VERSION ""

NS_ :

BS_:

BU_: VCM SCIM IC CCM

BO_ 689 VCM_13P_C05: 8 VCM
 SG_ ParkHeaterTimerReleased_stat : 54|2@1+ (1,0) [0|0] ""  CCM
 SG_ Trail2TPMLostCom : 2|2@1+ (1,0) [0|0] ""  IC
 SG_ BrakeInterlockStatus_ISig_5 : 42|2@1+ (1,0) [0|0] ""  IC
 SG_ AutoWheelBrakesDownshiftSugges_I : 36|2@1+ (1,0) [0|0] ""  IC
 SG_ RearAxle2DiffLock_stat_ISig_5 : 34|2@1+ (1,0) [0|0] ""  IC
 SG_ CentralRearDiffLock_stat_ISig_5 : 16|2@1+ (1,0) [0|0] ""  IC
 SG_ TransmissionBrakeMode_ISig_5 : 56|2@1+ (1,0) [0|0] ""  IC
 SG_ PS_HeadLightAdjustment : 14|2@1+ (1,0) [0|0] ""  IC
 SG_ ReducedLoadMode_stat_ISig_5 : 62|2@1+ (1,0) [0|0] ""  IC,CCM
 SG_ FrontWheelDifflockRequest_ISig_5 : 6|2@1+ (1,0) [0|0] ""  IC
 SG_ ABSEBSAmberWarningSignal_ISig_5 : 44|2@1+ (1,0) [0|0] ""  IC
 SG_ DifferentialLockStateFrAxle1_ISi : 32|2@1+ (1,0) [0|0] ""  IC
 SG_ Trail1TPMLostCom : 12|2@1+ (1,0) [0|0] ""  IC
 SG_ TrailerInflationPossible_stat_IS : 50|2@1+ (1,0) [0|0] ""  IC
 SG_ DrivelineRetarderStat_ISig_5 : 24|2@1+ (1,0) [0|0] ""  IC
 SG_ PS_FogLightRear : 4|2@1+ (1,0) [0|0] ""  IC
 SG_ PS_MainBeam : 22|2@1+ (1,0) [0|0] ""  IC
 SG_ DeCompActive_ISig_5 : 26|2@1+ (1,0) [0|0] ""  IC
 SG_ ECSManStandbyStatus_ISig_5 : 30|2@1+ (1,0) [0|0] ""  IC
 SG_ AutoPBRelease_stat_ISig_5 : 46|2@1+ (1,0) [0|0] ""  IC
 SG_ Trail4TPMLostCom : 28|2@1+ (1,0) [0|0] ""  IC
 SG_ EBSRedWarningSignal_ISig_5 : 40|2@1+ (1,0) [0|0] ""  IC
 SG_ DifferentialLockStateCentral_ISi : 52|2@1+ (1,0) [0|0] ""  IC
 SG_ RearAxle3DiffLock_stat_ISig_5 : 20|2@1+ (1,0) [0|0] ""  IC
 SG_ AntiLockBrakingActive_ISig_5 : 10|2@1+ (1,0) [0|0] ""  IC
 SG_ RearAxle1DiffLock_stat_ISig_5 : 0|2@1+ (1,0) [0|0] ""  IC
 SG_ Trail5TPMLostCom : 48|2@1+ (1,0) [0|0] ""  IC
 SG_ PS_PositionLight : 58|2@1+ (1,0) [0|0] ""  IC
 SG_ BatteryCapacity_Ack_ISig_5 : 8|2@1+ (1,0) [0|0] ""  IC
 SG_ Trail3TPMLostCom : 60|2@1+ (1,0) [0|0] ""  IC
 SG_ ParkBrakeWorkshopMode_ISig_5 : 18|2@1+ (1,0) [0|0] ""  IC
 SG_ LowTempClutchInfo_ISig_5 : 38|2@1+ (1,0) [0|0] ""  IC

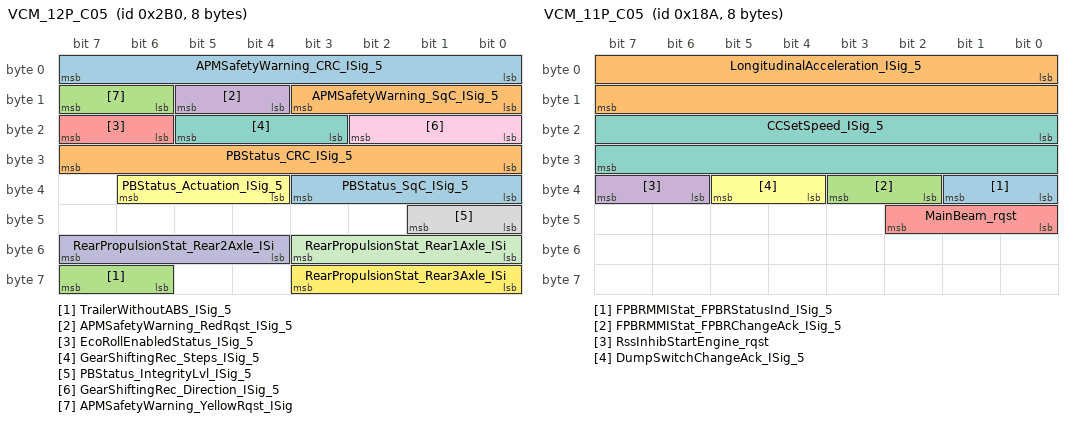
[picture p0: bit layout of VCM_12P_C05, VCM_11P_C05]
BO_ 688 VCM_12P_C05: 8 VCM
 SG_ APMSafetyWarning_CRC_ISig_5 : 0|8@1+ (1,0) [0|255] ""  IC
 SG_ PBStatus_CRC_ISig_5 : 24|8@1+ (1,0) [0|255] ""  IC
 SG_ TrailerWithoutABS_ISig_5 : 62|2@1+ (1,0) [0|0] ""  IC
 SG_ APMSafetyWarning_RedRqst_ISig_5 : 12|2@1+ (1,0) [0|0] ""  IC
 SG_ EcoRollEnabledStatus_ISig_5 : 22|2@1+ (1,0) [0|0] ""  IC
 SG_ PBStatus_Actuation_ISig_5 : 36|3@1+ (1,0) [0|0] ""  IC
 SG_ GearShiftingRec_Steps_ISig_5 : 19|3@1+ (1,0) [0|0] ""  IC
 SG_ PBStatus_IntegrityLvl_ISig_5 : 40|2@1+ (1,0) [0|0] ""  IC
 SG_ GearShiftingRec_Direction_ISig_5 : 16|3@1+ (1,0) [0|0] ""  IC
 SG_ RearPropulsionStat_Rear2Axle_ISi : 52|4@1+ (1,0) [0|0] ""  IC
 SG_ RearPropulsionStat_Rear1Axle_ISi : 48|4@1+ (1,0) [0|0] ""  IC
 SG_ RearPropulsionStat_Rear3Axle_ISi : 56|4@1+ (1,0) [0|0] ""  IC
 SG_ PBStatus_SqC_ISig_5 : 32|4@1+ (1,0) [0|14] "NotApplicable"  IC
 SG_ APMSafetyWarning_SqC_ISig_5 : 8|4@1+ (1,0) [0|14] "NotApplicable"  IC
 SG_ APMSafetyWarning_YellowRqst_ISig : 14|2@1+ (1,0) [0|0] ""  IC

BO_ 394 VCM_11P_C05: 8 VCM
 SG_ FPBRMMIStat_FPBRStatusInd_ISig_5 : 32|2@1+ (1,0) [0|0] ""  SCIM
 SG_ LongitudinalAcceleration_ISig_5 : 0|16@1+ (0.00048828125,-15.687) [-15.687|16.31251171875] "m_per_s_squared"  IC
 SG_ FPBRMMIStat_FPBRChangeAck_ISig_5 : 34|2@1+ (1,0) [0|0] ""  SCIM
 SG_ RssInhibStartEngine_rqst : 38|2@1+ (1,0) [0|0] ""  IC
 SG_ MainBeam_rqst : 40|3@1+ (1,0) [0|0] ""  IC
 SG_ DumpSwitchChangeAck_ISig_5 : 36|2@1+ (1,0) [0|0] ""  SCIM
 SG_ CCSetSpeed_ISig_5 : 16|16@1+ (0.00390625,0) [0|255.99609375] "Km_per_h"  IC

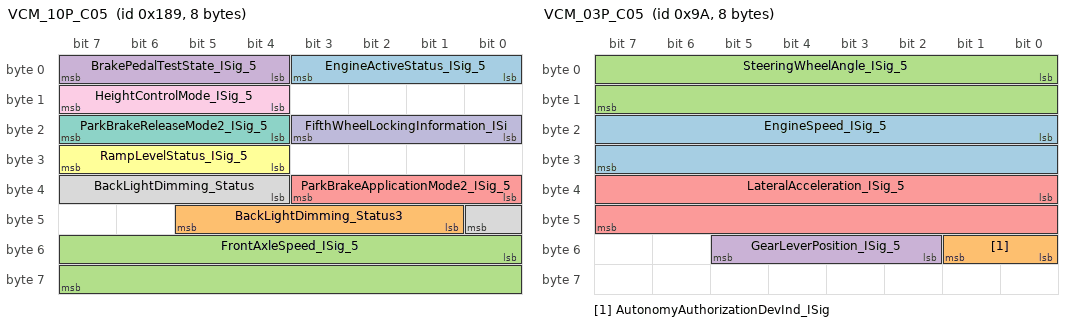
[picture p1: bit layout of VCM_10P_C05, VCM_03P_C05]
BO_ 393 VCM_10P_C05: 8 VCM
 SG_ EngineActiveStatus_ISig_5 : 0|4@1+ (1,0) [0|0] ""  IC
 SG_ BackLightDimming_Status3 : 41|5@1+ (1,0) [0|0] ""  IC
 SG_ FrontAxleSpeed_ISig_5 : 48|16@1+ (0.00390625,0) [0|255.99609375] "Km_per_h"  IC
 SG_ BrakePedalTestState_ISig_5 : 4|4@1+ (1,0) [0|0] ""  IC
 SG_ ParkBrakeApplicationMode2_ISig_5 : 32|4@1+ (1,0) [0|0] ""  IC
 SG_ RampLevelStatus_ISig_5 : 28|4@1+ (1,0) [0|0] ""  IC
 SG_ ParkBrakeReleaseMode2_ISig_5 : 20|4@1+ (1,0) [0|0] ""  IC
 SG_ BackLightDimming_Status : 36|5@1+ (1,0) [0|0] ""  IC
 SG_ HeightControlMode_ISig_5 : 12|4@1+ (1,0) [0|0] ""  IC
 SG_ FifthWheelLockingInformation_ISi : 16|4@1+ (1,0) [0|0] ""  IC

BO_ 392 VCM_09P_C05: 8 VCM
 SG_ FirstAxleLowerPrioSelected_ISig_ : 48|3@1+ (1,0) [0|0] ""  IC
 SG_ ESCState_ISig_5 : 24|3@1+ (1,0) [0|0] ""  IC
 SG_ KneelingInformation_ISig_5 : 60|4@1+ (1,0) [0|0] ""  IC
 SG_ TrailerTest_stat_ISig_5 : 42|3@1+ (1,0) [0|0] ""  IC
 SG_ ThreePosDifflockSwitch_stat : 3|3@1+ (1,0) [0|0] ""  IC
 SG_ HillHolderMode_ISig_5 : 36|3@1+ (1,0) [0|0] ""  IC
 SG_ RampHeightOutsideTargetRange_ISi : 21|3@1+ (1,0) [0|0] ""  IC
 SG_ ShortStopHeater_status_ISig_5 : 39|3@1+ (1,0) [0|0] ""  CCM
 SG_ LuggageAjar_stat : 15|3@1+ (1,0) [0|0] ""  IC
 SG_ LoadDistributionRequestedACK_ISi : 12|3@1+ (1,0) [0|0] ""  SCIM,IC
 SG_ StretchBrake_Stat_ISig_5 : 54|3@1+ (1,0) [0|0] ""  IC
 SG_ MirrorHeatingMode : 9|3@1+ (1,0) [0|0] ""  IC,CCM
 SG_ ESCStatus_ISig_5 : 6|3@1+ (1,0) [0|0] ""  IC
 SG_ DriverRetarderRequest_ISig_5 : 30|3@1+ (1,0) [0|0] ""  IC
 SG_ PBReleaseAcceptance_stat_ISig_5 : 18|3@1+ (1,0) [0|0] ""  IC
 SG_ PSWindowPosition : 0|3@1+ (1,0) [0|0] ""  CCM
 SG_ RideHeightOutsideTargetRange_ISi : 27|3@1+ (1,0) [0|0] ""  IC
 SG_ DriveLevelPosUserInteraction_ISi : 45|3@1+ (1,0) [0|0] ""  IC
 SG_ HillStartAidStatus_ISig_5 : 51|3@1+ (1,0) [0|0] ""  IC

BO_ 391 VCM_08P_C05: 8 VCM
 SG_ AcceleratorPedalTestStatus : 38|3@1+ (1,0) [0|0] ""  IC
 SG_ ESCDriverReq_ISig_5 : 41|3@1+ (1,0) [0|0] ""  IC
 SG_ UnevenLoadWarning_ISig_5 : 12|2@1+ (1,0) [0|0] ""  IC
 SG_ RrInterAxlDiffLockActvnFuncReq_I : 4|2@1+ (1,0) [0|0] ""  IC
 SG_ DoorsAjar_stat_ISig_5 : 44|3@1+ (1,0) [0|0] ""  IC
 SG_ ABSManAutoInhibitionStat_ISig_5 : 50|3@1+ (1,0) [0|0] ""  IC
 SG_ RrInterAxlDiffLockActvnDrvrReq_I : 2|2@1+ (1,0) [0|0] ""  IC
 SG_ EngineOilTempHigh_ISig_5 : 59|3@1+ (1,0) [0|0] ""  IC
 SG_ StartupProhibitStatus_ISig_5 : 0|2@1+ (1,0) [0|0] ""  IC
 SG_ AuxBrakesDwngrdModeInd_rqst : 26|3@1+ (1,0) [0|0] ""  IC
 SG_ ElectricalLoadReduction_rqst_ISi : 32|3@1+ (1,0) [0|0] ""  CCM
 SG_ LoadDistributionChangeACK_ISig_5 : 20|3@1+ (1,0) [0|0] ""  IC,SCIM
 SG_ FerryFunctionStatus_ISig_5 : 29|3@1+ (1,0) [0|0] ""  SCIM,IC
 SG_ ClutchOverloadStatus_ISig_5 : 10|2@1+ (1,0) [0|0] ""  IC
 SG_ RollerBenchModeStatus_ISig_5 : 6|2@1+ (1,0) [0|0] ""  IC
 SG_ LoadDistributionALDChangeACK_ISi : 35|3@1+ (1,0) [0|0] ""  IC,SCIM
 SG_ EngineSpeedControlStatus : 47|3@1+ (1,0) [0|0] ""  IC
 SG_ DTCActive_ISig_5 : 8|2@1+ (1,0) [0|0] ""  IC

BO_ 390 VCM_07P_C05: 8 VCM
 SG_ PS_SevereEngAndBrkOverspdWarn_IS : 6|2@1+ (1,0) [0|0] ""  IC
 SG_ RearFog_Indication : 14|2@1+ (1,0) [0|0] ""  SCIM
 SG_ SasAdaptationInProgress_ISig_5 : 46|2@1+ (1,0) [0|0] ""  IC
 SG_ SplitBoxDifflockActvnDrvrRqst_IS : 50|2@1+ (1,0) [0|0] ""  IC
 SG_ EcoRollActiveStatus_ISig_5 : 36|2@1+ (1,0) [0|0] ""  IC
 SG_ PloughLampModeStatus_ISig_5 : 40|2@1+ (1,0) [0|0] ""  IC
 SG_ RrRrItrWhlDiffLckActvnDrvrReq_IS : 26|2@1+ (1,0) [0|0] ""  IC
 SG_ DrvrRetarderBrakeProgram_rqst_IS : 62|2@1+ (1,0) [0|0] ""  IC
 SG_ PS_EngOverSpeedSevereWarning_ISi : 38|2@1+ (1,0) [0|0] ""  IC
 SG_ ParkBrakeReleasePossible_stat_IS : 32|2@1+ (1,0) [0|0] ""  IC
 SG_ StoreIdleValue_ISig_5 : 34|2@1+ (1,0) [0|0] ""  IC
 SG_ AutRrAxleDiffLockActvnDrvrReq_IS : 42|2@1+ (1,0) [0|0] ""  IC
 SG_ TransmLowRangeSenseSwitch_ISig_5 : 28|2@1+ (1,0) [0|0] ""  IC
 SG_ PBStatusDisplay_cmd_ISig_5 : 44|2@1+ (1,0) [0|0] ""  IC
 SG_ AutoRearAxleDiffLockFnc_stat_ISi : 56|2@1+ (1,0) [0|0] ""  IC
 SG_ PoorBrakePerformanceWarning_ISig : 8|2@1+ (1,0) [0|0] ""  IC
 SG_ FrontParkBrakeOverrideInd_ISig_5 : 52|2@1+ (1,0) [0|0] ""  IC
 SG_ ProhibitControlStatus_ISig_5 : 10|2@1+ (1,0) [0|0] ""  IC
 SG_ PositionLightRequest_status : 2|2@1+ (1,0) [0|0] ""  IC
 SG_ DoubleFrontAxleSteeringWarning_I : 54|2@1+ (1,0) [0|0] ""  IC
 SG_ TrailerABSStatus_ISig_5 : 20|2@1+ (1,0) [0|0] ""  IC
 SG_ LoadCutOffIndication_cmd_ISig_5 : 60|2@1+ (1,0) [0|0] ""  IC
 SG_ PtosStatus_ISig_5 : 12|2@1+ (1,0) [0|0] ""  IC,CCM
 SG_ REM_PhoneButtonInd_cmd : 58|2@1+ (1,0) [0|0] ""  IC
 SG_ TrailerBrake_Stat_ISig_5 : 48|2@1+ (1,0) [0|0] ""  IC
 SG_ SEM2_PhoneButtonInd_cmd : 30|2@1+ (1,0) [0|0] ""  IC
 SG_ GearRangeUnengaged_ISig_5 : 16|2@1+ (1,0) [0|0] ""  IC
 SG_ ABSOffRoadStatus_ISig_5 : 24|2@1+ (1,0) [0|0] ""  IC
 SG_ DrvrRetarderBrakeBlending_rqst_I : 18|2@1+ (1,0) [0|0] ""  IC

BO_ 389 VCM_06P_C05: 8 VCM
 SG_ PHTimerRqstAck_Minutes : 24|8@1+ (1,0) [0|255] "min"  CCM
 SG_ RearAxleDiffLockActvnDrvrReq_ISi : 56|2@1+ (1,0) [0|0] ""  IC
 SG_ FrRrItrWhlDiffLckActvnDrvrReq_IS : 46|2@1+ (1,0) [0|0] ""  IC
 SG_ DriverLocation_CRC_ISig_5 : 0|8@1+ (1,0) [0|255] ""  IC
 SG_ RegenInhibDueHeight_ISig_5 : 48|2@1+ (1,0) [0|0] ""  IC
 SG_ DriverLocation_Status_ISig_5 : 12|4@1+ (1,0) [0|0] ""  IC
 SG_ PHTimerRqstAck_Hours : 32|8@1+ (1,0) [0|255] "h"  CCM
 SG_ PoorAirPressureInfo_ISig_5 : 60|2@1+ (1,0) [0|0] ""  IC
 SG_ DriverLocation_SqC_ISig_5 : 8|4@1+ (1,0) [0|14] "NotApplicable"  IC
 SG_ XRSLControllerMode_ISig_5 : 52|2@1+ (1,0) [0|0] ""  IC
 SG_ PHTimerRqstAck_DayOfWeekRq : 40|4@1+ (1,0) [0|0] ""  CCM
 SG_ VIN_rqst_ISig_5 : 62|1@1+ (1,0) [0|0] ""  IC
 SG_ PHTimerRqstAck_CurrentOp : 44|2@1+ (1,0) [0|0] ""  CCM
 SG_ DriverLocation_ConfidenceLvl_ISi : 16|2@1+ (1,0) [0|0] ""  IC
 SG_ PS_EngineBrakeOverSpeedWarning_I : 58|2@1+ (1,0) [0|0] ""  IC
 SG_ TrcnCtrlSlipperyRoadWarning_ISig : 50|2@1+ (1,0) [0|0] ""  IC
 SG_ TransmissionAirPressureLow_ISig_ : 54|2@1+ (1,0) [0|0] ""  IC

BO_ 158 VCM_05P_C05: 8 VCM
 SG_ SecuredNeutralPosition_ISig_5 : 38|2@1+ (1,0) [0|0] ""  IC
 SG_ MirrorSelectLeftWideBtn_stat : 28|2@1+ (1,0) [0|0] ""  IC
 SG_ BunkH1AudioOnOff_ButtonStatus : 30|2@1+ (1,0) [0|0] ""  IC
 SG_ OverSteerGuidanceStatus_ISig_5 : 10|2@1+ (1,0) [0|0] ""  IC
 SG_ MirrorSelectLeftMainBtn_stat : 44|2@1+ (1,0) [0|0] ""  IC
 SG_ LECM_CabClim_Auto_BtnStat : 36|2@1+ (1,0) [0|0] ""  IC
 SG_ LECM_Display_Navi_OK_BtnStat : 20|2@1+ (1,0) [0|0] ""  IC
 SG_ LECM_CabClim_AC_BtnStat : 46|2@1+ (1,0) [0|0] ""  IC
 SG_ LECMCabClimSetTempSelectGuiReq : 22|2@1+ (1,0) [0|0] ""  IC
 SG_ MirrorSelectRightMainBtn_stat : 50|2@1+ (1,0) [0|0] ""  IC
 SG_ DaytimeRunningLight_Indication : 24|2@1+ (1,0) [0|0] ""  SCIM
 SG_ DrivingLight_Indication : 58|2@1+ (1,0) [0|0] ""  SCIM
 SG_ FrontFog_Indication : 32|2@1+ (1,0) [0|0] ""  SCIM
 SG_ KeyfobPreTripButtonStatus : 4|2@1+ (1,0) [0|0] ""  IC
 SG_ MirrorSelectRightWideBtn_stat : 26|2@1+ (1,0) [0|0] ""  IC
 SG_ ParkingLight_Indication : 2|2@1+ (1,0) [0|0] ""  SCIM
 SG_ DrivingLightPlus_Indication : 60|2@1+ (1,0) [0|0] ""  SCIM
 SG_ BlackPanelMode_ButtonStatus : 14|2@1+ (1,0) [0|0] ""  IC
 SG_ ParkBrakeActuationStatus_ISig_5 : 16|3@1+ (1,0) [0|0] ""  CCM
 SG_ LECM_CabClim_FrPwr_BtnStat : 34|2@1+ (1,0) [0|0] ""  IC
 SG_ LECM_CabClim_Pwr_BtnStat : 0|2@1+ (1,0) [0|0] ""  IC
 SG_ BlackPanelMode_ButtonStatus3 : 8|2@1+ (1,0) [0|0] ""  IC
 SG_ LECM_CabClim_Sync_GuiReq : 40|2@1+ (1,0) [0|0] ""  IC
 SG_ LiftAxle1AutoLiftSelected_ISig_5 : 54|2@1+ (1,0) [0|0] ""  IC
 SG_ LECM_Ent_OnOff_BtnStat : 52|2@1+ (1,0) [0|0] ""  IC

BO_ 156 VCM_04P_C05: 8 VCM
 SG_ LiftAxle2LowerACK_ISig_5 : 32|3@1+ (1,0) [0|0] ""  IC
 SG_ LiftAxle2PositionStatus_ISig_5 : 20|3@1+ (1,0) [0|0] ""  IC,SCIM
 SG_ LiftAxle2LiftFuncSelected_ISig_5 : 53|3@1+ (1,0) [0|0] ""  IC
 SG_ PassengerDoorAjar_stat : 35|3@1+ (1,0) [0|0] ""  CCM
 SG_ LevelControlInformation_ISig_5 : 56|4@1+ (1,0) [0|0] ""  IC,SCIM
 SG_ LiftAxle1LowerACK_ISig_5 : 38|3@1+ (1,0) [0|0] ""  IC
 SG_ WiperModeStatus_ISig_5 : 41|3@1+ (1,0) [0|0] ""  IC,CCM
 SG_ Washing_HMI_rqst : 60|2@1+ (1,0) [0|0] ""  CCM
 SG_ LiftAxle2AutoLiftSelected_ISig_5 : 8|2@1+ (1,0) [0|0] ""  IC
 SG_ ReverseGearEngaged_ISig_5 : 10|2@1+ (1,0) [0|0] ""  CCM
 SG_ LiftAxle1PositionStatus_ISig_5 : 17|3@1+ (1,0) [0|0] ""  SCIM,IC
 SG_ ACC_Status_ISig_5 : 47|3@1+ (1,0) [0|0] ""  IC
 SG_ LECM_CabClim_MaxDef_GuiReq : 6|2@1+ (1,0) [0|0] ""  IC
 SG_ RegenerationSwitchStatus : 23|3@1+ (1,0) [0|0] ""  IC
 SG_ DSWindowPosition : 29|3@1+ (1,0) [0|0] ""  CCM
 SG_ GearSplit_Status_ISig_5 : 0|2@1+ (1,0) [0|0] ""  IC
 SG_ KeyPosition_ISig_5 : 44|3@1+ (1,0) [0|0] ""  IC
 SG_ LiftAxle1LiftFuncSelected_ISig_5 : 50|3@1+ (1,0) [0|0] ""  IC
 SG_ LiftAxle2UpRequestACK_ISig_5 : 26|3@1+ (1,0) [0|0] ""  SCIM,IC
 SG_ PreTrip_ButtonStat3 : 12|2@1+ (1,0) [0|0] ""  IC
 SG_ LiftAxle1UpRequestACK_ISig_5 : 14|3@1+ (1,0) [0|0] ""  SCIM,IC

BO_ 154 VCM_03P_C05: 8 VCM
 SG_ EngineSpeed_ISig_5 : 16|16@1+ (0.125,0) [0|8191.875] "rpm"  IC,CCM
 SG_ AutonomyAuthorizationDevInd_ISig : 48|2@1+ (1,0) [0|0] ""  SCIM
 SG_ SteeringWheelAngle_ISig_5 : 0|16@1+ (0.0009765625,-31.374) [-31.374|32.6250234375] "rad"  IC
 SG_ GearLeverPosition_ISig_5 : 50|4@1+ (1,0) [0|0] ""  IC
 SG_ LateralAcceleration_ISig_5 : 32|16@1+ (0.00048828125,-15.687) [-15.687|16.31251171875] "m_per_s_squared"  IC

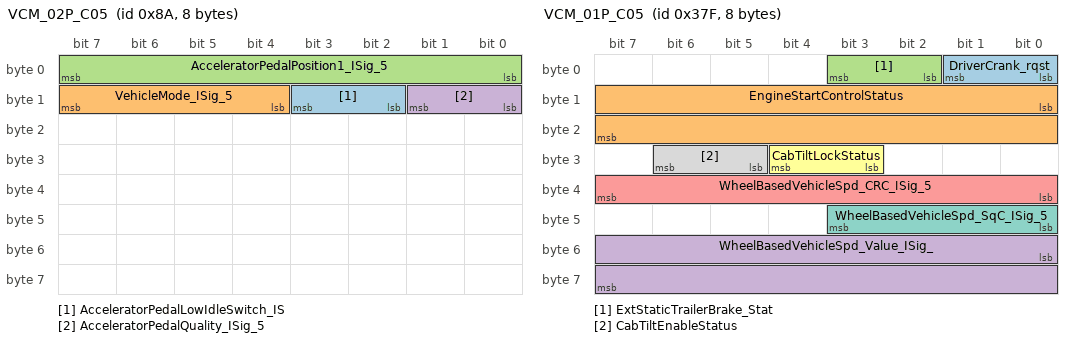
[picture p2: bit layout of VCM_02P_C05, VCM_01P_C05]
BO_ 138 VCM_02P_C05: 8 VCM
 SG_ AcceleratorPedalLowIdleSwitch_IS : 10|2@1+ (1,0) [0|0] ""  IC
 SG_ VehicleMode_ISig_5 : 12|4@1+ (1,0) [0|0] ""  SCIM,IC,CCM
 SG_ AcceleratorPedalPosition1_ISig_5 : 0|8@1+ (0.4,0) [0|102] "Percent"  IC
 SG_ AcceleratorPedalQuality_ISig_5 : 8|2@1+ (1,0) [0|0] ""  IC

BO_ 895 VCM_01P_C05: 8 VCM
 SG_ DriverCrank_rqst : 0|2@1+ (1,0) [0|0] ""  IC
 SG_ EngineStartControlStatus : 8|16@1+ (1,0) [0|65535] "NotApplicable"  IC
 SG_ ExtStaticTrailerBrake_Stat : 2|2@1+ (1,0) [0|0] ""  IC
 SG_ WheelBasedVehicleSpd_Value_ISig_ : 48|16@1+ (0.00390625,0) [0|255.99609375] "Km_per_h"  IC
 SG_ WheelBasedVehicleSpd_CRC_ISig_5 : 32|8@1+ (1,0) [0|255] ""  IC
 SG_ CabTiltLockStatus : 27|2@1+ (1,0) [0|0] ""  IC
 SG_ WheelBasedVehicleSpd_SqC_ISig_5 : 40|4@1+ (1,0) [0|14] "NotApplicable"  IC
 SG_ CabTiltEnableStatus : 29|2@1+ (1,0) [0|0] ""  SCIM

BO_ 2671902706 TesterFuncDiagMsg_C05: 8 VCM
 SG_ FuncDiagDataTester_ISig_5 : 0|64@1+ (1,0) [0|0] ""  CCM,IC,SCIM

BO_ 2671902708 TesterFuncDiagMsgF4_C05: 8 VCM
 SG_ FuncDiagDataIntTesterF4_ISig_5 : 0|64@1+ (1,0) [0|0] ""  CCM,IC,SCIM

BO_ 1104 SCIM_P01_C05: 8 SCIM
 SG_ CabTilt_rqst : 0|2@1+ (1,0) [0|0] ""  VCM
 SG_ PassengersSeatBelt_ISig_5 : 2|3@1+ (1,0) [0|0] ""  VCM,IC

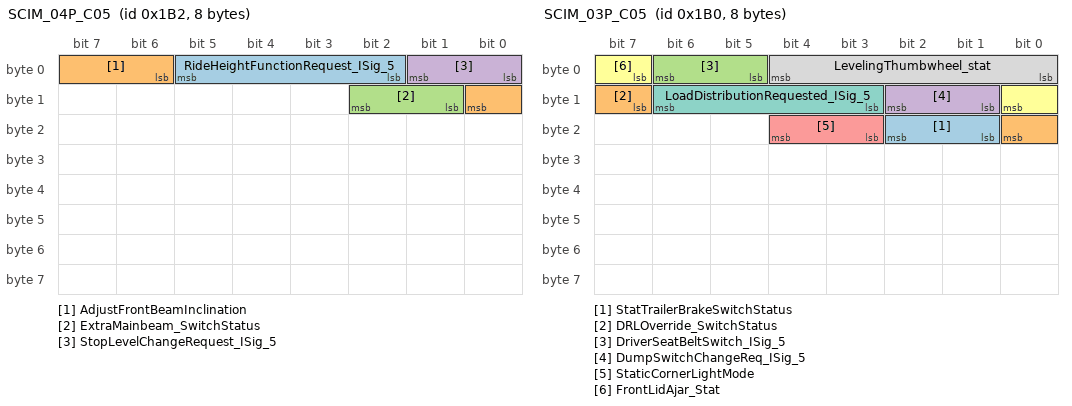
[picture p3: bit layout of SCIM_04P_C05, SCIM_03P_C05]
BO_ 434 SCIM_04P_C05: 8 SCIM
 SG_ RideHeightFunctionRequest_ISig_5 : 2|4@1+ (1,0) [0|0] ""  VCM
 SG_ AdjustFrontBeamInclination : 6|3@1+ (1,0) [0|0] ""  VCM
 SG_ ExtraMainbeam_SwitchStatus : 9|2@1+ (1,0) [0|0] ""  VCM
 SG_ StopLevelChangeRequest_ISig_5 : 0|2@1+ (1,0) [0|0] ""  VCM

BO_ 432 SCIM_03P_C05: 8 SCIM
 SG_ StatTrailerBrakeSwitchStatus : 17|2@1+ (1,0) [0|0] ""  VCM
 SG_ DRLOverride_SwitchStatus : 15|2@1+ (1,0) [0|0] ""  VCM
 SG_ DriverSeatBeltSwitch_ISig_5 : 5|2@1+ (1,0) [0|0] ""  VCM,IC
 SG_ DumpSwitchChangeReq_ISig_5 : 9|2@1+ (1,0) [0|0] ""  VCM
 SG_ StaticCornerLightMode : 19|2@1+ (1,0) [0|0] ""  VCM
 SG_ FrontLidAjar_Stat : 7|2@1+ (1,0) [0|0] ""  VCM
 SG_ LoadDistributionRequested_ISig_5 : 11|4@1+ (1,0) [0|0] ""  VCM
 SG_ LevelingThumbwheel_stat : 0|5@1+ (1,0) [0|0] ""  VCM

BA_DEF_ BO_  "GenMsgStartDelayTime" INT 0 0;
BA_DEF_ BO_  "GenMsgDelayTime" INT 0 0;
BA_DEF_ BO_  "GenMsgCycleTime" INT 0 0;
BA_DEF_ BO_  "GenMsgSendType" ENUM  "Cyclic","NotUsed","NotUsed","NotUsed","NotUsed","NotUsed","NotUsed","IfActive","NoMsgSendType","NotUsed";
BA_DEF_ SG_  "GenSigStartValue" INT 0 0;
BA_DEF_ SG_  "GenSigCycleTimeActive" INT 0 0;
BA_DEF_ SG_  "GenSigCycleTime" INT 0 0;
BA_DEF_ SG_  "GenSigSendType" ENUM  "Cyclic","OnWrite","OnWriteWithRepetition","OnChange","OnChangeWithRepetition","IfActive","IfActiveWithRepetition","NoSigSendType","NotUsed","NotUsed","NotUsed","NotUsed","NotUsed";
BA_DEF_ BO_  "VFrameFormat" ENUM  "StandardCAN","ExtendedCAN","reserved","J1939PG","reserved","reserved","reserved","reserved","reserved","reserved","reserved","reserved","reserved","reserved","StandardCAN_FD","ExtendedCAN_FD";
BA_DEF_ SG_  "SigType" ENUM  "Default","Range","RangeSigned","ASCII","Discrete","Control","ReferencePGN","DTC","StringDelimiter","StringLength","StringLengthControl";
BA_DEF_ BO_  "NmAsrMessage" ENUM  "No","Yes";
BA_DEF_ SG_  "NeedsUpdateBit" ENUM  "No","Yes";
BA_DEF_ SG_  "MmAnSignal" ENUM  "No","Yes";
BA_DEF_ SG_  "GenSigMaxLatency" INT 0 65535;
BA_DEF_ SG_  "GenSigILSupport" ENUM  "Yes","No";
BA_DEF_ BO_  "GenMsgILSupport" ENUM  "No","Yes";
BA_DEF_ SG_  "E2EProfile" STRING ;
BA_DEF_ SG_  "E2EDataLength" INT 0 65535;
BA_DEF_ SG_  "E2EDataId" INT 0 65535;
BA_DEF_ BO_  "DiagUUDTResponse" ENUM  "No","Yes";
BA_DEF_ BO_  "DiagState" ENUM  "No","Yes";
BA_DEF_ BO_  "DiagResponse" ENUM  "No","Yes";
BA_DEF_ BO_  "DiagRequest" ENUM  "No","Yes";
BA_DEF_ BO_  "DiagConnection" HEX 0 65535;
BA_DEF_ BO_  "CanTpFcFrameId" HEX 0 2147483647;
BA_DEF_ BO_  "CanTpBs" INT 0 255;
BA_DEF_ SG_  "SystemSignalLongSymbol" STRING ;
BA_DEF_REL_ BU_SG_REL_  "GenSigTimeoutTime" INT 0 65535;
BA_DEF_REL_ BU_SG_REL_  "GenSigFirstTimeoutTime" INT 0 65535;
BA_DEF_DEF_  "GenMsgStartDelayTime" 0;
BA_DEF_DEF_  "GenMsgDelayTime" 0;
BA_DEF_DEF_  "GenMsgCycleTime" 0;
BA_DEF_DEF_  "GenMsgSendType" "Cyclic";
BA_DEF_DEF_  "GenSigStartValue" 0;
BA_DEF_DEF_  "GenSigCycleTimeActive" 0;
BA_DEF_DEF_  "GenSigCycleTime" 0;
BA_DEF_DEF_  "GenSigSendType" "Cyclic";
BA_DEF_DEF_  "VFrameFormat" "ExtendedCAN";
BA_DEF_DEF_  "SigType" "Default";
BA_DEF_DEF_  "NmAsrMessage" "No";
BA_DEF_DEF_  "NeedsUpdateBit" "No";
BA_DEF_DEF_  "MmAnSignal" "No";
BA_DEF_DEF_  "GenSigMaxLatency" 0;
BA_DEF_DEF_  "GenSigILSupport" "Yes";
BA_DEF_DEF_  "GenMsgILSupport" "Yes";
BA_DEF_DEF_  "E2EProfile" "none";
BA_DEF_DEF_  "E2EDataLength" 0;
BA_DEF_DEF_  "E2EDataId" 0;
BA_DEF_DEF_  "DiagUUDTResponse" "No";
BA_DEF_DEF_  "DiagState" "No";
BA_DEF_DEF_  "DiagResponse" "No";
BA_DEF_DEF_  "DiagRequest" "No";
BA_DEF_DEF_  "DiagConnection" 0;
BA_DEF_DEF_  "CanTpFcFrameId" 2147483647;
BA_DEF_DEF_  "CanTpBs" 255;
BA_DEF_DEF_REL_ "GenSigTimeoutTime" 0;
BA_DEF_DEF_REL_ "GenSigFirstTimeoutTime" 0;
BA_DEF_DEF_  "SystemSignalLongSymbol" "";
BA_ "VFrameFormat" BO_ 689 0;
BA_ "GenMsgCycleTime" BO_ 689 100;
BA_ "GenMsgStartDelayTime" BO_ 689 10;
BA_ "VFrameFormat" BO_ 688 0;
BA_ "GenMsgCycleTime" BO_ 688 100;
BA_ "VFrameFormat" BO_ 394 0;
BA_ "GenMsgCycleTime" BO_ 394 50;
BA_ "GenMsgStartDelayTime" BO_ 394 35;
BA_ "VFrameFormat" BO_ 393 0;
BA_ "GenMsgCycleTime" BO_ 393 50;
BA_ "GenMsgStartDelayTime" BO_ 393 30;
BA_ "VFrameFormat" BO_ 392 0;
BA_ "GenMsgCycleTime" BO_ 392 50;
BA_ "GenMsgStartDelayTime" BO_ 392 25;
BA_ "VFrameFormat" BO_ 391 0;
BA_ "GenMsgCycleTime" BO_ 391 50;
BA_ "GenMsgStartDelayTime" BO_ 391 20;
BA_ "VFrameFormat" BO_ 390 0;
BA_ "GenMsgCycleTime" BO_ 390 50;
BA_ "GenMsgStartDelayTime" BO_ 390 15;
BA_ "VFrameFormat" BO_ 389 0;
BA_ "GenMsgCycleTime" BO_ 389 50;
BA_ "GenMsgStartDelayTime" BO_ 389 10;
BA_ "VFrameFormat" BO_ 158 0;
BA_ "GenMsgCycleTime" BO_ 158 20;
BA_ "GenMsgStartDelayTime" BO_ 158 10;
BA_ "VFrameFormat" BO_ 156 0;
BA_ "GenMsgCycleTime" BO_ 156 20;
BA_ "GenMsgStartDelayTime" BO_ 156 5;
BA_ "VFrameFormat" BO_ 154 0;
BA_ "GenMsgCycleTime" BO_ 154 20;
BA_ "VFrameFormat" BO_ 138 0;
BA_ "GenMsgCycleTime" BO_ 138 10;
BA_ "VFrameFormat" BO_ 895 0;
BA_ "GenMsgCycleTime" BO_ 895 50;
BA_ "GenMsgStartDelayTime" BO_ 895 5;
BA_ "DiagConnection" BO_ 2671902706 62082;
BA_ "DiagState" BO_ 2671902706 1;
BA_ "GenMsgILSupport" BO_ 2671902706 0;
BA_ "GenMsgSendType" BO_ 2671902706 8;
BA_ "DiagConnection" BO_ 2671902708 62719;
BA_ "DiagState" BO_ 2671902708 1;
BA_ "GenMsgILSupport" BO_ 2671902708 0;
BA_ "GenMsgSendType" BO_ 2671902708 8;
BA_ "VFrameFormat" BO_ 1104 0;
BA_ "GenMsgCycleTime" BO_ 1104 100;
BA_ "GenMsgStartDelayTime" BO_ 1104 10;
BA_ "VFrameFormat" BO_ 434 0;
BA_ "GenMsgCycleTime" BO_ 434 20;
BA_ "VFrameFormat" BO_ 432 0;
BA_ "GenMsgCycleTime" BO_ 432 50;
BA_ "GenMsgStartDelayTime" BO_ 432 25;
BA_ "GenSigCycleTime" SG_ 689 ParkHeaterTimerReleased_stat 100;
BA_ "GenSigCycleTimeActive" SG_ 689 ParkHeaterTimerReleased_stat 100;
BA_ "GenSigStartValue" SG_ 689 ParkHeaterTimerReleased_stat 3;
BA_ "GenSigMaxLatency" SG_ 689 ParkHeaterTimerReleased_stat 100;
BA_ "GenSigCycleTime" SG_ 689 Trail2TPMLostCom 100;
BA_ "GenSigCycleTimeActive" SG_ 689 Trail2TPMLostCom 100;
BA_ "GenSigStartValue" SG_ 689 Trail2TPMLostCom 3;
BA_ "GenSigMaxLatency" SG_ 689 Trail2TPMLostCom 100;
BA_ "GenSigCycleTime" SG_ 689 BrakeInterlockStatus_ISig_5 100;
BA_ "GenSigCycleTimeActive" SG_ 689 BrakeInterlockStatus_ISig_5 100;
BA_ "GenSigStartValue" SG_ 689 BrakeInterlockStatus_ISig_5 3;
BA_ "GenSigMaxLatency" SG_ 689 BrakeInterlockStatus_ISig_5 100;
BA_ "GenSigCycleTime" SG_ 689 AutoWheelBrakesDownshiftSugges_I 100;
BA_ "GenSigCycleTimeActive" SG_ 689 AutoWheelBrakesDownshiftSugges_I 100;
BA_ "GenSigStartValue" SG_ 689 AutoWheelBrakesDownshiftSugges_I 3;
BA_ "GenSigMaxLatency" SG_ 689 AutoWheelBrakesDownshiftSugges_I 100;
BA_ "SystemSignalLongSymbol" SG_ 689 AutoWheelBrakesDownshiftSugges_I "AutoWheelBrakesDownshiftSugges_ISig_5";
BA_ "GenSigCycleTime" SG_ 689 RearAxle2DiffLock_stat_ISig_5 100;
BA_ "GenSigCycleTimeActive" SG_ 689 RearAxle2DiffLock_stat_ISig_5 100;
BA_ "GenSigStartValue" SG_ 689 RearAxle2DiffLock_stat_ISig_5 3;
BA_ "GenSigMaxLatency" SG_ 689 RearAxle2DiffLock_stat_ISig_5 100;
BA_ "GenSigCycleTime" SG_ 689 CentralRearDiffLock_stat_ISig_5 100;
BA_ "GenSigCycleTimeActive" SG_ 689 CentralRearDiffLock_stat_ISig_5 100;
BA_ "GenSigStartValue" SG_ 689 CentralRearDiffLock_stat_ISig_5 3;
BA_ "GenSigMaxLatency" SG_ 689 CentralRearDiffLock_stat_ISig_5 100;
BA_ "GenSigCycleTime" SG_ 689 TransmissionBrakeMode_ISig_5 100;
BA_ "GenSigCycleTimeActive" SG_ 689 TransmissionBrakeMode_ISig_5 100;
BA_ "GenSigStartValue" SG_ 689 TransmissionBrakeMode_ISig_5 3;
BA_ "GenSigMaxLatency" SG_ 689 TransmissionBrakeMode_ISig_5 100;
BA_ "GenSigCycleTime" SG_ 689 PS_HeadLightAdjustment 100;
BA_ "GenSigCycleTimeActive" SG_ 689 PS_HeadLightAdjustment 100;
BA_ "GenSigStartValue" SG_ 689 PS_HeadLightAdjustment 3;
BA_ "GenSigMaxLatency" SG_ 689 PS_HeadLightAdjustment 100;
BA_ "GenSigCycleTime" SG_ 689 ReducedLoadMode_stat_ISig_5 100;
BA_ "GenSigCycleTimeActive" SG_ 689 ReducedLoadMode_stat_ISig_5 100;
BA_ "GenSigStartValue" SG_ 689 ReducedLoadMode_stat_ISig_5 3;
BA_ "GenSigMaxLatency" SG_ 689 ReducedLoadMode_stat_ISig_5 100;
BA_ "GenSigCycleTime" SG_ 689 FrontWheelDifflockRequest_ISig_5 100;
BA_ "GenSigCycleTimeActive" SG_ 689 FrontWheelDifflockRequest_ISig_5 100;
BA_ "GenSigStartValue" SG_ 689 FrontWheelDifflockRequest_ISig_5 3;
BA_ "GenSigMaxLatency" SG_ 689 FrontWheelDifflockRequest_ISig_5 100;
BA_ "GenSigCycleTime" SG_ 689 ABSEBSAmberWarningSignal_ISig_5 100;
BA_ "GenSigCycleTimeActive" SG_ 689 ABSEBSAmberWarningSignal_ISig_5 100;
BA_ "GenSigStartValue" SG_ 689 ABSEBSAmberWarningSignal_ISig_5 3;
BA_ "GenSigMaxLatency" SG_ 689 ABSEBSAmberWarningSignal_ISig_5 100;
BA_ "GenSigCycleTime" SG_ 689 DifferentialLockStateFrAxle1_ISi 100;
BA_ "GenSigCycleTimeActive" SG_ 689 DifferentialLockStateFrAxle1_ISi 100;
BA_ "GenSigStartValue" SG_ 689 DifferentialLockStateFrAxle1_ISi 3;
BA_ "GenSigMaxLatency" SG_ 689 DifferentialLockStateFrAxle1_ISi 100;
BA_ "SystemSignalLongSymbol" SG_ 689 DifferentialLockStateFrAxle1_ISi "DifferentialLockStateFrAxle1_ISig_5";
BA_ "GenSigCycleTime" SG_ 689 Trail1TPMLostCom 100;
BA_ "GenSigCycleTimeActive" SG_ 689 Trail1TPMLostCom 100;
BA_ "GenSigStartValue" SG_ 689 Trail1TPMLostCom 3;
BA_ "GenSigMaxLatency" SG_ 689 Trail1TPMLostCom 100;
BA_ "GenSigCycleTime" SG_ 689 TrailerInflationPossible_stat_IS 100;
BA_ "GenSigCycleTimeActive" SG_ 689 TrailerInflationPossible_stat_IS 100;
BA_ "GenSigStartValue" SG_ 689 TrailerInflationPossible_stat_IS 3;
BA_ "GenSigMaxLatency" SG_ 689 TrailerInflationPossible_stat_IS 100;
BA_ "SystemSignalLongSymbol" SG_ 689 TrailerInflationPossible_stat_IS "TrailerInflationPossible_stat_ISig_5";
BA_ "GenSigCycleTime" SG_ 689 DrivelineRetarderStat_ISig_5 100;
BA_ "GenSigCycleTimeActive" SG_ 689 DrivelineRetarderStat_ISig_5 100;
BA_ "GenSigStartValue" SG_ 689 DrivelineRetarderStat_ISig_5 3;
BA_ "GenSigMaxLatency" SG_ 689 DrivelineRetarderStat_ISig_5 100;
BA_ "GenSigCycleTime" SG_ 689 PS_FogLightRear 100;
BA_ "GenSigCycleTimeActive" SG_ 689 PS_FogLightRear 100;
BA_ "GenSigStartValue" SG_ 689 PS_FogLightRear 3;
BA_ "GenSigMaxLatency" SG_ 689 PS_FogLightRear 100;
BA_ "GenSigCycleTime" SG_ 689 PS_MainBeam 100;
BA_ "GenSigCycleTimeActive" SG_ 689 PS_MainBeam 100;
BA_ "GenSigStartValue" SG_ 689 PS_MainBeam 3;
BA_ "GenSigMaxLatency" SG_ 689 PS_MainBeam 100;
BA_ "GenSigCycleTime" SG_ 689 DeCompActive_ISig_5 100;
BA_ "GenSigCycleTimeActive" SG_ 689 DeCompActive_ISig_5 100;
BA_ "GenSigStartValue" SG_ 689 DeCompActive_ISig_5 3;
BA_ "GenSigMaxLatency" SG_ 689 DeCompActive_ISig_5 100;
BA_ "GenSigCycleTime" SG_ 689 ECSManStandbyStatus_ISig_5 100;
BA_ "GenSigCycleTimeActive" SG_ 689 ECSManStandbyStatus_ISig_5 100;
BA_ "GenSigStartValue" SG_ 689 ECSManStandbyStatus_ISig_5 3;
BA_ "GenSigMaxLatency" SG_ 689 ECSManStandbyStatus_ISig_5 100;
BA_ "GenSigCycleTime" SG_ 689 AutoPBRelease_stat_ISig_5 100;
BA_ "GenSigCycleTimeActive" SG_ 689 AutoPBRelease_stat_ISig_5 100;
BA_ "GenSigStartValue" SG_ 689 AutoPBRelease_stat_ISig_5 3;
BA_ "GenSigMaxLatency" SG_ 689 AutoPBRelease_stat_ISig_5 100;
BA_ "GenSigCycleTime" SG_ 689 Trail4TPMLostCom 100;
BA_ "GenSigCycleTimeActive" SG_ 689 Trail4TPMLostCom 100;
BA_ "GenSigStartValue" SG_ 689 Trail4TPMLostCom 3;
BA_ "GenSigMaxLatency" SG_ 689 Trail4TPMLostCom 100;
BA_ "GenSigCycleTime" SG_ 689 EBSRedWarningSignal_ISig_5 100;
BA_ "GenSigCycleTimeActive" SG_ 689 EBSRedWarningSignal_ISig_5 100;
BA_ "GenSigStartValue" SG_ 689 EBSRedWarningSignal_ISig_5 3;
BA_ "GenSigMaxLatency" SG_ 689 EBSRedWarningSignal_ISig_5 100;
BA_ "GenSigCycleTime" SG_ 689 DifferentialLockStateCentral_ISi 100;
BA_ "GenSigCycleTimeActive" SG_ 689 DifferentialLockStateCentral_ISi 100;
BA_ "GenSigStartValue" SG_ 689 DifferentialLockStateCentral_ISi 3;
BA_ "GenSigMaxLatency" SG_ 689 DifferentialLockStateCentral_ISi 100;
BA_ "SystemSignalLongSymbol" SG_ 689 DifferentialLockStateCentral_ISi "DifferentialLockStateCentral_ISig_5";
BA_ "GenSigCycleTime" SG_ 689 RearAxle3DiffLock_stat_ISig_5 100;
BA_ "GenSigCycleTimeActive" SG_ 689 RearAxle3DiffLock_stat_ISig_5 100;
BA_ "GenSigStartValue" SG_ 689 RearAxle3DiffLock_stat_ISig_5 3;
BA_ "GenSigMaxLatency" SG_ 689 RearAxle3DiffLock_stat_ISig_5 100;
BA_ "GenSigCycleTime" SG_ 689 AntiLockBrakingActive_ISig_5 100;
BA_ "GenSigCycleTimeActive" SG_ 689 AntiLockBrakingActive_ISig_5 100;
BA_ "GenSigStartValue" SG_ 689 AntiLockBrakingActive_ISig_5 3;
BA_ "GenSigMaxLatency" SG_ 689 AntiLockBrakingActive_ISig_5 100;
BA_ "GenSigCycleTime" SG_ 689 RearAxle1DiffLock_stat_ISig_5 100;
BA_ "GenSigCycleTimeActive" SG_ 689 RearAxle1DiffLock_stat_ISig_5 100;
BA_ "GenSigStartValue" SG_ 689 RearAxle1DiffLock_stat_ISig_5 3;
BA_ "GenSigMaxLatency" SG_ 689 RearAxle1DiffLock_stat_ISig_5 100;
BA_ "GenSigCycleTime" SG_ 689 Trail5TPMLostCom 100;
BA_ "GenSigCycleTimeActive" SG_ 689 Trail5TPMLostCom 100;
BA_ "GenSigStartValue" SG_ 689 Trail5TPMLostCom 3;
BA_ "GenSigMaxLatency" SG_ 689 Trail5TPMLostCom 100;
BA_ "GenSigCycleTime" SG_ 689 PS_PositionLight 100;
BA_ "GenSigCycleTimeActive" SG_ 689 PS_PositionLight 100;
BA_ "GenSigStartValue" SG_ 689 PS_PositionLight 3;
BA_ "GenSigMaxLatency" SG_ 689 PS_PositionLight 100;
BA_ "GenSigCycleTime" SG_ 689 BatteryCapacity_Ack_ISig_5 100;
BA_ "GenSigCycleTimeActive" SG_ 689 BatteryCapacity_Ack_ISig_5 100;
BA_ "GenSigStartValue" SG_ 689 BatteryCapacity_Ack_ISig_5 3;
BA_ "GenSigMaxLatency" SG_ 689 BatteryCapacity_Ack_ISig_5 100;
BA_ "GenSigCycleTime" SG_ 689 Trail3TPMLostCom 100;
BA_ "GenSigCycleTimeActive" SG_ 689 Trail3TPMLostCom 100;
BA_ "GenSigStartValue" SG_ 689 Trail3TPMLostCom 3;
BA_ "GenSigMaxLatency" SG_ 689 Trail3TPMLostCom 100;
BA_ "GenSigCycleTime" SG_ 689 ParkBrakeWorkshopMode_ISig_5 100;
BA_ "GenSigCycleTimeActive" SG_ 689 ParkBrakeWorkshopMode_ISig_5 100;
BA_ "GenSigStartValue" SG_ 689 ParkBrakeWorkshopMode_ISig_5 3;
BA_ "GenSigMaxLatency" SG_ 689 ParkBrakeWorkshopMode_ISig_5 100;
BA_ "GenSigCycleTime" SG_ 689 LowTempClutchInfo_ISig_5 100;
BA_ "GenSigCycleTimeActive" SG_ 689 LowTempClutchInfo_ISig_5 100;
BA_ "GenSigStartValue" SG_ 689 LowTempClutchInfo_ISig_5 3;
BA_ "GenSigMaxLatency" SG_ 689 LowTempClutchInfo_ISig_5 100;
BA_ "GenSigCycleTime" SG_ 688 APMSafetyWarning_CRC_ISig_5 100;
BA_ "GenSigCycleTimeActive" SG_ 688 APMSafetyWarning_CRC_ISig_5 100;
BA_ "GenSigStartValue" SG_ 688 APMSafetyWarning_CRC_ISig_5 255;
BA_ "GenSigMaxLatency" SG_ 688 APMSafetyWarning_CRC_ISig_5 100;
BA_ "E2EDataId" SG_ 688 APMSafetyWarning_CRC_ISig_5 181;
BA_ "E2EDataLength" SG_ 688 APMSafetyWarning_CRC_ISig_5 16;
BA_ "E2EProfile" SG_ 688 APMSafetyWarning_CRC_ISig_5 "P01";
BA_ "GenSigCycleTime" SG_ 688 PBStatus_CRC_ISig_5 100;
BA_ "GenSigCycleTimeActive" SG_ 688 PBStatus_CRC_ISig_5 100;
BA_ "GenSigStartValue" SG_ 688 PBStatus_CRC_ISig_5 255;
BA_ "GenSigMaxLatency" SG_ 688 PBStatus_CRC_ISig_5 100;
BA_ "E2EDataId" SG_ 688 PBStatus_CRC_ISig_5 107;
BA_ "E2EDataLength" SG_ 688 PBStatus_CRC_ISig_5 24;
BA_ "E2EProfile" SG_ 688 PBStatus_CRC_ISig_5 "P01";
BA_ "GenSigCycleTime" SG_ 688 TrailerWithoutABS_ISig_5 100;
BA_ "GenSigCycleTimeActive" SG_ 688 TrailerWithoutABS_ISig_5 100;
BA_ "GenSigStartValue" SG_ 688 TrailerWithoutABS_ISig_5 3;
BA_ "GenSigMaxLatency" SG_ 688 TrailerWithoutABS_ISig_5 100;
BA_ "GenSigCycleTime" SG_ 688 APMSafetyWarning_RedRqst_ISig_5 100;
BA_ "GenSigCycleTimeActive" SG_ 688 APMSafetyWarning_RedRqst_ISig_5 100;
BA_ "GenSigStartValue" SG_ 688 APMSafetyWarning_RedRqst_ISig_5 3;
BA_ "GenSigMaxLatency" SG_ 688 APMSafetyWarning_RedRqst_ISig_5 100;
BA_ "GenSigCycleTime" SG_ 688 EcoRollEnabledStatus_ISig_5 100;
BA_ "GenSigCycleTimeActive" SG_ 688 EcoRollEnabledStatus_ISig_5 100;
BA_ "GenSigStartValue" SG_ 688 EcoRollEnabledStatus_ISig_5 3;
BA_ "GenSigMaxLatency" SG_ 688 EcoRollEnabledStatus_ISig_5 100;
BA_ "GenSigCycleTime" SG_ 688 PBStatus_Actuation_ISig_5 100;
BA_ "GenSigCycleTimeActive" SG_ 688 PBStatus_Actuation_ISig_5 100;
BA_ "GenSigStartValue" SG_ 688 PBStatus_Actuation_ISig_5 7;
BA_ "GenSigMaxLatency" SG_ 688 PBStatus_Actuation_ISig_5 100;
BA_ "GenSigCycleTime" SG_ 688 GearShiftingRec_Steps_ISig_5 100;
BA_ "GenSigCycleTimeActive" SG_ 688 GearShiftingRec_Steps_ISig_5 100;
BA_ "GenSigStartValue" SG_ 688 GearShiftingRec_Steps_ISig_5 7;
BA_ "GenSigMaxLatency" SG_ 688 GearShiftingRec_Steps_ISig_5 100;
BA_ "GenSigCycleTime" SG_ 688 PBStatus_IntegrityLvl_ISig_5 100;
BA_ "GenSigCycleTimeActive" SG_ 688 PBStatus_IntegrityLvl_ISig_5 100;
BA_ "GenSigStartValue" SG_ 688 PBStatus_IntegrityLvl_ISig_5 3;
BA_ "GenSigMaxLatency" SG_ 688 PBStatus_IntegrityLvl_ISig_5 100;
BA_ "GenSigCycleTime" SG_ 688 GearShiftingRec_Direction_ISig_5 100;
BA_ "GenSigCycleTimeActive" SG_ 688 GearShiftingRec_Direction_ISig_5 100;
BA_ "GenSigStartValue" SG_ 688 GearShiftingRec_Direction_ISig_5 7;
BA_ "GenSigMaxLatency" SG_ 688 GearShiftingRec_Direction_ISig_5 100;
BA_ "GenSigCycleTime" SG_ 688 RearPropulsionStat_Rear2Axle_ISi 100;
BA_ "GenSigCycleTimeActive" SG_ 688 RearPropulsionStat_Rear2Axle_ISi 100;
BA_ "GenSigStartValue" SG_ 688 RearPropulsionStat_Rear2Axle_ISi 15;
BA_ "GenSigMaxLatency" SG_ 688 RearPropulsionStat_Rear2Axle_ISi 100;
BA_ "SystemSignalLongSymbol" SG_ 688 RearPropulsionStat_Rear2Axle_ISi "RearPropulsionStat_Rear2Axle_ISig_5";
BA_ "GenSigCycleTime" SG_ 688 RearPropulsionStat_Rear1Axle_ISi 100;
BA_ "GenSigCycleTimeActive" SG_ 688 RearPropulsionStat_Rear1Axle_ISi 100;
BA_ "GenSigStartValue" SG_ 688 RearPropulsionStat_Rear1Axle_ISi 15;
BA_ "GenSigMaxLatency" SG_ 688 RearPropulsionStat_Rear1Axle_ISi 100;
BA_ "SystemSignalLongSymbol" SG_ 688 RearPropulsionStat_Rear1Axle_ISi "RearPropulsionStat_Rear1Axle_ISig_5";
BA_ "GenSigCycleTime" SG_ 688 RearPropulsionStat_Rear3Axle_ISi 100;
BA_ "GenSigCycleTimeActive" SG_ 688 RearPropulsionStat_Rear3Axle_ISi 100;
BA_ "GenSigStartValue" SG_ 688 RearPropulsionStat_Rear3Axle_ISi 15;
BA_ "GenSigMaxLatency" SG_ 688 RearPropulsionStat_Rear3Axle_ISi 100;
BA_ "SystemSignalLongSymbol" SG_ 688 RearPropulsionStat_Rear3Axle_ISi "RearPropulsionStat_Rear3Axle_ISig_5";
BA_ "GenSigCycleTime" SG_ 688 PBStatus_SqC_ISig_5 100;
BA_ "GenSigCycleTimeActive" SG_ 688 PBStatus_SqC_ISig_5 100;
BA_ "GenSigStartValue" SG_ 688 PBStatus_SqC_ISig_5 14;
BA_ "GenSigMaxLatency" SG_ 688 PBStatus_SqC_ISig_5 100;
BA_ "GenSigCycleTime" SG_ 688 APMSafetyWarning_SqC_ISig_5 100;
BA_ "GenSigCycleTimeActive" SG_ 688 APMSafetyWarning_SqC_ISig_5 100;
BA_ "GenSigStartValue" SG_ 688 APMSafetyWarning_SqC_ISig_5 14;
BA_ "GenSigMaxLatency" SG_ 688 APMSafetyWarning_SqC_ISig_5 100;
BA_ "GenSigCycleTime" SG_ 688 APMSafetyWarning_YellowRqst_ISig 100;
BA_ "GenSigCycleTimeActive" SG_ 688 APMSafetyWarning_YellowRqst_ISig 100;
BA_ "GenSigStartValue" SG_ 688 APMSafetyWarning_YellowRqst_ISig 3;
BA_ "GenSigMaxLatency" SG_ 688 APMSafetyWarning_YellowRqst_ISig 100;
BA_ "SystemSignalLongSymbol" SG_ 688 APMSafetyWarning_YellowRqst_ISig "APMSafetyWarning_YellowRqst_ISig_5";
BA_ "GenSigCycleTime" SG_ 394 FPBRMMIStat_FPBRStatusInd_ISig_5 100;
BA_ "GenSigCycleTimeActive" SG_ 394 FPBRMMIStat_FPBRStatusInd_ISig_5 100;
BA_ "GenSigStartValue" SG_ 394 FPBRMMIStat_FPBRStatusInd_ISig_5 3;
BA_ "GenSigMaxLatency" SG_ 394 FPBRMMIStat_FPBRStatusInd_ISig_5 50;
BA_ "GenSigCycleTime" SG_ 394 LongitudinalAcceleration_ISig_5 100;
BA_ "GenSigCycleTimeActive" SG_ 394 LongitudinalAcceleration_ISig_5 100;
BA_ "GenSigStartValue" SG_ 394 LongitudinalAcceleration_ISig_5 65535;
BA_ "GenSigMaxLatency" SG_ 394 LongitudinalAcceleration_ISig_5 50;
BA_ "GenSigCycleTime" SG_ 394 FPBRMMIStat_FPBRChangeAck_ISig_5 100;
BA_ "GenSigCycleTimeActive" SG_ 394 FPBRMMIStat_FPBRChangeAck_ISig_5 100;
BA_ "GenSigStartValue" SG_ 394 FPBRMMIStat_FPBRChangeAck_ISig_5 3;
BA_ "GenSigMaxLatency" SG_ 394 FPBRMMIStat_FPBRChangeAck_ISig_5 50;
BA_ "GenSigCycleTime" SG_ 394 RssInhibStartEngine_rqst 100;
BA_ "GenSigCycleTimeActive" SG_ 394 RssInhibStartEngine_rqst 100;
BA_ "GenSigStartValue" SG_ 394 RssInhibStartEngine_rqst 3;
BA_ "GenSigMaxLatency" SG_ 394 RssInhibStartEngine_rqst 50;
BA_ "GenSigCycleTime" SG_ 394 MainBeam_rqst 100;
BA_ "GenSigCycleTimeActive" SG_ 394 MainBeam_rqst 100;
BA_ "GenSigStartValue" SG_ 394 MainBeam_rqst 7;
BA_ "GenSigMaxLatency" SG_ 394 MainBeam_rqst 50;
BA_ "GenSigCycleTime" SG_ 394 DumpSwitchChangeAck_ISig_5 100;
BA_ "GenSigCycleTimeActive" SG_ 394 DumpSwitchChangeAck_ISig_5 100;
BA_ "GenSigStartValue" SG_ 394 DumpSwitchChangeAck_ISig_5 3;
BA_ "GenSigMaxLatency" SG_ 394 DumpSwitchChangeAck_ISig_5 50;
BA_ "GenSigCycleTime" SG_ 394 CCSetSpeed_ISig_5 100;
BA_ "GenSigCycleTimeActive" SG_ 394 CCSetSpeed_ISig_5 100;
BA_ "GenSigStartValue" SG_ 394 CCSetSpeed_ISig_5 65535;
BA_ "GenSigMaxLatency" SG_ 394 CCSetSpeed_ISig_5 50;
BA_ "GenSigCycleTime" SG_ 393 EngineActiveStatus_ISig_5 100;
BA_ "GenSigCycleTimeActive" SG_ 393 EngineActiveStatus_ISig_5 100;
BA_ "GenSigStartValue" SG_ 393 EngineActiveStatus_ISig_5 15;
BA_ "GenSigMaxLatency" SG_ 393 EngineActiveStatus_ISig_5 50;
BA_ "GenSigCycleTime" SG_ 393 BackLightDimming_Status3 100;
BA_ "GenSigCycleTimeActive" SG_ 393 BackLightDimming_Status3 100;
BA_ "GenSigStartValue" SG_ 393 BackLightDimming_Status3 31;
BA_ "GenSigMaxLatency" SG_ 393 BackLightDimming_Status3 50;
BA_ "GenSigCycleTime" SG_ 393 FrontAxleSpeed_ISig_5 100;
BA_ "GenSigCycleTimeActive" SG_ 393 FrontAxleSpeed_ISig_5 100;
BA_ "GenSigStartValue" SG_ 393 FrontAxleSpeed_ISig_5 65535;
BA_ "GenSigMaxLatency" SG_ 393 FrontAxleSpeed_ISig_5 50;
BA_ "GenSigCycleTime" SG_ 393 BrakePedalTestState_ISig_5 100;
BA_ "GenSigCycleTimeActive" SG_ 393 BrakePedalTestState_ISig_5 100;
BA_ "GenSigStartValue" SG_ 393 BrakePedalTestState_ISig_5 15;
BA_ "GenSigMaxLatency" SG_ 393 BrakePedalTestState_ISig_5 50;
BA_ "GenSigCycleTime" SG_ 393 ParkBrakeApplicationMode2_ISig_5 100;
BA_ "GenSigCycleTimeActive" SG_ 393 ParkBrakeApplicationMode2_ISig_5 100;
BA_ "GenSigStartValue" SG_ 393 ParkBrakeApplicationMode2_ISig_5 15;
BA_ "GenSigMaxLatency" SG_ 393 ParkBrakeApplicationMode2_ISig_5 50;
BA_ "GenSigCycleTime" SG_ 393 RampLevelStatus_ISig_5 100;
BA_ "GenSigCycleTimeActive" SG_ 393 RampLevelStatus_ISig_5 100;
BA_ "GenSigStartValue" SG_ 393 RampLevelStatus_ISig_5 15;
BA_ "GenSigMaxLatency" SG_ 393 RampLevelStatus_ISig_5 50;
BA_ "GenSigCycleTime" SG_ 393 ParkBrakeReleaseMode2_ISig_5 100;
BA_ "GenSigCycleTimeActive" SG_ 393 ParkBrakeReleaseMode2_ISig_5 100;
BA_ "GenSigStartValue" SG_ 393 ParkBrakeReleaseMode2_ISig_5 15;
BA_ "GenSigMaxLatency" SG_ 393 ParkBrakeReleaseMode2_ISig_5 50;
BA_ "GenSigCycleTime" SG_ 393 BackLightDimming_Status 100;
BA_ "GenSigCycleTimeActive" SG_ 393 BackLightDimming_Status 100;
BA_ "GenSigStartValue" SG_ 393 BackLightDimming_Status 31;
BA_ "GenSigMaxLatency" SG_ 393 BackLightDimming_Status 50;
BA_ "GenSigCycleTime" SG_ 393 HeightControlMode_ISig_5 100;
BA_ "GenSigCycleTimeActive" SG_ 393 HeightControlMode_ISig_5 100;
BA_ "GenSigStartValue" SG_ 393 HeightControlMode_ISig_5 15;
BA_ "GenSigMaxLatency" SG_ 393 HeightControlMode_ISig_5 50;
BA_ "GenSigCycleTime" SG_ 393 FifthWheelLockingInformation_ISi 100;
BA_ "GenSigCycleTimeActive" SG_ 393 FifthWheelLockingInformation_ISi 100;
BA_ "GenSigStartValue" SG_ 393 FifthWheelLockingInformation_ISi 15;
BA_ "GenSigMaxLatency" SG_ 393 FifthWheelLockingInformation_ISi 50;
BA_ "SystemSignalLongSymbol" SG_ 393 FifthWheelLockingInformation_ISi "FifthWheelLockingInformation_ISig_5";
BA_ "GenSigCycleTime" SG_ 392 FirstAxleLowerPrioSelected_ISig_ 100;
BA_ "GenSigCycleTimeActive" SG_ 392 FirstAxleLowerPrioSelected_ISig_ 100;
BA_ "GenSigStartValue" SG_ 392 FirstAxleLowerPrioSelected_ISig_ 7;
BA_ "GenSigMaxLatency" SG_ 392 FirstAxleLowerPrioSelected_ISig_ 50;
BA_ "SystemSignalLongSymbol" SG_ 392 FirstAxleLowerPrioSelected_ISig_ "FirstAxleLowerPrioSelected_ISig_5";
BA_ "GenSigCycleTime" SG_ 392 ESCState_ISig_5 100;
BA_ "GenSigCycleTimeActive" SG_ 392 ESCState_ISig_5 100;
BA_ "GenSigStartValue" SG_ 392 ESCState_ISig_5 7;
BA_ "GenSigMaxLatency" SG_ 392 ESCState_ISig_5 50;
BA_ "GenSigCycleTime" SG_ 392 KneelingInformation_ISig_5 100;
BA_ "GenSigCycleTimeActive" SG_ 392 KneelingInformation_ISig_5 100;
BA_ "GenSigStartValue" SG_ 392 KneelingInformation_ISig_5 15;
BA_ "GenSigMaxLatency" SG_ 392 KneelingInformation_ISig_5 50;
BA_ "GenSigCycleTime" SG_ 392 TrailerTest_stat_ISig_5 100;
BA_ "GenSigCycleTimeActive" SG_ 392 TrailerTest_stat_ISig_5 100;
BA_ "GenSigStartValue" SG_ 392 TrailerTest_stat_ISig_5 7;
BA_ "GenSigMaxLatency" SG_ 392 TrailerTest_stat_ISig_5 50;
BA_ "GenSigCycleTime" SG_ 392 ThreePosDifflockSwitch_stat 100;
BA_ "GenSigCycleTimeActive" SG_ 392 ThreePosDifflockSwitch_stat 100;
BA_ "GenSigStartValue" SG_ 392 ThreePosDifflockSwitch_stat 7;
BA_ "GenSigMaxLatency" SG_ 392 ThreePosDifflockSwitch_stat 50;
BA_ "GenSigCycleTime" SG_ 392 HillHolderMode_ISig_5 100;
BA_ "GenSigCycleTimeActive" SG_ 392 HillHolderMode_ISig_5 100;
BA_ "GenSigStartValue" SG_ 392 HillHolderMode_ISig_5 7;
BA_ "GenSigMaxLatency" SG_ 392 HillHolderMode_ISig_5 50;
BA_ "GenSigCycleTime" SG_ 392 RampHeightOutsideTargetRange_ISi 100;
BA_ "GenSigCycleTimeActive" SG_ 392 RampHeightOutsideTargetRange_ISi 100;
BA_ "GenSigStartValue" SG_ 392 RampHeightOutsideTargetRange_ISi 7;
BA_ "GenSigMaxLatency" SG_ 392 RampHeightOutsideTargetRange_ISi 50;
BA_ "SystemSignalLongSymbol" SG_ 392 RampHeightOutsideTargetRange_ISi "RampHeightOutsideTargetRange_ISig_5";
BA_ "GenSigCycleTime" SG_ 392 ShortStopHeater_status_ISig_5 100;
BA_ "GenSigCycleTimeActive" SG_ 392 ShortStopHeater_status_ISig_5 100;
BA_ "GenSigStartValue" SG_ 392 ShortStopHeater_status_ISig_5 7;
BA_ "GenSigMaxLatency" SG_ 392 ShortStopHeater_status_ISig_5 50;
BA_ "GenSigCycleTime" SG_ 392 LuggageAjar_stat 100;
BA_ "GenSigCycleTimeActive" SG_ 392 LuggageAjar_stat 100;
BA_ "GenSigStartValue" SG_ 392 LuggageAjar_stat 7;
BA_ "GenSigMaxLatency" SG_ 392 LuggageAjar_stat 50;
BA_ "GenSigCycleTime" SG_ 392 LoadDistributionRequestedACK_ISi 100;
BA_ "GenSigCycleTimeActive" SG_ 392 LoadDistributionRequestedACK_ISi 100;
BA_ "GenSigStartValue" SG_ 392 LoadDistributionRequestedACK_ISi 7;
BA_ "GenSigMaxLatency" SG_ 392 LoadDistributionRequestedACK_ISi 50;
BA_ "SystemSignalLongSymbol" SG_ 392 LoadDistributionRequestedACK_ISi "LoadDistributionRequestedACK_ISig_5";
BA_ "GenSigCycleTime" SG_ 392 StretchBrake_Stat_ISig_5 100;
BA_ "GenSigCycleTimeActive" SG_ 392 StretchBrake_Stat_ISig_5 100;
BA_ "GenSigStartValue" SG_ 392 StretchBrake_Stat_ISig_5 7;
BA_ "GenSigMaxLatency" SG_ 392 StretchBrake_Stat_ISig_5 50;
BA_ "GenSigCycleTime" SG_ 392 MirrorHeatingMode 100;
BA_ "GenSigCycleTimeActive" SG_ 392 MirrorHeatingMode 100;
BA_ "GenSigStartValue" SG_ 392 MirrorHeatingMode 7;
BA_ "GenSigMaxLatency" SG_ 392 MirrorHeatingMode 50;
BA_ "GenSigCycleTime" SG_ 392 ESCStatus_ISig_5 100;
BA_ "GenSigCycleTimeActive" SG_ 392 ESCStatus_ISig_5 100;
BA_ "GenSigStartValue" SG_ 392 ESCStatus_ISig_5 7;
BA_ "GenSigMaxLatency" SG_ 392 ESCStatus_ISig_5 50;
BA_ "GenSigCycleTime" SG_ 392 DriverRetarderRequest_ISig_5 100;
BA_ "GenSigCycleTimeActive" SG_ 392 DriverRetarderRequest_ISig_5 100;
BA_ "GenSigStartValue" SG_ 392 DriverRetarderRequest_ISig_5 7;
BA_ "GenSigMaxLatency" SG_ 392 DriverRetarderRequest_ISig_5 50;
BA_ "GenSigCycleTime" SG_ 392 PBReleaseAcceptance_stat_ISig_5 100;
BA_ "GenSigCycleTimeActive" SG_ 392 PBReleaseAcceptance_stat_ISig_5 100;
BA_ "GenSigStartValue" SG_ 392 PBReleaseAcceptance_stat_ISig_5 7;
BA_ "GenSigMaxLatency" SG_ 392 PBReleaseAcceptance_stat_ISig_5 50;
BA_ "GenSigCycleTime" SG_ 392 PSWindowPosition 100;
BA_ "GenSigCycleTimeActive" SG_ 392 PSWindowPosition 100;
BA_ "GenSigStartValue" SG_ 392 PSWindowPosition 7;
BA_ "GenSigMaxLatency" SG_ 392 PSWindowPosition 50;
BA_ "GenSigCycleTime" SG_ 392 RideHeightOutsideTargetRange_ISi 100;
BA_ "GenSigCycleTimeActive" SG_ 392 RideHeightOutsideTargetRange_ISi 100;
BA_ "GenSigStartValue" SG_ 392 RideHeightOutsideTargetRange_ISi 7;
BA_ "GenSigMaxLatency" SG_ 392 RideHeightOutsideTargetRange_ISi 50;
BA_ "SystemSignalLongSymbol" SG_ 392 RideHeightOutsideTargetRange_ISi "RideHeightOutsideTargetRange_ISig_5";
BA_ "GenSigCycleTime" SG_ 392 DriveLevelPosUserInteraction_ISi 100;
BA_ "GenSigCycleTimeActive" SG_ 392 DriveLevelPosUserInteraction_ISi 100;
BA_ "GenSigStartValue" SG_ 392 DriveLevelPosUserInteraction_ISi 7;
BA_ "GenSigMaxLatency" SG_ 392 DriveLevelPosUserInteraction_ISi 50;
BA_ "SystemSignalLongSymbol" SG_ 392 DriveLevelPosUserInteraction_ISi "DriveLevelPosUserInteraction_ISig_5";
BA_ "GenSigCycleTime" SG_ 392 HillStartAidStatus_ISig_5 100;
BA_ "GenSigCycleTimeActive" SG_ 392 HillStartAidStatus_ISig_5 100;
BA_ "GenSigStartValue" SG_ 392 HillStartAidStatus_ISig_5 7;
BA_ "GenSigMaxLatency" SG_ 392 HillStartAidStatus_ISig_5 50;
BA_ "GenSigCycleTime" SG_ 391 AcceleratorPedalTestStatus 100;
BA_ "GenSigCycleTimeActive" SG_ 391 AcceleratorPedalTestStatus 100;
BA_ "GenSigStartValue" SG_ 391 AcceleratorPedalTestStatus 7;
BA_ "GenSigMaxLatency" SG_ 391 AcceleratorPedalTestStatus 50;
BA_ "GenSigCycleTime" SG_ 391 ESCDriverReq_ISig_5 100;
BA_ "GenSigCycleTimeActive" SG_ 391 ESCDriverReq_ISig_5 100;
BA_ "GenSigStartValue" SG_ 391 ESCDriverReq_ISig_5 7;
BA_ "GenSigMaxLatency" SG_ 391 ESCDriverReq_ISig_5 50;
BA_ "GenSigCycleTime" SG_ 391 UnevenLoadWarning_ISig_5 100;
BA_ "GenSigCycleTimeActive" SG_ 391 UnevenLoadWarning_ISig_5 100;
BA_ "GenSigStartValue" SG_ 391 UnevenLoadWarning_ISig_5 3;
BA_ "GenSigMaxLatency" SG_ 391 UnevenLoadWarning_ISig_5 50;
BA_ "GenSigCycleTime" SG_ 391 RrInterAxlDiffLockActvnFuncReq_I 100;
BA_ "GenSigCycleTimeActive" SG_ 391 RrInterAxlDiffLockActvnFuncReq_I 100;
BA_ "GenSigStartValue" SG_ 391 RrInterAxlDiffLockActvnFuncReq_I 3;
BA_ "GenSigMaxLatency" SG_ 391 RrInterAxlDiffLockActvnFuncReq_I 50;
BA_ "SystemSignalLongSymbol" SG_ 391 RrInterAxlDiffLockActvnFuncReq_I "RrInterAxlDiffLockActvnFuncReq_ISig_5";
BA_ "GenSigCycleTime" SG_ 391 DoorsAjar_stat_ISig_5 100;
BA_ "GenSigCycleTimeActive" SG_ 391 DoorsAjar_stat_ISig_5 100;
BA_ "GenSigStartValue" SG_ 391 DoorsAjar_stat_ISig_5 7;
BA_ "GenSigMaxLatency" SG_ 391 DoorsAjar_stat_ISig_5 50;
BA_ "GenSigCycleTime" SG_ 391 ABSManAutoInhibitionStat_ISig_5 100;
BA_ "GenSigCycleTimeActive" SG_ 391 ABSManAutoInhibitionStat_ISig_5 100;
BA_ "GenSigStartValue" SG_ 391 ABSManAutoInhibitionStat_ISig_5 7;
BA_ "GenSigMaxLatency" SG_ 391 ABSManAutoInhibitionStat_ISig_5 50;
BA_ "GenSigCycleTime" SG_ 391 RrInterAxlDiffLockActvnDrvrReq_I 100;
BA_ "GenSigCycleTimeActive" SG_ 391 RrInterAxlDiffLockActvnDrvrReq_I 100;
BA_ "GenSigStartValue" SG_ 391 RrInterAxlDiffLockActvnDrvrReq_I 3;
BA_ "GenSigMaxLatency" SG_ 391 RrInterAxlDiffLockActvnDrvrReq_I 50;
BA_ "SystemSignalLongSymbol" SG_ 391 RrInterAxlDiffLockActvnDrvrReq_I "RrInterAxlDiffLockActvnDrvrReq_ISig_5";
BA_ "GenSigCycleTime" SG_ 391 EngineOilTempHigh_ISig_5 100;
BA_ "GenSigCycleTimeActive" SG_ 391 EngineOilTempHigh_ISig_5 100;
BA_ "GenSigStartValue" SG_ 391 EngineOilTempHigh_ISig_5 7;
BA_ "GenSigMaxLatency" SG_ 391 EngineOilTempHigh_ISig_5 50;
BA_ "GenSigCycleTime" SG_ 391 StartupProhibitStatus_ISig_5 100;
BA_ "GenSigCycleTimeActive" SG_ 391 StartupProhibitStatus_ISig_5 100;
BA_ "GenSigStartValue" SG_ 391 StartupProhibitStatus_ISig_5 3;
BA_ "GenSigMaxLatency" SG_ 391 StartupProhibitStatus_ISig_5 50;
BA_ "GenSigCycleTime" SG_ 391 AuxBrakesDwngrdModeInd_rqst 100;
BA_ "GenSigCycleTimeActive" SG_ 391 AuxBrakesDwngrdModeInd_rqst 100;
BA_ "GenSigStartValue" SG_ 391 AuxBrakesDwngrdModeInd_rqst 7;
BA_ "GenSigMaxLatency" SG_ 391 AuxBrakesDwngrdModeInd_rqst 50;
BA_ "GenSigCycleTime" SG_ 391 ElectricalLoadReduction_rqst_ISi 100;
BA_ "GenSigCycleTimeActive" SG_ 391 ElectricalLoadReduction_rqst_ISi 100;
BA_ "GenSigStartValue" SG_ 391 ElectricalLoadReduction_rqst_ISi 7;
BA_ "GenSigMaxLatency" SG_ 391 ElectricalLoadReduction_rqst_ISi 50;
BA_ "SystemSignalLongSymbol" SG_ 391 ElectricalLoadReduction_rqst_ISi "ElectricalLoadReduction_rqst_ISig_5";
BA_ "GenSigCycleTime" SG_ 391 LoadDistributionChangeACK_ISig_5 100;
BA_ "GenSigCycleTimeActive" SG_ 391 LoadDistributionChangeACK_ISig_5 100;
BA_ "GenSigStartValue" SG_ 391 LoadDistributionChangeACK_ISig_5 7;
BA_ "GenSigMaxLatency" SG_ 391 LoadDistributionChangeACK_ISig_5 50;
BA_ "GenSigCycleTime" SG_ 391 FerryFunctionStatus_ISig_5 100;
BA_ "GenSigCycleTimeActive" SG_ 391 FerryFunctionStatus_ISig_5 100;
BA_ "GenSigStartValue" SG_ 391 FerryFunctionStatus_ISig_5 7;
BA_ "GenSigMaxLatency" SG_ 391 FerryFunctionStatus_ISig_5 50;
BA_ "GenSigCycleTime" SG_ 391 ClutchOverloadStatus_ISig_5 100;
BA_ "GenSigCycleTimeActive" SG_ 391 ClutchOverloadStatus_ISig_5 100;
BA_ "GenSigStartValue" SG_ 391 ClutchOverloadStatus_ISig_5 3;
BA_ "GenSigMaxLatency" SG_ 391 ClutchOverloadStatus_ISig_5 50;
BA_ "GenSigCycleTime" SG_ 391 RollerBenchModeStatus_ISig_5 100;
BA_ "GenSigCycleTimeActive" SG_ 391 RollerBenchModeStatus_ISig_5 100;
BA_ "GenSigStartValue" SG_ 391 RollerBenchModeStatus_ISig_5 3;
BA_ "GenSigMaxLatency" SG_ 391 RollerBenchModeStatus_ISig_5 50;
BA_ "GenSigCycleTime" SG_ 391 LoadDistributionALDChangeACK_ISi 100;
BA_ "GenSigCycleTimeActive" SG_ 391 LoadDistributionALDChangeACK_ISi 100;
BA_ "GenSigStartValue" SG_ 391 LoadDistributionALDChangeACK_ISi 7;
BA_ "GenSigMaxLatency" SG_ 391 LoadDistributionALDChangeACK_ISi 50;
BA_ "SystemSignalLongSymbol" SG_ 391 LoadDistributionALDChangeACK_ISi "LoadDistributionALDChangeACK_ISig_5";
BA_ "GenSigCycleTime" SG_ 391 EngineSpeedControlStatus 100;
BA_ "GenSigCycleTimeActive" SG_ 391 EngineSpeedControlStatus 100;
BA_ "GenSigStartValue" SG_ 391 EngineSpeedControlStatus 7;
BA_ "GenSigMaxLatency" SG_ 391 EngineSpeedControlStatus 50;
BA_ "GenSigCycleTime" SG_ 391 DTCActive_ISig_5 100;
BA_ "GenSigCycleTimeActive" SG_ 391 DTCActive_ISig_5 100;
BA_ "GenSigStartValue" SG_ 391 DTCActive_ISig_5 3;
BA_ "GenSigMaxLatency" SG_ 391 DTCActive_ISig_5 50;
BA_ "GenSigCycleTime" SG_ 390 PS_SevereEngAndBrkOverspdWarn_IS 100;
BA_ "GenSigCycleTimeActive" SG_ 390 PS_SevereEngAndBrkOverspdWarn_IS 100;
BA_ "GenSigStartValue" SG_ 390 PS_SevereEngAndBrkOverspdWarn_IS 3;
BA_ "GenSigMaxLatency" SG_ 390 PS_SevereEngAndBrkOverspdWarn_IS 50;
BA_ "SystemSignalLongSymbol" SG_ 390 PS_SevereEngAndBrkOverspdWarn_IS "PS_SevereEngAndBrkOverspdWarn_ISig_5";
BA_ "GenSigCycleTime" SG_ 390 RearFog_Indication 100;
BA_ "GenSigCycleTimeActive" SG_ 390 RearFog_Indication 100;
BA_ "GenSigStartValue" SG_ 390 RearFog_Indication 3;
BA_ "GenSigMaxLatency" SG_ 390 RearFog_Indication 50;
BA_ "GenSigCycleTime" SG_ 390 SasAdaptationInProgress_ISig_5 100;
BA_ "GenSigCycleTimeActive" SG_ 390 SasAdaptationInProgress_ISig_5 100;
BA_ "GenSigStartValue" SG_ 390 SasAdaptationInProgress_ISig_5 3;
BA_ "GenSigMaxLatency" SG_ 390 SasAdaptationInProgress_ISig_5 50;
BA_ "GenSigCycleTime" SG_ 390 SplitBoxDifflockActvnDrvrRqst_IS 100;
BA_ "GenSigCycleTimeActive" SG_ 390 SplitBoxDifflockActvnDrvrRqst_IS 100;
BA_ "GenSigStartValue" SG_ 390 SplitBoxDifflockActvnDrvrRqst_IS 3;
BA_ "GenSigMaxLatency" SG_ 390 SplitBoxDifflockActvnDrvrRqst_IS 50;
BA_ "SystemSignalLongSymbol" SG_ 390 SplitBoxDifflockActvnDrvrRqst_IS "SplitBoxDifflockActvnDrvrRqst_ISig_5";
BA_ "GenSigCycleTime" SG_ 390 EcoRollActiveStatus_ISig_5 100;
BA_ "GenSigCycleTimeActive" SG_ 390 EcoRollActiveStatus_ISig_5 100;
BA_ "GenSigStartValue" SG_ 390 EcoRollActiveStatus_ISig_5 3;
BA_ "GenSigMaxLatency" SG_ 390 EcoRollActiveStatus_ISig_5 50;
BA_ "GenSigCycleTime" SG_ 390 PloughLampModeStatus_ISig_5 100;
BA_ "GenSigCycleTimeActive" SG_ 390 PloughLampModeStatus_ISig_5 100;
BA_ "GenSigStartValue" SG_ 390 PloughLampModeStatus_ISig_5 3;
BA_ "GenSigMaxLatency" SG_ 390 PloughLampModeStatus_ISig_5 50;
BA_ "GenSigCycleTime" SG_ 390 RrRrItrWhlDiffLckActvnDrvrReq_IS 100;
BA_ "GenSigCycleTimeActive" SG_ 390 RrRrItrWhlDiffLckActvnDrvrReq_IS 100;
BA_ "GenSigStartValue" SG_ 390 RrRrItrWhlDiffLckActvnDrvrReq_IS 3;
BA_ "GenSigMaxLatency" SG_ 390 RrRrItrWhlDiffLckActvnDrvrReq_IS 50;
BA_ "SystemSignalLongSymbol" SG_ 390 RrRrItrWhlDiffLckActvnDrvrReq_IS "RrRrItrWhlDiffLckActvnDrvrReq_ISig_5";
BA_ "GenSigCycleTime" SG_ 390 DrvrRetarderBrakeProgram_rqst_IS 100;
BA_ "GenSigCycleTimeActive" SG_ 390 DrvrRetarderBrakeProgram_rqst_IS 100;
BA_ "GenSigStartValue" SG_ 390 DrvrRetarderBrakeProgram_rqst_IS 3;
BA_ "GenSigMaxLatency" SG_ 390 DrvrRetarderBrakeProgram_rqst_IS 50;
BA_ "SystemSignalLongSymbol" SG_ 390 DrvrRetarderBrakeProgram_rqst_IS "DrvrRetarderBrakeProgram_rqst_ISig_5";
BA_ "GenSigCycleTime" SG_ 390 PS_EngOverSpeedSevereWarning_ISi 100;
BA_ "GenSigCycleTimeActive" SG_ 390 PS_EngOverSpeedSevereWarning_ISi 100;
BA_ "GenSigStartValue" SG_ 390 PS_EngOverSpeedSevereWarning_ISi 3;
BA_ "GenSigMaxLatency" SG_ 390 PS_EngOverSpeedSevereWarning_ISi 50;
BA_ "SystemSignalLongSymbol" SG_ 390 PS_EngOverSpeedSevereWarning_ISi "PS_EngOverSpeedSevereWarning_ISig_5";
BA_ "GenSigCycleTime" SG_ 390 ParkBrakeReleasePossible_stat_IS 100;
BA_ "GenSigCycleTimeActive" SG_ 390 ParkBrakeReleasePossible_stat_IS 100;
BA_ "GenSigStartValue" SG_ 390 ParkBrakeReleasePossible_stat_IS 3;
BA_ "GenSigMaxLatency" SG_ 390 ParkBrakeReleasePossible_stat_IS 50;
BA_ "SystemSignalLongSymbol" SG_ 390 ParkBrakeReleasePossible_stat_IS "ParkBrakeReleasePossible_stat_ISig_5";
BA_ "GenSigCycleTime" SG_ 390 StoreIdleValue_ISig_5 100;
BA_ "GenSigCycleTimeActive" SG_ 390 StoreIdleValue_ISig_5 100;
BA_ "GenSigStartValue" SG_ 390 StoreIdleValue_ISig_5 3;
BA_ "GenSigMaxLatency" SG_ 390 StoreIdleValue_ISig_5 50;
BA_ "GenSigCycleTime" SG_ 390 AutRrAxleDiffLockActvnDrvrReq_IS 100;
BA_ "GenSigCycleTimeActive" SG_ 390 AutRrAxleDiffLockActvnDrvrReq_IS 100;
BA_ "GenSigStartValue" SG_ 390 AutRrAxleDiffLockActvnDrvrReq_IS 3;
BA_ "GenSigMaxLatency" SG_ 390 AutRrAxleDiffLockActvnDrvrReq_IS 50;
BA_ "SystemSignalLongSymbol" SG_ 390 AutRrAxleDiffLockActvnDrvrReq_IS "AutRrAxleDiffLockActvnDrvrReq_ISig_5";
BA_ "GenSigCycleTime" SG_ 390 TransmLowRangeSenseSwitch_ISig_5 100;
BA_ "GenSigCycleTimeActive" SG_ 390 TransmLowRangeSenseSwitch_ISig_5 100;
BA_ "GenSigStartValue" SG_ 390 TransmLowRangeSenseSwitch_ISig_5 3;
BA_ "GenSigMaxLatency" SG_ 390 TransmLowRangeSenseSwitch_ISig_5 50;
BA_ "GenSigCycleTime" SG_ 390 PBStatusDisplay_cmd_ISig_5 100;
BA_ "GenSigCycleTimeActive" SG_ 390 PBStatusDisplay_cmd_ISig_5 100;
BA_ "GenSigStartValue" SG_ 390 PBStatusDisplay_cmd_ISig_5 3;
BA_ "GenSigMaxLatency" SG_ 390 PBStatusDisplay_cmd_ISig_5 50;
BA_ "GenSigCycleTime" SG_ 390 AutoRearAxleDiffLockFnc_stat_ISi 100;
BA_ "GenSigCycleTimeActive" SG_ 390 AutoRearAxleDiffLockFnc_stat_ISi 100;
BA_ "GenSigStartValue" SG_ 390 AutoRearAxleDiffLockFnc_stat_ISi 3;
BA_ "GenSigMaxLatency" SG_ 390 AutoRearAxleDiffLockFnc_stat_ISi 50;
BA_ "SystemSignalLongSymbol" SG_ 390 AutoRearAxleDiffLockFnc_stat_ISi "AutoRearAxleDiffLockFnc_stat_ISig_5";
BA_ "GenSigCycleTime" SG_ 390 PoorBrakePerformanceWarning_ISig 100;
BA_ "GenSigCycleTimeActive" SG_ 390 PoorBrakePerformanceWarning_ISig 100;
BA_ "GenSigStartValue" SG_ 390 PoorBrakePerformanceWarning_ISig 3;
BA_ "GenSigMaxLatency" SG_ 390 PoorBrakePerformanceWarning_ISig 50;
BA_ "SystemSignalLongSymbol" SG_ 390 PoorBrakePerformanceWarning_ISig "PoorBrakePerformanceWarning_ISig_5";
BA_ "GenSigCycleTime" SG_ 390 FrontParkBrakeOverrideInd_ISig_5 100;
BA_ "GenSigCycleTimeActive" SG_ 390 FrontParkBrakeOverrideInd_ISig_5 100;
BA_ "GenSigStartValue" SG_ 390 FrontParkBrakeOverrideInd_ISig_5 3;
BA_ "GenSigMaxLatency" SG_ 390 FrontParkBrakeOverrideInd_ISig_5 50;
BA_ "GenSigCycleTime" SG_ 390 ProhibitControlStatus_ISig_5 100;
BA_ "GenSigCycleTimeActive" SG_ 390 ProhibitControlStatus_ISig_5 100;
BA_ "GenSigStartValue" SG_ 390 ProhibitControlStatus_ISig_5 3;
BA_ "GenSigMaxLatency" SG_ 390 ProhibitControlStatus_ISig_5 50;
BA_ "GenSigCycleTime" SG_ 390 PositionLightRequest_status 100;
BA_ "GenSigCycleTimeActive" SG_ 390 PositionLightRequest_status 100;
BA_ "GenSigStartValue" SG_ 390 PositionLightRequest_status 3;
BA_ "GenSigMaxLatency" SG_ 390 PositionLightRequest_status 50;
BA_ "GenSigCycleTime" SG_ 390 DoubleFrontAxleSteeringWarning_I 100;
BA_ "GenSigCycleTimeActive" SG_ 390 DoubleFrontAxleSteeringWarning_I 100;
BA_ "GenSigStartValue" SG_ 390 DoubleFrontAxleSteeringWarning_I 3;
BA_ "GenSigMaxLatency" SG_ 390 DoubleFrontAxleSteeringWarning_I 50;
BA_ "SystemSignalLongSymbol" SG_ 390 DoubleFrontAxleSteeringWarning_I "DoubleFrontAxleSteeringWarning_ISig_5";
BA_ "GenSigCycleTime" SG_ 390 TrailerABSStatus_ISig_5 100;
BA_ "GenSigCycleTimeActive" SG_ 390 TrailerABSStatus_ISig_5 100;
BA_ "GenSigStartValue" SG_ 390 TrailerABSStatus_ISig_5 3;
BA_ "GenSigMaxLatency" SG_ 390 TrailerABSStatus_ISig_5 50;
BA_ "GenSigCycleTime" SG_ 390 LoadCutOffIndication_cmd_ISig_5 100;
BA_ "GenSigCycleTimeActive" SG_ 390 LoadCutOffIndication_cmd_ISig_5 100;
BA_ "GenSigStartValue" SG_ 390 LoadCutOffIndication_cmd_ISig_5 3;
BA_ "GenSigMaxLatency" SG_ 390 LoadCutOffIndication_cmd_ISig_5 50;
BA_ "GenSigCycleTime" SG_ 390 PtosStatus_ISig_5 100;
BA_ "GenSigCycleTimeActive" SG_ 390 PtosStatus_ISig_5 100;
BA_ "GenSigStartValue" SG_ 390 PtosStatus_ISig_5 3;
BA_ "GenSigMaxLatency" SG_ 390 PtosStatus_ISig_5 50;
BA_ "GenSigCycleTime" SG_ 390 REM_PhoneButtonInd_cmd 100;
BA_ "GenSigCycleTimeActive" SG_ 390 REM_PhoneButtonInd_cmd 100;
BA_ "GenSigStartValue" SG_ 390 REM_PhoneButtonInd_cmd 3;
BA_ "GenSigMaxLatency" SG_ 390 REM_PhoneButtonInd_cmd 50;
BA_ "GenSigCycleTime" SG_ 390 TrailerBrake_Stat_ISig_5 100;
BA_ "GenSigCycleTimeActive" SG_ 390 TrailerBrake_Stat_ISig_5 100;
BA_ "GenSigStartValue" SG_ 390 TrailerBrake_Stat_ISig_5 3;
BA_ "GenSigMaxLatency" SG_ 390 TrailerBrake_Stat_ISig_5 50;
BA_ "GenSigCycleTime" SG_ 390 SEM2_PhoneButtonInd_cmd 100;
BA_ "GenSigCycleTimeActive" SG_ 390 SEM2_PhoneButtonInd_cmd 100;
BA_ "GenSigStartValue" SG_ 390 SEM2_PhoneButtonInd_cmd 3;
BA_ "GenSigMaxLatency" SG_ 390 SEM2_PhoneButtonInd_cmd 50;
BA_ "GenSigCycleTime" SG_ 390 GearRangeUnengaged_ISig_5 100;
BA_ "GenSigCycleTimeActive" SG_ 390 GearRangeUnengaged_ISig_5 100;
BA_ "GenSigStartValue" SG_ 390 GearRangeUnengaged_ISig_5 3;
BA_ "GenSigMaxLatency" SG_ 390 GearRangeUnengaged_ISig_5 50;
BA_ "GenSigCycleTime" SG_ 390 ABSOffRoadStatus_ISig_5 100;
BA_ "GenSigCycleTimeActive" SG_ 390 ABSOffRoadStatus_ISig_5 100;
BA_ "GenSigStartValue" SG_ 390 ABSOffRoadStatus_ISig_5 3;
BA_ "GenSigMaxLatency" SG_ 390 ABSOffRoadStatus_ISig_5 50;
BA_ "GenSigCycleTime" SG_ 390 DrvrRetarderBrakeBlending_rqst_I 100;
BA_ "GenSigCycleTimeActive" SG_ 390 DrvrRetarderBrakeBlending_rqst_I 100;
BA_ "GenSigStartValue" SG_ 390 DrvrRetarderBrakeBlending_rqst_I 3;
BA_ "GenSigMaxLatency" SG_ 390 DrvrRetarderBrakeBlending_rqst_I 50;
BA_ "SystemSignalLongSymbol" SG_ 390 DrvrRetarderBrakeBlending_rqst_I "DrvrRetarderBrakeBlending_rqst_ISig_5";
BA_ "GenSigCycleTime" SG_ 389 PHTimerRqstAck_Minutes 100;
BA_ "GenSigCycleTimeActive" SG_ 389 PHTimerRqstAck_Minutes 100;
BA_ "GenSigStartValue" SG_ 389 PHTimerRqstAck_Minutes 255;
BA_ "GenSigMaxLatency" SG_ 389 PHTimerRqstAck_Minutes 50;
BA_ "GenSigCycleTime" SG_ 389 RearAxleDiffLockActvnDrvrReq_ISi 100;
BA_ "GenSigCycleTimeActive" SG_ 389 RearAxleDiffLockActvnDrvrReq_ISi 100;
BA_ "GenSigStartValue" SG_ 389 RearAxleDiffLockActvnDrvrReq_ISi 3;
BA_ "GenSigMaxLatency" SG_ 389 RearAxleDiffLockActvnDrvrReq_ISi 50;
BA_ "SystemSignalLongSymbol" SG_ 389 RearAxleDiffLockActvnDrvrReq_ISi "RearAxleDiffLockActvnDrvrReq_ISig_5";
BA_ "GenSigCycleTime" SG_ 389 FrRrItrWhlDiffLckActvnDrvrReq_IS 100;
BA_ "GenSigCycleTimeActive" SG_ 389 FrRrItrWhlDiffLckActvnDrvrReq_IS 100;
BA_ "GenSigStartValue" SG_ 389 FrRrItrWhlDiffLckActvnDrvrReq_IS 3;
BA_ "GenSigMaxLatency" SG_ 389 FrRrItrWhlDiffLckActvnDrvrReq_IS 50;
BA_ "SystemSignalLongSymbol" SG_ 389 FrRrItrWhlDiffLckActvnDrvrReq_IS "FrRrItrWhlDiffLckActvnDrvrReq_ISig_5";
BA_ "GenSigCycleTime" SG_ 389 DriverLocation_CRC_ISig_5 100;
BA_ "GenSigCycleTimeActive" SG_ 389 DriverLocation_CRC_ISig_5 100;
BA_ "E2EDataId" SG_ 389 DriverLocation_CRC_ISig_5 243;
BA_ "E2EDataLength" SG_ 389 DriverLocation_CRC_ISig_5 24;
BA_ "E2EProfile" SG_ 389 DriverLocation_CRC_ISig_5 "P01";
BA_ "GenSigCycleTime" SG_ 389 RegenInhibDueHeight_ISig_5 100;
BA_ "GenSigCycleTimeActive" SG_ 389 RegenInhibDueHeight_ISig_5 100;
BA_ "GenSigStartValue" SG_ 389 RegenInhibDueHeight_ISig_5 3;
BA_ "GenSigMaxLatency" SG_ 389 RegenInhibDueHeight_ISig_5 50;
BA_ "GenSigCycleTime" SG_ 389 DriverLocation_Status_ISig_5 100;
BA_ "GenSigCycleTimeActive" SG_ 389 DriverLocation_Status_ISig_5 100;
BA_ "GenSigStartValue" SG_ 389 DriverLocation_Status_ISig_5 15;
BA_ "GenSigCycleTime" SG_ 389 PHTimerRqstAck_Hours 100;
BA_ "GenSigCycleTimeActive" SG_ 389 PHTimerRqstAck_Hours 100;
BA_ "GenSigStartValue" SG_ 389 PHTimerRqstAck_Hours 255;
BA_ "GenSigMaxLatency" SG_ 389 PHTimerRqstAck_Hours 50;
BA_ "GenSigCycleTime" SG_ 389 PoorAirPressureInfo_ISig_5 100;
BA_ "GenSigCycleTimeActive" SG_ 389 PoorAirPressureInfo_ISig_5 100;
BA_ "GenSigStartValue" SG_ 389 PoorAirPressureInfo_ISig_5 3;
BA_ "GenSigMaxLatency" SG_ 389 PoorAirPressureInfo_ISig_5 50;
BA_ "GenSigCycleTime" SG_ 389 DriverLocation_SqC_ISig_5 100;
BA_ "GenSigCycleTimeActive" SG_ 389 DriverLocation_SqC_ISig_5 100;
BA_ "GenSigCycleTime" SG_ 389 XRSLControllerMode_ISig_5 100;
BA_ "GenSigCycleTimeActive" SG_ 389 XRSLControllerMode_ISig_5 100;
BA_ "GenSigStartValue" SG_ 389 XRSLControllerMode_ISig_5 3;
BA_ "GenSigMaxLatency" SG_ 389 XRSLControllerMode_ISig_5 50;
BA_ "GenSigCycleTime" SG_ 389 PHTimerRqstAck_DayOfWeekRq 100;
BA_ "GenSigCycleTimeActive" SG_ 389 PHTimerRqstAck_DayOfWeekRq 100;
BA_ "GenSigStartValue" SG_ 389 PHTimerRqstAck_DayOfWeekRq 15;
BA_ "GenSigMaxLatency" SG_ 389 PHTimerRqstAck_DayOfWeekRq 50;
BA_ "GenSigCycleTime" SG_ 389 VIN_rqst_ISig_5 100;
BA_ "GenSigCycleTimeActive" SG_ 389 VIN_rqst_ISig_5 100;
BA_ "GenSigMaxLatency" SG_ 389 VIN_rqst_ISig_5 50;
BA_ "GenSigCycleTime" SG_ 389 PHTimerRqstAck_CurrentOp 100;
BA_ "GenSigCycleTimeActive" SG_ 389 PHTimerRqstAck_CurrentOp 100;
BA_ "GenSigStartValue" SG_ 389 PHTimerRqstAck_CurrentOp 3;
BA_ "GenSigMaxLatency" SG_ 389 PHTimerRqstAck_CurrentOp 50;
BA_ "GenSigCycleTime" SG_ 389 DriverLocation_ConfidenceLvl_ISi 100;
BA_ "GenSigCycleTimeActive" SG_ 389 DriverLocation_ConfidenceLvl_ISi 100;
BA_ "GenSigStartValue" SG_ 389 DriverLocation_ConfidenceLvl_ISi 3;
BA_ "SystemSignalLongSymbol" SG_ 389 DriverLocation_ConfidenceLvl_ISi "DriverLocation_ConfidenceLvl_ISig_5";
BA_ "GenSigCycleTime" SG_ 389 PS_EngineBrakeOverSpeedWarning_I 100;
BA_ "GenSigCycleTimeActive" SG_ 389 PS_EngineBrakeOverSpeedWarning_I 100;
BA_ "GenSigStartValue" SG_ 389 PS_EngineBrakeOverSpeedWarning_I 3;
BA_ "GenSigMaxLatency" SG_ 389 PS_EngineBrakeOverSpeedWarning_I 50;
BA_ "SystemSignalLongSymbol" SG_ 389 PS_EngineBrakeOverSpeedWarning_I "PS_EngineBrakeOverSpeedWarning_ISig_5";
BA_ "GenSigCycleTime" SG_ 389 TrcnCtrlSlipperyRoadWarning_ISig 100;
BA_ "GenSigCycleTimeActive" SG_ 389 TrcnCtrlSlipperyRoadWarning_ISig 100;
BA_ "GenSigStartValue" SG_ 389 TrcnCtrlSlipperyRoadWarning_ISig 3;
BA_ "GenSigMaxLatency" SG_ 389 TrcnCtrlSlipperyRoadWarning_ISig 50;
BA_ "SystemSignalLongSymbol" SG_ 389 TrcnCtrlSlipperyRoadWarning_ISig "TrcnCtrlSlipperyRoadWarning_ISig_5";
BA_ "GenSigCycleTime" SG_ 389 TransmissionAirPressureLow_ISig_ 100;
BA_ "GenSigCycleTimeActive" SG_ 389 TransmissionAirPressureLow_ISig_ 100;
BA_ "GenSigStartValue" SG_ 389 TransmissionAirPressureLow_ISig_ 3;
BA_ "GenSigMaxLatency" SG_ 389 TransmissionAirPressureLow_ISig_ 50;
BA_ "SystemSignalLongSymbol" SG_ 389 TransmissionAirPressureLow_ISig_ "TransmissionAirPressureLow_ISig_5";
BA_ "GenSigCycleTime" SG_ 158 SecuredNeutralPosition_ISig_5 100;
BA_ "GenSigCycleTimeActive" SG_ 158 SecuredNeutralPosition_ISig_5 100;
BA_ "GenSigStartValue" SG_ 158 SecuredNeutralPosition_ISig_5 3;
BA_ "GenSigMaxLatency" SG_ 158 SecuredNeutralPosition_ISig_5 20;
BA_ "GenSigCycleTime" SG_ 158 MirrorSelectLeftWideBtn_stat 100;
BA_ "GenSigCycleTimeActive" SG_ 158 MirrorSelectLeftWideBtn_stat 100;
BA_ "GenSigStartValue" SG_ 158 MirrorSelectLeftWideBtn_stat 3;
BA_ "GenSigMaxLatency" SG_ 158 MirrorSelectLeftWideBtn_stat 20;
BA_ "GenSigCycleTime" SG_ 158 BunkH1AudioOnOff_ButtonStatus 100;
BA_ "GenSigCycleTimeActive" SG_ 158 BunkH1AudioOnOff_ButtonStatus 100;
BA_ "GenSigStartValue" SG_ 158 BunkH1AudioOnOff_ButtonStatus 3;
BA_ "GenSigMaxLatency" SG_ 158 BunkH1AudioOnOff_ButtonStatus 20;
BA_ "GenSigCycleTime" SG_ 158 OverSteerGuidanceStatus_ISig_5 100;
BA_ "GenSigCycleTimeActive" SG_ 158 OverSteerGuidanceStatus_ISig_5 100;
BA_ "GenSigStartValue" SG_ 158 OverSteerGuidanceStatus_ISig_5 3;
BA_ "GenSigMaxLatency" SG_ 158 OverSteerGuidanceStatus_ISig_5 20;
BA_ "GenSigCycleTime" SG_ 158 MirrorSelectLeftMainBtn_stat 100;
BA_ "GenSigCycleTimeActive" SG_ 158 MirrorSelectLeftMainBtn_stat 100;
BA_ "GenSigStartValue" SG_ 158 MirrorSelectLeftMainBtn_stat 3;
BA_ "GenSigMaxLatency" SG_ 158 MirrorSelectLeftMainBtn_stat 20;
BA_ "GenSigCycleTime" SG_ 158 LECM_CabClim_Auto_BtnStat 100;
BA_ "GenSigCycleTimeActive" SG_ 158 LECM_CabClim_Auto_BtnStat 100;
BA_ "GenSigStartValue" SG_ 158 LECM_CabClim_Auto_BtnStat 3;
BA_ "GenSigMaxLatency" SG_ 158 LECM_CabClim_Auto_BtnStat 20;
BA_ "GenSigCycleTime" SG_ 158 LECM_Display_Navi_OK_BtnStat 100;
BA_ "GenSigCycleTimeActive" SG_ 158 LECM_Display_Navi_OK_BtnStat 100;
BA_ "GenSigStartValue" SG_ 158 LECM_Display_Navi_OK_BtnStat 3;
BA_ "GenSigMaxLatency" SG_ 158 LECM_Display_Navi_OK_BtnStat 20;
BA_ "GenSigCycleTime" SG_ 158 LECM_CabClim_AC_BtnStat 100;
BA_ "GenSigCycleTimeActive" SG_ 158 LECM_CabClim_AC_BtnStat 100;
BA_ "GenSigStartValue" SG_ 158 LECM_CabClim_AC_BtnStat 3;
BA_ "GenSigMaxLatency" SG_ 158 LECM_CabClim_AC_BtnStat 20;
BA_ "GenSigCycleTime" SG_ 158 LECMCabClimSetTempSelectGuiReq 100;
BA_ "GenSigCycleTimeActive" SG_ 158 LECMCabClimSetTempSelectGuiReq 100;
BA_ "GenSigStartValue" SG_ 158 LECMCabClimSetTempSelectGuiReq 3;
BA_ "GenSigMaxLatency" SG_ 158 LECMCabClimSetTempSelectGuiReq 20;
BA_ "GenSigCycleTime" SG_ 158 MirrorSelectRightMainBtn_stat 100;
BA_ "GenSigCycleTimeActive" SG_ 158 MirrorSelectRightMainBtn_stat 100;
BA_ "GenSigStartValue" SG_ 158 MirrorSelectRightMainBtn_stat 3;
BA_ "GenSigMaxLatency" SG_ 158 MirrorSelectRightMainBtn_stat 20;
BA_ "GenSigCycleTime" SG_ 158 DaytimeRunningLight_Indication 100;
BA_ "GenSigCycleTimeActive" SG_ 158 DaytimeRunningLight_Indication 100;
BA_ "GenSigStartValue" SG_ 158 DaytimeRunningLight_Indication 3;
BA_ "GenSigMaxLatency" SG_ 158 DaytimeRunningLight_Indication 20;
BA_ "GenSigCycleTime" SG_ 158 DrivingLight_Indication 100;
BA_ "GenSigCycleTimeActive" SG_ 158 DrivingLight_Indication 100;
BA_ "GenSigStartValue" SG_ 158 DrivingLight_Indication 3;
BA_ "GenSigMaxLatency" SG_ 158 DrivingLight_Indication 20;
BA_ "GenSigCycleTime" SG_ 158 FrontFog_Indication 100;
BA_ "GenSigCycleTimeActive" SG_ 158 FrontFog_Indication 100;
BA_ "GenSigStartValue" SG_ 158 FrontFog_Indication 3;
BA_ "GenSigMaxLatency" SG_ 158 FrontFog_Indication 20;
BA_ "GenSigCycleTime" SG_ 158 KeyfobPreTripButtonStatus 100;
BA_ "GenSigCycleTimeActive" SG_ 158 KeyfobPreTripButtonStatus 100;
BA_ "GenSigStartValue" SG_ 158 KeyfobPreTripButtonStatus 3;
BA_ "GenSigMaxLatency" SG_ 158 KeyfobPreTripButtonStatus 20;
BA_ "GenSigCycleTime" SG_ 158 MirrorSelectRightWideBtn_stat 100;
BA_ "GenSigCycleTimeActive" SG_ 158 MirrorSelectRightWideBtn_stat 100;
BA_ "GenSigStartValue" SG_ 158 MirrorSelectRightWideBtn_stat 3;
BA_ "GenSigMaxLatency" SG_ 158 MirrorSelectRightWideBtn_stat 20;
BA_ "GenSigCycleTime" SG_ 158 ParkingLight_Indication 100;
BA_ "GenSigCycleTimeActive" SG_ 158 ParkingLight_Indication 100;
BA_ "GenSigStartValue" SG_ 158 ParkingLight_Indication 3;
BA_ "GenSigMaxLatency" SG_ 158 ParkingLight_Indication 20;
BA_ "GenSigCycleTime" SG_ 158 DrivingLightPlus_Indication 100;
BA_ "GenSigCycleTimeActive" SG_ 158 DrivingLightPlus_Indication 100;
BA_ "GenSigStartValue" SG_ 158 DrivingLightPlus_Indication 3;
BA_ "GenSigMaxLatency" SG_ 158 DrivingLightPlus_Indication 20;
BA_ "GenSigCycleTime" SG_ 158 BlackPanelMode_ButtonStatus 100;
BA_ "GenSigCycleTimeActive" SG_ 158 BlackPanelMode_ButtonStatus 100;
BA_ "GenSigStartValue" SG_ 158 BlackPanelMode_ButtonStatus 3;
BA_ "GenSigMaxLatency" SG_ 158 BlackPanelMode_ButtonStatus 20;
BA_ "GenSigCycleTime" SG_ 158 ParkBrakeActuationStatus_ISig_5 100;
BA_ "GenSigCycleTimeActive" SG_ 158 ParkBrakeActuationStatus_ISig_5 100;
BA_ "GenSigStartValue" SG_ 158 ParkBrakeActuationStatus_ISig_5 7;
BA_ "GenSigMaxLatency" SG_ 158 ParkBrakeActuationStatus_ISig_5 20;
BA_ "GenSigCycleTime" SG_ 158 LECM_CabClim_FrPwr_BtnStat 100;
BA_ "GenSigCycleTimeActive" SG_ 158 LECM_CabClim_FrPwr_BtnStat 100;
BA_ "GenSigStartValue" SG_ 158 LECM_CabClim_FrPwr_BtnStat 3;
BA_ "GenSigMaxLatency" SG_ 158 LECM_CabClim_FrPwr_BtnStat 20;
BA_ "GenSigCycleTime" SG_ 158 LECM_CabClim_Pwr_BtnStat 100;
BA_ "GenSigCycleTimeActive" SG_ 158 LECM_CabClim_Pwr_BtnStat 100;
BA_ "GenSigStartValue" SG_ 158 LECM_CabClim_Pwr_BtnStat 3;
BA_ "GenSigMaxLatency" SG_ 158 LECM_CabClim_Pwr_BtnStat 20;
BA_ "GenSigCycleTime" SG_ 158 BlackPanelMode_ButtonStatus3 100;
BA_ "GenSigCycleTimeActive" SG_ 158 BlackPanelMode_ButtonStatus3 100;
BA_ "GenSigStartValue" SG_ 158 BlackPanelMode_ButtonStatus3 3;
BA_ "GenSigMaxLatency" SG_ 158 BlackPanelMode_ButtonStatus3 20;
BA_ "GenSigCycleTime" SG_ 158 LECM_CabClim_Sync_GuiReq 100;
BA_ "GenSigCycleTimeActive" SG_ 158 LECM_CabClim_Sync_GuiReq 100;
BA_ "GenSigStartValue" SG_ 158 LECM_CabClim_Sync_GuiReq 3;
BA_ "GenSigMaxLatency" SG_ 158 LECM_CabClim_Sync_GuiReq 20;
BA_ "GenSigCycleTime" SG_ 158 LiftAxle1AutoLiftSelected_ISig_5 100;
BA_ "GenSigCycleTimeActive" SG_ 158 LiftAxle1AutoLiftSelected_ISig_5 100;
BA_ "GenSigStartValue" SG_ 158 LiftAxle1AutoLiftSelected_ISig_5 3;
BA_ "GenSigMaxLatency" SG_ 158 LiftAxle1AutoLiftSelected_ISig_5 20;
BA_ "GenSigCycleTime" SG_ 158 LECM_Ent_OnOff_BtnStat 100;
BA_ "GenSigCycleTimeActive" SG_ 158 LECM_Ent_OnOff_BtnStat 100;
BA_ "GenSigStartValue" SG_ 158 LECM_Ent_OnOff_BtnStat 3;
BA_ "GenSigMaxLatency" SG_ 158 LECM_Ent_OnOff_BtnStat 20;
BA_ "GenSigCycleTime" SG_ 156 LiftAxle2LowerACK_ISig_5 100;
BA_ "GenSigCycleTimeActive" SG_ 156 LiftAxle2LowerACK_ISig_5 100;
BA_ "GenSigStartValue" SG_ 156 LiftAxle2LowerACK_ISig_5 7;
BA_ "GenSigMaxLatency" SG_ 156 LiftAxle2LowerACK_ISig_5 20;
BA_ "GenSigCycleTime" SG_ 156 LiftAxle2PositionStatus_ISig_5 100;
BA_ "GenSigCycleTimeActive" SG_ 156 LiftAxle2PositionStatus_ISig_5 100;
BA_ "GenSigStartValue" SG_ 156 LiftAxle2PositionStatus_ISig_5 7;
BA_ "GenSigMaxLatency" SG_ 156 LiftAxle2PositionStatus_ISig_5 20;
BA_ "GenSigCycleTime" SG_ 156 LiftAxle2LiftFuncSelected_ISig_5 100;
BA_ "GenSigCycleTimeActive" SG_ 156 LiftAxle2LiftFuncSelected_ISig_5 100;
BA_ "GenSigStartValue" SG_ 156 LiftAxle2LiftFuncSelected_ISig_5 7;
BA_ "GenSigMaxLatency" SG_ 156 LiftAxle2LiftFuncSelected_ISig_5 20;
BA_ "GenSigCycleTime" SG_ 156 PassengerDoorAjar_stat 100;
BA_ "GenSigCycleTimeActive" SG_ 156 PassengerDoorAjar_stat 100;
BA_ "GenSigStartValue" SG_ 156 PassengerDoorAjar_stat 7;
BA_ "GenSigMaxLatency" SG_ 156 PassengerDoorAjar_stat 20;
BA_ "GenSigCycleTime" SG_ 156 LevelControlInformation_ISig_5 100;
BA_ "GenSigCycleTimeActive" SG_ 156 LevelControlInformation_ISig_5 100;
BA_ "GenSigStartValue" SG_ 156 LevelControlInformation_ISig_5 15;
BA_ "GenSigMaxLatency" SG_ 156 LevelControlInformation_ISig_5 20;
BA_ "GenSigCycleTime" SG_ 156 LiftAxle1LowerACK_ISig_5 100;
BA_ "GenSigCycleTimeActive" SG_ 156 LiftAxle1LowerACK_ISig_5 100;
BA_ "GenSigStartValue" SG_ 156 LiftAxle1LowerACK_ISig_5 7;
BA_ "GenSigMaxLatency" SG_ 156 LiftAxle1LowerACK_ISig_5 20;
BA_ "GenSigCycleTime" SG_ 156 WiperModeStatus_ISig_5 100;
BA_ "GenSigCycleTimeActive" SG_ 156 WiperModeStatus_ISig_5 100;
BA_ "GenSigStartValue" SG_ 156 WiperModeStatus_ISig_5 7;
BA_ "GenSigMaxLatency" SG_ 156 WiperModeStatus_ISig_5 20;
BA_ "GenSigCycleTime" SG_ 156 Washing_HMI_rqst 100;
BA_ "GenSigCycleTimeActive" SG_ 156 Washing_HMI_rqst 100;
BA_ "GenSigStartValue" SG_ 156 Washing_HMI_rqst 3;
BA_ "GenSigMaxLatency" SG_ 156 Washing_HMI_rqst 20;
BA_ "GenSigCycleTime" SG_ 156 LiftAxle2AutoLiftSelected_ISig_5 100;
BA_ "GenSigCycleTimeActive" SG_ 156 LiftAxle2AutoLiftSelected_ISig_5 100;
BA_ "GenSigStartValue" SG_ 156 LiftAxle2AutoLiftSelected_ISig_5 3;
BA_ "GenSigMaxLatency" SG_ 156 LiftAxle2AutoLiftSelected_ISig_5 20;
BA_ "GenSigCycleTime" SG_ 156 ReverseGearEngaged_ISig_5 100;
BA_ "GenSigCycleTimeActive" SG_ 156 ReverseGearEngaged_ISig_5 100;
BA_ "GenSigStartValue" SG_ 156 ReverseGearEngaged_ISig_5 3;
BA_ "GenSigMaxLatency" SG_ 156 ReverseGearEngaged_ISig_5 20;
BA_ "GenSigCycleTime" SG_ 156 LiftAxle1PositionStatus_ISig_5 100;
BA_ "GenSigCycleTimeActive" SG_ 156 LiftAxle1PositionStatus_ISig_5 100;
BA_ "GenSigStartValue" SG_ 156 LiftAxle1PositionStatus_ISig_5 7;
BA_ "GenSigMaxLatency" SG_ 156 LiftAxle1PositionStatus_ISig_5 20;
BA_ "GenSigCycleTime" SG_ 156 ACC_Status_ISig_5 100;
BA_ "GenSigCycleTimeActive" SG_ 156 ACC_Status_ISig_5 100;
BA_ "GenSigStartValue" SG_ 156 ACC_Status_ISig_5 7;
BA_ "GenSigMaxLatency" SG_ 156 ACC_Status_ISig_5 20;
BA_ "GenSigCycleTime" SG_ 156 LECM_CabClim_MaxDef_GuiReq 100;
BA_ "GenSigCycleTimeActive" SG_ 156 LECM_CabClim_MaxDef_GuiReq 100;
BA_ "GenSigStartValue" SG_ 156 LECM_CabClim_MaxDef_GuiReq 3;
BA_ "GenSigMaxLatency" SG_ 156 LECM_CabClim_MaxDef_GuiReq 20;
BA_ "GenSigCycleTime" SG_ 156 RegenerationSwitchStatus 100;
BA_ "GenSigCycleTimeActive" SG_ 156 RegenerationSwitchStatus 100;
BA_ "GenSigStartValue" SG_ 156 RegenerationSwitchStatus 7;
BA_ "GenSigMaxLatency" SG_ 156 RegenerationSwitchStatus 20;
BA_ "GenSigCycleTime" SG_ 156 DSWindowPosition 100;
BA_ "GenSigCycleTimeActive" SG_ 156 DSWindowPosition 100;
BA_ "GenSigStartValue" SG_ 156 DSWindowPosition 7;
BA_ "GenSigMaxLatency" SG_ 156 DSWindowPosition 20;
BA_ "GenSigCycleTime" SG_ 156 GearSplit_Status_ISig_5 100;
BA_ "GenSigCycleTimeActive" SG_ 156 GearSplit_Status_ISig_5 100;
BA_ "GenSigStartValue" SG_ 156 GearSplit_Status_ISig_5 3;
BA_ "GenSigMaxLatency" SG_ 156 GearSplit_Status_ISig_5 20;
BA_ "GenSigCycleTime" SG_ 156 KeyPosition_ISig_5 100;
BA_ "GenSigCycleTimeActive" SG_ 156 KeyPosition_ISig_5 100;
BA_ "GenSigStartValue" SG_ 156 KeyPosition_ISig_5 7;
BA_ "GenSigMaxLatency" SG_ 156 KeyPosition_ISig_5 20;
BA_ "GenSigCycleTime" SG_ 156 LiftAxle1LiftFuncSelected_ISig_5 100;
BA_ "GenSigCycleTimeActive" SG_ 156 LiftAxle1LiftFuncSelected_ISig_5 100;
BA_ "GenSigStartValue" SG_ 156 LiftAxle1LiftFuncSelected_ISig_5 7;
BA_ "GenSigMaxLatency" SG_ 156 LiftAxle1LiftFuncSelected_ISig_5 20;
BA_ "GenSigCycleTime" SG_ 156 LiftAxle2UpRequestACK_ISig_5 100;
BA_ "GenSigCycleTimeActive" SG_ 156 LiftAxle2UpRequestACK_ISig_5 100;
BA_ "GenSigStartValue" SG_ 156 LiftAxle2UpRequestACK_ISig_5 7;
BA_ "GenSigMaxLatency" SG_ 156 LiftAxle2UpRequestACK_ISig_5 20;
BA_ "GenSigCycleTime" SG_ 156 PreTrip_ButtonStat3 100;
BA_ "GenSigCycleTimeActive" SG_ 156 PreTrip_ButtonStat3 100;
BA_ "GenSigStartValue" SG_ 156 PreTrip_ButtonStat3 3;
BA_ "GenSigMaxLatency" SG_ 156 PreTrip_ButtonStat3 20;
BA_ "GenSigCycleTime" SG_ 156 LiftAxle1UpRequestACK_ISig_5 100;
BA_ "GenSigCycleTimeActive" SG_ 156 LiftAxle1UpRequestACK_ISig_5 100;
BA_ "GenSigStartValue" SG_ 156 LiftAxle1UpRequestACK_ISig_5 7;
BA_ "GenSigMaxLatency" SG_ 156 LiftAxle1UpRequestACK_ISig_5 20;
BA_ "GenSigCycleTime" SG_ 154 EngineSpeed_ISig_5 100;
BA_ "GenSigCycleTimeActive" SG_ 154 EngineSpeed_ISig_5 100;
BA_ "GenSigStartValue" SG_ 154 EngineSpeed_ISig_5 65535;
BA_ "GenSigMaxLatency" SG_ 154 EngineSpeed_ISig_5 20;
BA_ "GenSigCycleTime" SG_ 154 AutonomyAuthorizationDevInd_ISig 100;
BA_ "GenSigCycleTimeActive" SG_ 154 AutonomyAuthorizationDevInd_ISig 100;
BA_ "GenSigStartValue" SG_ 154 AutonomyAuthorizationDevInd_ISig 3;
BA_ "SystemSignalLongSymbol" SG_ 154 AutonomyAuthorizationDevInd_ISig "AutonomyAuthorizationDevInd_ISig_5";
BA_ "GenSigCycleTime" SG_ 154 SteeringWheelAngle_ISig_5 100;
BA_ "GenSigCycleTimeActive" SG_ 154 SteeringWheelAngle_ISig_5 100;
BA_ "GenSigStartValue" SG_ 154 SteeringWheelAngle_ISig_5 65535;
BA_ "GenSigMaxLatency" SG_ 154 SteeringWheelAngle_ISig_5 20;
BA_ "GenSigCycleTime" SG_ 154 GearLeverPosition_ISig_5 100;
BA_ "GenSigCycleTimeActive" SG_ 154 GearLeverPosition_ISig_5 100;
BA_ "GenSigStartValue" SG_ 154 GearLeverPosition_ISig_5 15;
BA_ "GenSigCycleTime" SG_ 154 LateralAcceleration_ISig_5 100;
BA_ "GenSigCycleTimeActive" SG_ 154 LateralAcceleration_ISig_5 100;
BA_ "GenSigStartValue" SG_ 154 LateralAcceleration_ISig_5 65535;
BA_ "GenSigMaxLatency" SG_ 154 LateralAcceleration_ISig_5 20;
BA_ "GenSigCycleTime" SG_ 138 AcceleratorPedalLowIdleSwitch_IS 100;
BA_ "GenSigCycleTimeActive" SG_ 138 AcceleratorPedalLowIdleSwitch_IS 100;
BA_ "GenSigStartValue" SG_ 138 AcceleratorPedalLowIdleSwitch_IS 3;
BA_ "GenSigMaxLatency" SG_ 138 AcceleratorPedalLowIdleSwitch_IS 10;
BA_ "SystemSignalLongSymbol" SG_ 138 AcceleratorPedalLowIdleSwitch_IS "AcceleratorPedalLowIdleSwitch_ISig_5";
BA_ "GenSigCycleTime" SG_ 138 VehicleMode_ISig_5 100;
BA_ "GenSigCycleTimeActive" SG_ 138 VehicleMode_ISig_5 100;
BA_ "GenSigStartValue" SG_ 138 VehicleMode_ISig_5 15;
BA_ "GenSigCycleTime" SG_ 138 AcceleratorPedalPosition1_ISig_5 100;
BA_ "GenSigCycleTimeActive" SG_ 138 AcceleratorPedalPosition1_ISig_5 100;
BA_ "GenSigStartValue" SG_ 138 AcceleratorPedalPosition1_ISig_5 255;
BA_ "GenSigMaxLatency" SG_ 138 AcceleratorPedalPosition1_ISig_5 10;
BA_ "GenSigCycleTime" SG_ 138 AcceleratorPedalQuality_ISig_5 100;
BA_ "GenSigCycleTimeActive" SG_ 138 AcceleratorPedalQuality_ISig_5 100;
BA_ "GenSigStartValue" SG_ 138 AcceleratorPedalQuality_ISig_5 3;
BA_ "GenSigMaxLatency" SG_ 138 AcceleratorPedalQuality_ISig_5 10;
BA_ "GenSigCycleTime" SG_ 895 DriverCrank_rqst 100;
BA_ "GenSigCycleTimeActive" SG_ 895 DriverCrank_rqst 100;
BA_ "GenSigStartValue" SG_ 895 DriverCrank_rqst 3;
BA_ "GenSigMaxLatency" SG_ 895 DriverCrank_rqst 50;
BA_ "GenSigCycleTime" SG_ 895 EngineStartControlStatus 100;
BA_ "GenSigCycleTimeActive" SG_ 895 EngineStartControlStatus 100;
BA_ "GenSigStartValue" SG_ 895 EngineStartControlStatus 65535;
BA_ "GenSigMaxLatency" SG_ 895 EngineStartControlStatus 50;
BA_ "GenSigCycleTime" SG_ 895 ExtStaticTrailerBrake_Stat 100;
BA_ "GenSigCycleTimeActive" SG_ 895 ExtStaticTrailerBrake_Stat 100;
BA_ "GenSigStartValue" SG_ 895 ExtStaticTrailerBrake_Stat 3;
BA_ "GenSigCycleTime" SG_ 895 WheelBasedVehicleSpd_Value_ISig_ 100;
BA_ "GenSigCycleTimeActive" SG_ 895 WheelBasedVehicleSpd_Value_ISig_ 100;
BA_ "GenSigStartValue" SG_ 895 WheelBasedVehicleSpd_Value_ISig_ 65535;
BA_ "GenSigMaxLatency" SG_ 895 WheelBasedVehicleSpd_Value_ISig_ 100;
BA_ "SystemSignalLongSymbol" SG_ 895 WheelBasedVehicleSpd_Value_ISig_ "WheelBasedVehicleSpd_Value_ISig_5";
BA_ "GenSigCycleTime" SG_ 895 WheelBasedVehicleSpd_CRC_ISig_5 100;
BA_ "GenSigCycleTimeActive" SG_ 895 WheelBasedVehicleSpd_CRC_ISig_5 100;
BA_ "GenSigStartValue" SG_ 895 WheelBasedVehicleSpd_CRC_ISig_5 255;
BA_ "GenSigMaxLatency" SG_ 895 WheelBasedVehicleSpd_CRC_ISig_5 100;
BA_ "E2EDataId" SG_ 895 WheelBasedVehicleSpd_CRC_ISig_5 178;
BA_ "E2EDataLength" SG_ 895 WheelBasedVehicleSpd_CRC_ISig_5 32;
BA_ "E2EProfile" SG_ 895 WheelBasedVehicleSpd_CRC_ISig_5 "P01";
BA_ "GenSigCycleTime" SG_ 895 CabTiltLockStatus 100;
BA_ "GenSigCycleTimeActive" SG_ 895 CabTiltLockStatus 100;
BA_ "GenSigStartValue" SG_ 895 CabTiltLockStatus 3;
BA_ "GenSigMaxLatency" SG_ 895 CabTiltLockStatus 50;
BA_ "GenSigCycleTime" SG_ 895 WheelBasedVehicleSpd_SqC_ISig_5 100;
BA_ "GenSigCycleTimeActive" SG_ 895 WheelBasedVehicleSpd_SqC_ISig_5 100;
BA_ "GenSigStartValue" SG_ 895 WheelBasedVehicleSpd_SqC_ISig_5 14;
BA_ "GenSigMaxLatency" SG_ 895 WheelBasedVehicleSpd_SqC_ISig_5 100;
BA_ "GenSigCycleTime" SG_ 895 CabTiltEnableStatus 100;
BA_ "GenSigCycleTimeActive" SG_ 895 CabTiltEnableStatus 100;
BA_ "GenSigStartValue" SG_ 895 CabTiltEnableStatus 3;
BA_ "GenSigMaxLatency" SG_ 895 CabTiltEnableStatus 50;
BA_ "GenSigSendType" SG_ 2671902706 FuncDiagDataTester_ISig_5 7;
BA_ "GenSigSendType" SG_ 2671902708 FuncDiagDataIntTesterF4_ISig_5 7;
BA_ "GenSigCycleTime" SG_ 1104 CabTilt_rqst 100;
BA_ "GenSigCycleTimeActive" SG_ 1104 CabTilt_rqst 100;
BA_ "GenSigStartValue" SG_ 1104 CabTilt_rqst 3;
BA_ "GenSigMaxLatency" SG_ 1104 CabTilt_rqst 100;
BA_ "GenSigCycleTime" SG_ 1104 PassengersSeatBelt_ISig_5 100;
BA_ "GenSigCycleTimeActive" SG_ 1104 PassengersSeatBelt_ISig_5 100;
BA_ "GenSigStartValue" SG_ 1104 PassengersSeatBelt_ISig_5 7;
BA_ "GenSigCycleTime" SG_ 434 RideHeightFunctionRequest_ISig_5 100;
BA_ "GenSigCycleTimeActive" SG_ 434 RideHeightFunctionRequest_ISig_5 100;
BA_ "GenSigStartValue" SG_ 434 RideHeightFunctionRequest_ISig_5 15;
BA_ "GenSigCycleTime" SG_ 434 AdjustFrontBeamInclination 100;
BA_ "GenSigCycleTimeActive" SG_ 434 AdjustFrontBeamInclination 100;
BA_ "GenSigStartValue" SG_ 434 AdjustFrontBeamInclination 7;
BA_ "GenSigCycleTime" SG_ 434 ExtraMainbeam_SwitchStatus 100;
BA_ "GenSigCycleTimeActive" SG_ 434 ExtraMainbeam_SwitchStatus 100;
BA_ "GenSigStartValue" SG_ 434 ExtraMainbeam_SwitchStatus 3;
BA_ "GenSigCycleTime" SG_ 434 StopLevelChangeRequest_ISig_5 100;
BA_ "GenSigCycleTimeActive" SG_ 434 StopLevelChangeRequest_ISig_5 100;
BA_ "GenSigStartValue" SG_ 434 StopLevelChangeRequest_ISig_5 3;
BA_ "GenSigCycleTime" SG_ 432 StatTrailerBrakeSwitchStatus 100;
BA_ "GenSigCycleTimeActive" SG_ 432 StatTrailerBrakeSwitchStatus 100;
BA_ "GenSigStartValue" SG_ 432 StatTrailerBrakeSwitchStatus 3;
BA_ "GenSigCycleTime" SG_ 432 DRLOverride_SwitchStatus 100;
BA_ "GenSigCycleTimeActive" SG_ 432 DRLOverride_SwitchStatus 100;
BA_ "GenSigStartValue" SG_ 432 DRLOverride_SwitchStatus 3;
BA_ "GenSigCycleTime" SG_ 432 DriverSeatBeltSwitch_ISig_5 100;
BA_ "GenSigCycleTimeActive" SG_ 432 DriverSeatBeltSwitch_ISig_5 100;
BA_ "GenSigStartValue" SG_ 432 DriverSeatBeltSwitch_ISig_5 3;
BA_ "GenSigMaxLatency" SG_ 432 DriverSeatBeltSwitch_ISig_5 50;
BA_ "GenSigCycleTime" SG_ 432 DumpSwitchChangeReq_ISig_5 100;
BA_ "GenSigCycleTimeActive" SG_ 432 DumpSwitchChangeReq_ISig_5 100;
BA_ "GenSigStartValue" SG_ 432 DumpSwitchChangeReq_ISig_5 3;
BA_ "GenSigMaxLatency" SG_ 432 DumpSwitchChangeReq_ISig_5 50;
BA_ "GenSigCycleTime" SG_ 432 StaticCornerLightMode 100;
BA_ "GenSigCycleTimeActive" SG_ 432 StaticCornerLightMode 100;
BA_ "GenSigStartValue" SG_ 432 StaticCornerLightMode 3;
BA_ "GenSigCycleTime" SG_ 432 FrontLidAjar_Stat 100;
BA_ "GenSigCycleTimeActive" SG_ 432 FrontLidAjar_Stat 100;
BA_ "GenSigStartValue" SG_ 432 FrontLidAjar_Stat 3;
BA_ "GenSigMaxLatency" SG_ 432 FrontLidAjar_Stat 50;
BA_ "GenSigCycleTime" SG_ 432 LoadDistributionRequested_ISig_5 100;
BA_ "GenSigCycleTimeActive" SG_ 432 LoadDistributionRequested_ISig_5 100;
BA_ "GenSigStartValue" SG_ 432 LoadDistributionRequested_ISig_5 15;
BA_ "GenSigMaxLatency" SG_ 432 LoadDistributionRequested_ISig_5 50;
BA_ "GenSigCycleTime" SG_ 432 LevelingThumbwheel_stat 100;
BA_ "GenSigCycleTimeActive" SG_ 432 LevelingThumbwheel_stat 100;
BA_ "GenSigStartValue" SG_ 432 LevelingThumbwheel_stat 31;
BA_ "GenSigMaxLatency" SG_ 432 LevelingThumbwheel_stat 50;
BA_REL_ "GenSigFirstTimeoutTime" BU_SG_REL_ CCM SG_ 689 ParkHeaterTimerReleased_stat 3000;
BA_REL_ "GenSigTimeoutTime" BU_SG_REL_ CCM SG_ 689 ParkHeaterTimerReleased_stat 600;
BA_REL_ "GenSigFirstTimeoutTime" BU_SG_REL_ IC SG_ 689 Trail2TPMLostCom 3000;
BA_REL_ "GenSigTimeoutTime" BU_SG_REL_ IC SG_ 689 Trail2TPMLostCom 600;
BA_REL_ "GenSigFirstTimeoutTime" BU_SG_REL_ IC SG_ 689 BrakeInterlockStatus_ISig_5 3000;
BA_REL_ "GenSigTimeoutTime" BU_SG_REL_ IC SG_ 689 BrakeInterlockStatus_ISig_5 600;
BA_REL_ "GenSigFirstTimeoutTime" BU_SG_REL_ IC SG_ 689 AutoWheelBrakesDownshiftSugges_I 3000;
BA_REL_ "GenSigTimeoutTime" BU_SG_REL_ IC SG_ 689 AutoWheelBrakesDownshiftSugges_I 600;
BA_REL_ "GenSigFirstTimeoutTime" BU_SG_REL_ IC SG_ 689 RearAxle2DiffLock_stat_ISig_5 3000;
BA_REL_ "GenSigTimeoutTime" BU_SG_REL_ IC SG_ 689 RearAxle2DiffLock_stat_ISig_5 600;
BA_REL_ "GenSigFirstTimeoutTime" BU_SG_REL_ IC SG_ 689 CentralRearDiffLock_stat_ISig_5 3000;
BA_REL_ "GenSigTimeoutTime" BU_SG_REL_ IC SG_ 689 CentralRearDiffLock_stat_ISig_5 600;
BA_REL_ "GenSigFirstTimeoutTime" BU_SG_REL_ IC SG_ 689 TransmissionBrakeMode_ISig_5 3000;
BA_REL_ "GenSigTimeoutTime" BU_SG_REL_ IC SG_ 689 TransmissionBrakeMode_ISig_5 600;
BA_REL_ "GenSigFirstTimeoutTime" BU_SG_REL_ IC SG_ 689 PS_HeadLightAdjustment 3000;
BA_REL_ "GenSigTimeoutTime" BU_SG_REL_ IC SG_ 689 PS_HeadLightAdjustment 600;
BA_REL_ "GenSigFirstTimeoutTime" BU_SG_REL_ IC SG_ 689 ReducedLoadMode_stat_ISig_5 3000;
BA_REL_ "GenSigTimeoutTime" BU_SG_REL_ IC SG_ 689 ReducedLoadMode_stat_ISig_5 600;
BA_REL_ "GenSigFirstTimeoutTime" BU_SG_REL_ CCM SG_ 689 ReducedLoadMode_stat_ISig_5 3000;
BA_REL_ "GenSigTimeoutTime" BU_SG_REL_ CCM SG_ 689 ReducedLoadMode_stat_ISig_5 600;
BA_REL_ "GenSigFirstTimeoutTime" BU_SG_REL_ IC SG_ 689 FrontWheelDifflockRequest_ISig_5 3000;
BA_REL_ "GenSigTimeoutTime" BU_SG_REL_ IC SG_ 689 FrontWheelDifflockRequest_ISig_5 600;
BA_REL_ "GenSigFirstTimeoutTime" BU_SG_REL_ IC SG_ 689 ABSEBSAmberWarningSignal_ISig_5 3000;
BA_REL_ "GenSigTimeoutTime" BU_SG_REL_ IC SG_ 689 ABSEBSAmberWarningSignal_ISig_5 600;
BA_REL_ "GenSigFirstTimeoutTime" BU_SG_REL_ IC SG_ 689 DifferentialLockStateFrAxle1_ISi 3000;
BA_REL_ "GenSigTimeoutTime" BU_SG_REL_ IC SG_ 689 DifferentialLockStateFrAxle1_ISi 600;
BA_REL_ "GenSigFirstTimeoutTime" BU_SG_REL_ IC SG_ 689 Trail1TPMLostCom 3000;
BA_REL_ "GenSigTimeoutTime" BU_SG_REL_ IC SG_ 689 Trail1TPMLostCom 600;
BA_REL_ "GenSigFirstTimeoutTime" BU_SG_REL_ IC SG_ 689 TrailerInflationPossible_stat_IS 3000;
BA_REL_ "GenSigTimeoutTime" BU_SG_REL_ IC SG_ 689 TrailerInflationPossible_stat_IS 600;
BA_REL_ "GenSigFirstTimeoutTime" BU_SG_REL_ IC SG_ 689 DrivelineRetarderStat_ISig_5 3000;
BA_REL_ "GenSigTimeoutTime" BU_SG_REL_ IC SG_ 689 DrivelineRetarderStat_ISig_5 600;
BA_REL_ "GenSigFirstTimeoutTime" BU_SG_REL_ IC SG_ 689 PS_FogLightRear 3000;
BA_REL_ "GenSigTimeoutTime" BU_SG_REL_ IC SG_ 689 PS_FogLightRear 600;
BA_REL_ "GenSigFirstTimeoutTime" BU_SG_REL_ IC SG_ 689 PS_MainBeam 3000;
BA_REL_ "GenSigTimeoutTime" BU_SG_REL_ IC SG_ 689 PS_MainBeam 600;
BA_REL_ "GenSigFirstTimeoutTime" BU_SG_REL_ IC SG_ 689 DeCompActive_ISig_5 3000;
BA_REL_ "GenSigTimeoutTime" BU_SG_REL_ IC SG_ 689 DeCompActive_ISig_5 600;
BA_REL_ "GenSigFirstTimeoutTime" BU_SG_REL_ IC SG_ 689 ECSManStandbyStatus_ISig_5 3000;
BA_REL_ "GenSigTimeoutTime" BU_SG_REL_ IC SG_ 689 ECSManStandbyStatus_ISig_5 600;
BA_REL_ "GenSigFirstTimeoutTime" BU_SG_REL_ IC SG_ 689 AutoPBRelease_stat_ISig_5 3000;
BA_REL_ "GenSigTimeoutTime" BU_SG_REL_ IC SG_ 689 AutoPBRelease_stat_ISig_5 600;
BA_REL_ "GenSigFirstTimeoutTime" BU_SG_REL_ IC SG_ 689 Trail4TPMLostCom 3000;
BA_REL_ "GenSigTimeoutTime" BU_SG_REL_ IC SG_ 689 Trail4TPMLostCom 600;
BA_REL_ "GenSigFirstTimeoutTime" BU_SG_REL_ IC SG_ 689 EBSRedWarningSignal_ISig_5 3000;
BA_REL_ "GenSigTimeoutTime" BU_SG_REL_ IC SG_ 689 EBSRedWarningSignal_ISig_5 600;
BA_REL_ "GenSigFirstTimeoutTime" BU_SG_REL_ IC SG_ 689 DifferentialLockStateCentral_ISi 3000;
BA_REL_ "GenSigTimeoutTime" BU_SG_REL_ IC SG_ 689 DifferentialLockStateCentral_ISi 600;
BA_REL_ "GenSigFirstTimeoutTime" BU_SG_REL_ IC SG_ 689 RearAxle3DiffLock_stat_ISig_5 3000;
BA_REL_ "GenSigTimeoutTime" BU_SG_REL_ IC SG_ 689 RearAxle3DiffLock_stat_ISig_5 600;
BA_REL_ "GenSigFirstTimeoutTime" BU_SG_REL_ IC SG_ 689 AntiLockBrakingActive_ISig_5 3000;
BA_REL_ "GenSigTimeoutTime" BU_SG_REL_ IC SG_ 689 AntiLockBrakingActive_ISig_5 600;
BA_REL_ "GenSigFirstTimeoutTime" BU_SG_REL_ IC SG_ 689 RearAxle1DiffLock_stat_ISig_5 3000;
BA_REL_ "GenSigTimeoutTime" BU_SG_REL_ IC SG_ 689 RearAxle1DiffLock_stat_ISig_5 600;
BA_REL_ "GenSigFirstTimeoutTime" BU_SG_REL_ IC SG_ 689 Trail5TPMLostCom 3000;
BA_REL_ "GenSigTimeoutTime" BU_SG_REL_ IC SG_ 689 Trail5TPMLostCom 600;
BA_REL_ "GenSigFirstTimeoutTime" BU_SG_REL_ IC SG_ 689 PS_PositionLight 3000;
BA_REL_ "GenSigTimeoutTime" BU_SG_REL_ IC SG_ 689 PS_PositionLight 600;
BA_REL_ "GenSigFirstTimeoutTime" BU_SG_REL_ IC SG_ 689 BatteryCapacity_Ack_ISig_5 3000;
BA_REL_ "GenSigTimeoutTime" BU_SG_REL_ IC SG_ 689 BatteryCapacity_Ack_ISig_5 600;
BA_REL_ "GenSigFirstTimeoutTime" BU_SG_REL_ IC SG_ 689 Trail3TPMLostCom 3000;
BA_REL_ "GenSigTimeoutTime" BU_SG_REL_ IC SG_ 689 Trail3TPMLostCom 600;
BA_REL_ "GenSigFirstTimeoutTime" BU_SG_REL_ IC SG_ 689 ParkBrakeWorkshopMode_ISig_5 3000;
BA_REL_ "GenSigTimeoutTime" BU_SG_REL_ IC SG_ 689 ParkBrakeWorkshopMode_ISig_5 600;
BA_REL_ "GenSigFirstTimeoutTime" BU_SG_REL_ IC SG_ 689 LowTempClutchInfo_ISig_5 3000;
BA_REL_ "GenSigTimeoutTime" BU_SG_REL_ IC SG_ 689 LowTempClutchInfo_ISig_5 600;
BA_REL_ "GenSigFirstTimeoutTime" BU_SG_REL_ IC SG_ 688 APMSafetyWarning_CRC_ISig_5 3000;
BA_REL_ "GenSigTimeoutTime" BU_SG_REL_ IC SG_ 688 APMSafetyWarning_CRC_ISig_5 600;
BA_REL_ "GenSigFirstTimeoutTime" BU_SG_REL_ IC SG_ 688 PBStatus_CRC_ISig_5 3000;
BA_REL_ "GenSigTimeoutTime" BU_SG_REL_ IC SG_ 688 PBStatus_CRC_ISig_5 600;
BA_REL_ "GenSigFirstTimeoutTime" BU_SG_REL_ IC SG_ 688 TrailerWithoutABS_ISig_5 3000;
BA_REL_ "GenSigTimeoutTime" BU_SG_REL_ IC SG_ 688 TrailerWithoutABS_ISig_5 600;
BA_REL_ "GenSigFirstTimeoutTime" BU_SG_REL_ IC SG_ 688 APMSafetyWarning_RedRqst_ISig_5 3000;
BA_REL_ "GenSigTimeoutTime" BU_SG_REL_ IC SG_ 688 APMSafetyWarning_RedRqst_ISig_5 600;
BA_REL_ "GenSigFirstTimeoutTime" BU_SG_REL_ IC SG_ 688 EcoRollEnabledStatus_ISig_5 3000;
BA_REL_ "GenSigTimeoutTime" BU_SG_REL_ IC SG_ 688 EcoRollEnabledStatus_ISig_5 600;
BA_REL_ "GenSigFirstTimeoutTime" BU_SG_REL_ IC SG_ 688 PBStatus_Actuation_ISig_5 3000;
BA_REL_ "GenSigTimeoutTime" BU_SG_REL_ IC SG_ 688 PBStatus_Actuation_ISig_5 600;
BA_REL_ "GenSigFirstTimeoutTime" BU_SG_REL_ IC SG_ 688 GearShiftingRec_Steps_ISig_5 3000;
BA_REL_ "GenSigTimeoutTime" BU_SG_REL_ IC SG_ 688 GearShiftingRec_Steps_ISig_5 600;
BA_REL_ "GenSigFirstTimeoutTime" BU_SG_REL_ IC SG_ 688 PBStatus_IntegrityLvl_ISig_5 3000;
BA_REL_ "GenSigTimeoutTime" BU_SG_REL_ IC SG_ 688 PBStatus_IntegrityLvl_ISig_5 600;
BA_REL_ "GenSigFirstTimeoutTime" BU_SG_REL_ IC SG_ 688 GearShiftingRec_Direction_ISig_5 3000;
BA_REL_ "GenSigTimeoutTime" BU_SG_REL_ IC SG_ 688 GearShiftingRec_Direction_ISig_5 600;
BA_REL_ "GenSigFirstTimeoutTime" BU_SG_REL_ IC SG_ 688 RearPropulsionStat_Rear2Axle_ISi 3000;
BA_REL_ "GenSigTimeoutTime" BU_SG_REL_ IC SG_ 688 RearPropulsionStat_Rear2Axle_ISi 600;
BA_REL_ "GenSigFirstTimeoutTime" BU_SG_REL_ IC SG_ 688 RearPropulsionStat_Rear1Axle_ISi 3000;
BA_REL_ "GenSigTimeoutTime" BU_SG_REL_ IC SG_ 688 RearPropulsionStat_Rear1Axle_ISi 600;
BA_REL_ "GenSigFirstTimeoutTime" BU_SG_REL_ IC SG_ 688 RearPropulsionStat_Rear3Axle_ISi 3000;
BA_REL_ "GenSigTimeoutTime" BU_SG_REL_ IC SG_ 688 RearPropulsionStat_Rear3Axle_ISi 600;
BA_REL_ "GenSigFirstTimeoutTime" BU_SG_REL_ IC SG_ 688 PBStatus_SqC_ISig_5 3000;
BA_REL_ "GenSigTimeoutTime" BU_SG_REL_ IC SG_ 688 PBStatus_SqC_ISig_5 600;
BA_REL_ "GenSigFirstTimeoutTime" BU_SG_REL_ IC SG_ 688 APMSafetyWarning_SqC_ISig_5 3000;
BA_REL_ "GenSigTimeoutTime" BU_SG_REL_ IC SG_ 688 APMSafetyWarning_SqC_ISig_5 600;
BA_REL_ "GenSigFirstTimeoutTime" BU_SG_REL_ IC SG_ 688 APMSafetyWarning_YellowRqst_ISig 3000;
BA_REL_ "GenSigTimeoutTime" BU_SG_REL_ IC SG_ 688 APMSafetyWarning_YellowRqst_ISig 600;
BA_REL_ "GenSigFirstTimeoutTime" BU_SG_REL_ SCIM SG_ 394 FPBRMMIStat_FPBRStatusInd_ISig_5 3000;
BA_REL_ "GenSigTimeoutTime" BU_SG_REL_ SCIM SG_ 394 FPBRMMIStat_FPBRStatusInd_ISig_5 300;
BA_REL_ "GenSigFirstTimeoutTime" BU_SG_REL_ IC SG_ 394 LongitudinalAcceleration_ISig_5 3000;
BA_REL_ "GenSigTimeoutTime" BU_SG_REL_ IC SG_ 394 LongitudinalAcceleration_ISig_5 300;
BA_REL_ "GenSigFirstTimeoutTime" BU_SG_REL_ SCIM SG_ 394 FPBRMMIStat_FPBRChangeAck_ISig_5 3000;
BA_REL_ "GenSigTimeoutTime" BU_SG_REL_ SCIM SG_ 394 FPBRMMIStat_FPBRChangeAck_ISig_5 300;
BA_REL_ "GenSigFirstTimeoutTime" BU_SG_REL_ IC SG_ 394 RssInhibStartEngine_rqst 3000;
BA_REL_ "GenSigTimeoutTime" BU_SG_REL_ IC SG_ 394 RssInhibStartEngine_rqst 300;
BA_REL_ "GenSigFirstTimeoutTime" BU_SG_REL_ IC SG_ 394 MainBeam_rqst 3000;
BA_REL_ "GenSigTimeoutTime" BU_SG_REL_ IC SG_ 394 MainBeam_rqst 300;
BA_REL_ "GenSigFirstTimeoutTime" BU_SG_REL_ SCIM SG_ 394 DumpSwitchChangeAck_ISig_5 3000;
BA_REL_ "GenSigTimeoutTime" BU_SG_REL_ SCIM SG_ 394 DumpSwitchChangeAck_ISig_5 300;
BA_REL_ "GenSigFirstTimeoutTime" BU_SG_REL_ IC SG_ 394 CCSetSpeed_ISig_5 3000;
BA_REL_ "GenSigTimeoutTime" BU_SG_REL_ IC SG_ 394 CCSetSpeed_ISig_5 300;
BA_REL_ "GenSigFirstTimeoutTime" BU_SG_REL_ IC SG_ 393 EngineActiveStatus_ISig_5 3000;
BA_REL_ "GenSigTimeoutTime" BU_SG_REL_ IC SG_ 393 EngineActiveStatus_ISig_5 300;
BA_REL_ "GenSigFirstTimeoutTime" BU_SG_REL_ IC SG_ 393 BackLightDimming_Status3 3000;
BA_REL_ "GenSigTimeoutTime" BU_SG_REL_ IC SG_ 393 BackLightDimming_Status3 300;
BA_REL_ "GenSigFirstTimeoutTime" BU_SG_REL_ IC SG_ 393 FrontAxleSpeed_ISig_5 3000;
BA_REL_ "GenSigTimeoutTime" BU_SG_REL_ IC SG_ 393 FrontAxleSpeed_ISig_5 300;
BA_REL_ "GenSigFirstTimeoutTime" BU_SG_REL_ IC SG_ 393 BrakePedalTestState_ISig_5 3000;
BA_REL_ "GenSigTimeoutTime" BU_SG_REL_ IC SG_ 393 BrakePedalTestState_ISig_5 300;
BA_REL_ "GenSigFirstTimeoutTime" BU_SG_REL_ IC SG_ 393 ParkBrakeApplicationMode2_ISig_5 3000;
BA_REL_ "GenSigTimeoutTime" BU_SG_REL_ IC SG_ 393 ParkBrakeApplicationMode2_ISig_5 300;
BA_REL_ "GenSigFirstTimeoutTime" BU_SG_REL_ IC SG_ 393 RampLevelStatus_ISig_5 3000;
BA_REL_ "GenSigTimeoutTime" BU_SG_REL_ IC SG_ 393 RampLevelStatus_ISig_5 300;
BA_REL_ "GenSigFirstTimeoutTime" BU_SG_REL_ IC SG_ 393 ParkBrakeReleaseMode2_ISig_5 3000;
BA_REL_ "GenSigTimeoutTime" BU_SG_REL_ IC SG_ 393 ParkBrakeReleaseMode2_ISig_5 300;
BA_REL_ "GenSigFirstTimeoutTime" BU_SG_REL_ IC SG_ 393 BackLightDimming_Status 3000;
BA_REL_ "GenSigTimeoutTime" BU_SG_REL_ IC SG_ 393 BackLightDimming_Status 300;
BA_REL_ "GenSigFirstTimeoutTime" BU_SG_REL_ IC SG_ 393 HeightControlMode_ISig_5 3000;
BA_REL_ "GenSigTimeoutTime" BU_SG_REL_ IC SG_ 393 HeightControlMode_ISig_5 300;
BA_REL_ "GenSigFirstTimeoutTime" BU_SG_REL_ IC SG_ 393 FifthWheelLockingInformation_ISi 3000;
BA_REL_ "GenSigTimeoutTime" BU_SG_REL_ IC SG_ 393 FifthWheelLockingInformation_ISi 300;
BA_REL_ "GenSigFirstTimeoutTime" BU_SG_REL_ IC SG_ 392 FirstAxleLowerPrioSelected_ISig_ 3000;
BA_REL_ "GenSigTimeoutTime" BU_SG_REL_ IC SG_ 392 FirstAxleLowerPrioSelected_ISig_ 300;
BA_REL_ "GenSigFirstTimeoutTime" BU_SG_REL_ IC SG_ 392 ESCState_ISig_5 3000;
BA_REL_ "GenSigTimeoutTime" BU_SG_REL_ IC SG_ 392 ESCState_ISig_5 300;
BA_REL_ "GenSigFirstTimeoutTime" BU_SG_REL_ IC SG_ 392 KneelingInformation_ISig_5 3000;
BA_REL_ "GenSigTimeoutTime" BU_SG_REL_ IC SG_ 392 KneelingInformation_ISig_5 300;
BA_REL_ "GenSigFirstTimeoutTime" BU_SG_REL_ IC SG_ 392 TrailerTest_stat_ISig_5 3000;
BA_REL_ "GenSigTimeoutTime" BU_SG_REL_ IC SG_ 392 TrailerTest_stat_ISig_5 300;
BA_REL_ "GenSigFirstTimeoutTime" BU_SG_REL_ IC SG_ 392 ThreePosDifflockSwitch_stat 3000;
BA_REL_ "GenSigTimeoutTime" BU_SG_REL_ IC SG_ 392 ThreePosDifflockSwitch_stat 300;
BA_REL_ "GenSigFirstTimeoutTime" BU_SG_REL_ IC SG_ 392 HillHolderMode_ISig_5 3000;
BA_REL_ "GenSigTimeoutTime" BU_SG_REL_ IC SG_ 392 HillHolderMode_ISig_5 300;
BA_REL_ "GenSigFirstTimeoutTime" BU_SG_REL_ IC SG_ 392 RampHeightOutsideTargetRange_ISi 3000;
BA_REL_ "GenSigTimeoutTime" BU_SG_REL_ IC SG_ 392 RampHeightOutsideTargetRange_ISi 300;
BA_REL_ "GenSigFirstTimeoutTime" BU_SG_REL_ CCM SG_ 392 ShortStopHeater_status_ISig_5 3000;
BA_REL_ "GenSigTimeoutTime" BU_SG_REL_ CCM SG_ 392 ShortStopHeater_status_ISig_5 300;
BA_REL_ "GenSigFirstTimeoutTime" BU_SG_REL_ IC SG_ 392 LuggageAjar_stat 3000;
BA_REL_ "GenSigTimeoutTime" BU_SG_REL_ IC SG_ 392 LuggageAjar_stat 300;
BA_REL_ "GenSigFirstTimeoutTime" BU_SG_REL_ SCIM SG_ 392 LoadDistributionRequestedACK_ISi 3000;
BA_REL_ "GenSigTimeoutTime" BU_SG_REL_ SCIM SG_ 392 LoadDistributionRequestedACK_ISi 300;
BA_REL_ "GenSigFirstTimeoutTime" BU_SG_REL_ IC SG_ 392 LoadDistributionRequestedACK_ISi 3000;
BA_REL_ "GenSigTimeoutTime" BU_SG_REL_ IC SG_ 392 LoadDistributionRequestedACK_ISi 300;
BA_REL_ "GenSigFirstTimeoutTime" BU_SG_REL_ IC SG_ 392 StretchBrake_Stat_ISig_5 3000;
BA_REL_ "GenSigTimeoutTime" BU_SG_REL_ IC SG_ 392 StretchBrake_Stat_ISig_5 300;
BA_REL_ "GenSigFirstTimeoutTime" BU_SG_REL_ IC SG_ 392 MirrorHeatingMode 3000;
BA_REL_ "GenSigTimeoutTime" BU_SG_REL_ IC SG_ 392 MirrorHeatingMode 300;
BA_REL_ "GenSigFirstTimeoutTime" BU_SG_REL_ CCM SG_ 392 MirrorHeatingMode 3000;
BA_REL_ "GenSigTimeoutTime" BU_SG_REL_ CCM SG_ 392 MirrorHeatingMode 300;
BA_REL_ "GenSigFirstTimeoutTime" BU_SG_REL_ IC SG_ 392 ESCStatus_ISig_5 3000;
BA_REL_ "GenSigTimeoutTime" BU_SG_REL_ IC SG_ 392 ESCStatus_ISig_5 300;
BA_REL_ "GenSigFirstTimeoutTime" BU_SG_REL_ IC SG_ 392 DriverRetarderRequest_ISig_5 3000;
BA_REL_ "GenSigTimeoutTime" BU_SG_REL_ IC SG_ 392 DriverRetarderRequest_ISig_5 300;
BA_REL_ "GenSigFirstTimeoutTime" BU_SG_REL_ IC SG_ 392 PBReleaseAcceptance_stat_ISig_5 3000;
BA_REL_ "GenSigTimeoutTime" BU_SG_REL_ IC SG_ 392 PBReleaseAcceptance_stat_ISig_5 300;
BA_REL_ "GenSigFirstTimeoutTime" BU_SG_REL_ CCM SG_ 392 PSWindowPosition 3000;
BA_REL_ "GenSigTimeoutTime" BU_SG_REL_ CCM SG_ 392 PSWindowPosition 300;
BA_REL_ "GenSigFirstTimeoutTime" BU_SG_REL_ IC SG_ 392 RideHeightOutsideTargetRange_ISi 3000;
BA_REL_ "GenSigTimeoutTime" BU_SG_REL_ IC SG_ 392 RideHeightOutsideTargetRange_ISi 300;
BA_REL_ "GenSigFirstTimeoutTime" BU_SG_REL_ IC SG_ 392 DriveLevelPosUserInteraction_ISi 3000;
BA_REL_ "GenSigTimeoutTime" BU_SG_REL_ IC SG_ 392 DriveLevelPosUserInteraction_ISi 300;
BA_REL_ "GenSigFirstTimeoutTime" BU_SG_REL_ IC SG_ 392 HillStartAidStatus_ISig_5 3000;
BA_REL_ "GenSigTimeoutTime" BU_SG_REL_ IC SG_ 392 HillStartAidStatus_ISig_5 300;
BA_REL_ "GenSigFirstTimeoutTime" BU_SG_REL_ IC SG_ 391 AcceleratorPedalTestStatus 3000;
BA_REL_ "GenSigTimeoutTime" BU_SG_REL_ IC SG_ 391 AcceleratorPedalTestStatus 300;
BA_REL_ "GenSigFirstTimeoutTime" BU_SG_REL_ IC SG_ 391 ESCDriverReq_ISig_5 3000;
BA_REL_ "GenSigTimeoutTime" BU_SG_REL_ IC SG_ 391 ESCDriverReq_ISig_5 300;
BA_REL_ "GenSigFirstTimeoutTime" BU_SG_REL_ IC SG_ 391 UnevenLoadWarning_ISig_5 3000;
BA_REL_ "GenSigTimeoutTime" BU_SG_REL_ IC SG_ 391 UnevenLoadWarning_ISig_5 300;
BA_REL_ "GenSigFirstTimeoutTime" BU_SG_REL_ IC SG_ 391 RrInterAxlDiffLockActvnFuncReq_I 3000;
BA_REL_ "GenSigTimeoutTime" BU_SG_REL_ IC SG_ 391 RrInterAxlDiffLockActvnFuncReq_I 300;
BA_REL_ "GenSigFirstTimeoutTime" BU_SG_REL_ IC SG_ 391 DoorsAjar_stat_ISig_5 3000;
BA_REL_ "GenSigTimeoutTime" BU_SG_REL_ IC SG_ 391 DoorsAjar_stat_ISig_5 300;
BA_REL_ "GenSigFirstTimeoutTime" BU_SG_REL_ IC SG_ 391 ABSManAutoInhibitionStat_ISig_5 3000;
BA_REL_ "GenSigTimeoutTime" BU_SG_REL_ IC SG_ 391 ABSManAutoInhibitionStat_ISig_5 300;
BA_REL_ "GenSigFirstTimeoutTime" BU_SG_REL_ IC SG_ 391 RrInterAxlDiffLockActvnDrvrReq_I 3000;
BA_REL_ "GenSigTimeoutTime" BU_SG_REL_ IC SG_ 391 RrInterAxlDiffLockActvnDrvrReq_I 300;
BA_REL_ "GenSigFirstTimeoutTime" BU_SG_REL_ IC SG_ 391 EngineOilTempHigh_ISig_5 3000;
BA_REL_ "GenSigTimeoutTime" BU_SG_REL_ IC SG_ 391 EngineOilTempHigh_ISig_5 300;
BA_REL_ "GenSigFirstTimeoutTime" BU_SG_REL_ IC SG_ 391 StartupProhibitStatus_ISig_5 3000;
BA_REL_ "GenSigTimeoutTime" BU_SG_REL_ IC SG_ 391 StartupProhibitStatus_ISig_5 300;
BA_REL_ "GenSigFirstTimeoutTime" BU_SG_REL_ IC SG_ 391 AuxBrakesDwngrdModeInd_rqst 3000;
BA_REL_ "GenSigTimeoutTime" BU_SG_REL_ IC SG_ 391 AuxBrakesDwngrdModeInd_rqst 300;
BA_REL_ "GenSigFirstTimeoutTime" BU_SG_REL_ CCM SG_ 391 ElectricalLoadReduction_rqst_ISi 3000;
BA_REL_ "GenSigTimeoutTime" BU_SG_REL_ CCM SG_ 391 ElectricalLoadReduction_rqst_ISi 300;
BA_REL_ "GenSigFirstTimeoutTime" BU_SG_REL_ IC SG_ 391 LoadDistributionChangeACK_ISig_5 3000;
BA_REL_ "GenSigTimeoutTime" BU_SG_REL_ IC SG_ 391 LoadDistributionChangeACK_ISig_5 300;
BA_REL_ "GenSigFirstTimeoutTime" BU_SG_REL_ SCIM SG_ 391 LoadDistributionChangeACK_ISig_5 3000;
BA_REL_ "GenSigTimeoutTime" BU_SG_REL_ SCIM SG_ 391 LoadDistributionChangeACK_ISig_5 300;
BA_REL_ "GenSigFirstTimeoutTime" BU_SG_REL_ SCIM SG_ 391 FerryFunctionStatus_ISig_5 3000;
BA_REL_ "GenSigTimeoutTime" BU_SG_REL_ SCIM SG_ 391 FerryFunctionStatus_ISig_5 300;
BA_REL_ "GenSigFirstTimeoutTime" BU_SG_REL_ IC SG_ 391 FerryFunctionStatus_ISig_5 3000;
BA_REL_ "GenSigTimeoutTime" BU_SG_REL_ IC SG_ 391 FerryFunctionStatus_ISig_5 300;
BA_REL_ "GenSigFirstTimeoutTime" BU_SG_REL_ IC SG_ 391 ClutchOverloadStatus_ISig_5 3000;
BA_REL_ "GenSigTimeoutTime" BU_SG_REL_ IC SG_ 391 ClutchOverloadStatus_ISig_5 300;
BA_REL_ "GenSigFirstTimeoutTime" BU_SG_REL_ IC SG_ 391 RollerBenchModeStatus_ISig_5 3000;
BA_REL_ "GenSigTimeoutTime" BU_SG_REL_ IC SG_ 391 RollerBenchModeStatus_ISig_5 300;
BA_REL_ "GenSigFirstTimeoutTime" BU_SG_REL_ IC SG_ 391 LoadDistributionALDChangeACK_ISi 3000;
BA_REL_ "GenSigTimeoutTime" BU_SG_REL_ IC SG_ 391 LoadDistributionALDChangeACK_ISi 300;
BA_REL_ "GenSigFirstTimeoutTime" BU_SG_REL_ SCIM SG_ 391 LoadDistributionALDChangeACK_ISi 3000;
BA_REL_ "GenSigTimeoutTime" BU_SG_REL_ SCIM SG_ 391 LoadDistributionALDChangeACK_ISi 300;
BA_REL_ "GenSigFirstTimeoutTime" BU_SG_REL_ IC SG_ 391 EngineSpeedControlStatus 3000;
BA_REL_ "GenSigTimeoutTime" BU_SG_REL_ IC SG_ 391 EngineSpeedControlStatus 300;
BA_REL_ "GenSigFirstTimeoutTime" BU_SG_REL_ IC SG_ 391 DTCActive_ISig_5 3000;
BA_REL_ "GenSigTimeoutTime" BU_SG_REL_ IC SG_ 391 DTCActive_ISig_5 300;
BA_REL_ "GenSigFirstTimeoutTime" BU_SG_REL_ IC SG_ 390 PS_SevereEngAndBrkOverspdWarn_IS 3000;
BA_REL_ "GenSigTimeoutTime" BU_SG_REL_ IC SG_ 390 PS_SevereEngAndBrkOverspdWarn_IS 300;
BA_REL_ "GenSigFirstTimeoutTime" BU_SG_REL_ SCIM SG_ 390 RearFog_Indication 3000;
BA_REL_ "GenSigTimeoutTime" BU_SG_REL_ SCIM SG_ 390 RearFog_Indication 300;
BA_REL_ "GenSigFirstTimeoutTime" BU_SG_REL_ IC SG_ 390 SasAdaptationInProgress_ISig_5 3000;
BA_REL_ "GenSigTimeoutTime" BU_SG_REL_ IC SG_ 390 SasAdaptationInProgress_ISig_5 300;
BA_REL_ "GenSigFirstTimeoutTime" BU_SG_REL_ IC SG_ 390 SplitBoxDifflockActvnDrvrRqst_IS 3000;
BA_REL_ "GenSigTimeoutTime" BU_SG_REL_ IC SG_ 390 SplitBoxDifflockActvnDrvrRqst_IS 300;
BA_REL_ "GenSigFirstTimeoutTime" BU_SG_REL_ IC SG_ 390 EcoRollActiveStatus_ISig_5 3000;
BA_REL_ "GenSigTimeoutTime" BU_SG_REL_ IC SG_ 390 EcoRollActiveStatus_ISig_5 300;
BA_REL_ "GenSigFirstTimeoutTime" BU_SG_REL_ IC SG_ 390 PloughLampModeStatus_ISig_5 3000;
BA_REL_ "GenSigTimeoutTime" BU_SG_REL_ IC SG_ 390 PloughLampModeStatus_ISig_5 300;
BA_REL_ "GenSigFirstTimeoutTime" BU_SG_REL_ IC SG_ 390 RrRrItrWhlDiffLckActvnDrvrReq_IS 3000;
BA_REL_ "GenSigTimeoutTime" BU_SG_REL_ IC SG_ 390 RrRrItrWhlDiffLckActvnDrvrReq_IS 300;
BA_REL_ "GenSigFirstTimeoutTime" BU_SG_REL_ IC SG_ 390 DrvrRetarderBrakeProgram_rqst_IS 3000;
BA_REL_ "GenSigTimeoutTime" BU_SG_REL_ IC SG_ 390 DrvrRetarderBrakeProgram_rqst_IS 300;
BA_REL_ "GenSigFirstTimeoutTime" BU_SG_REL_ IC SG_ 390 PS_EngOverSpeedSevereWarning_ISi 3000;
BA_REL_ "GenSigTimeoutTime" BU_SG_REL_ IC SG_ 390 PS_EngOverSpeedSevereWarning_ISi 300;
BA_REL_ "GenSigFirstTimeoutTime" BU_SG_REL_ IC SG_ 390 ParkBrakeReleasePossible_stat_IS 3000;
BA_REL_ "GenSigTimeoutTime" BU_SG_REL_ IC SG_ 390 ParkBrakeReleasePossible_stat_IS 300;
BA_REL_ "GenSigFirstTimeoutTime" BU_SG_REL_ IC SG_ 390 StoreIdleValue_ISig_5 3000;
BA_REL_ "GenSigTimeoutTime" BU_SG_REL_ IC SG_ 390 StoreIdleValue_ISig_5 300;
BA_REL_ "GenSigFirstTimeoutTime" BU_SG_REL_ IC SG_ 390 AutRrAxleDiffLockActvnDrvrReq_IS 3000;
BA_REL_ "GenSigTimeoutTime" BU_SG_REL_ IC SG_ 390 AutRrAxleDiffLockActvnDrvrReq_IS 300;
BA_REL_ "GenSigFirstTimeoutTime" BU_SG_REL_ IC SG_ 390 TransmLowRangeSenseSwitch_ISig_5 3000;
BA_REL_ "GenSigTimeoutTime" BU_SG_REL_ IC SG_ 390 TransmLowRangeSenseSwitch_ISig_5 300;
BA_REL_ "GenSigFirstTimeoutTime" BU_SG_REL_ IC SG_ 390 PBStatusDisplay_cmd_ISig_5 3000;
BA_REL_ "GenSigTimeoutTime" BU_SG_REL_ IC SG_ 390 PBStatusDisplay_cmd_ISig_5 300;
BA_REL_ "GenSigFirstTimeoutTime" BU_SG_REL_ IC SG_ 390 AutoRearAxleDiffLockFnc_stat_ISi 3000;
BA_REL_ "GenSigTimeoutTime" BU_SG_REL_ IC SG_ 390 AutoRearAxleDiffLockFnc_stat_ISi 300;
BA_REL_ "GenSigFirstTimeoutTime" BU_SG_REL_ IC SG_ 390 PoorBrakePerformanceWarning_ISig 3000;
BA_REL_ "GenSigTimeoutTime" BU_SG_REL_ IC SG_ 390 PoorBrakePerformanceWarning_ISig 300;
BA_REL_ "GenSigFirstTimeoutTime" BU_SG_REL_ IC SG_ 390 FrontParkBrakeOverrideInd_ISig_5 3000;
BA_REL_ "GenSigTimeoutTime" BU_SG_REL_ IC SG_ 390 FrontParkBrakeOverrideInd_ISig_5 300;
BA_REL_ "GenSigFirstTimeoutTime" BU_SG_REL_ IC SG_ 390 ProhibitControlStatus_ISig_5 3000;
BA_REL_ "GenSigTimeoutTime" BU_SG_REL_ IC SG_ 390 ProhibitControlStatus_ISig_5 300;
BA_REL_ "GenSigFirstTimeoutTime" BU_SG_REL_ IC SG_ 390 PositionLightRequest_status 3000;
BA_REL_ "GenSigTimeoutTime" BU_SG_REL_ IC SG_ 390 PositionLightRequest_status 300;
BA_REL_ "GenSigFirstTimeoutTime" BU_SG_REL_ IC SG_ 390 DoubleFrontAxleSteeringWarning_I 3000;
BA_REL_ "GenSigTimeoutTime" BU_SG_REL_ IC SG_ 390 DoubleFrontAxleSteeringWarning_I 300;
BA_REL_ "GenSigFirstTimeoutTime" BU_SG_REL_ IC SG_ 390 TrailerABSStatus_ISig_5 3000;
BA_REL_ "GenSigTimeoutTime" BU_SG_REL_ IC SG_ 390 TrailerABSStatus_ISig_5 300;
BA_REL_ "GenSigFirstTimeoutTime" BU_SG_REL_ IC SG_ 390 LoadCutOffIndication_cmd_ISig_5 3000;
BA_REL_ "GenSigTimeoutTime" BU_SG_REL_ IC SG_ 390 LoadCutOffIndication_cmd_ISig_5 300;
BA_REL_ "GenSigFirstTimeoutTime" BU_SG_REL_ IC SG_ 390 PtosStatus_ISig_5 3000;
BA_REL_ "GenSigTimeoutTime" BU_SG_REL_ IC SG_ 390 PtosStatus_ISig_5 300;
BA_REL_ "GenSigFirstTimeoutTime" BU_SG_REL_ CCM SG_ 390 PtosStatus_ISig_5 3000;
BA_REL_ "GenSigTimeoutTime" BU_SG_REL_ CCM SG_ 390 PtosStatus_ISig_5 300;
BA_REL_ "GenSigFirstTimeoutTime" BU_SG_REL_ IC SG_ 390 REM_PhoneButtonInd_cmd 3000;
BA_REL_ "GenSigTimeoutTime" BU_SG_REL_ IC SG_ 390 REM_PhoneButtonInd_cmd 300;
BA_REL_ "GenSigFirstTimeoutTime" BU_SG_REL_ IC SG_ 390 TrailerBrake_Stat_ISig_5 3000;
BA_REL_ "GenSigTimeoutTime" BU_SG_REL_ IC SG_ 390 TrailerBrake_Stat_ISig_5 300;
BA_REL_ "GenSigFirstTimeoutTime" BU_SG_REL_ IC SG_ 390 SEM2_PhoneButtonInd_cmd 3000;
BA_REL_ "GenSigTimeoutTime" BU_SG_REL_ IC SG_ 390 SEM2_PhoneButtonInd_cmd 300;
BA_REL_ "GenSigFirstTimeoutTime" BU_SG_REL_ IC SG_ 390 GearRangeUnengaged_ISig_5 3000;
BA_REL_ "GenSigTimeoutTime" BU_SG_REL_ IC SG_ 390 GearRangeUnengaged_ISig_5 300;
BA_REL_ "GenSigFirstTimeoutTime" BU_SG_REL_ IC SG_ 390 ABSOffRoadStatus_ISig_5 3000;
BA_REL_ "GenSigTimeoutTime" BU_SG_REL_ IC SG_ 390 ABSOffRoadStatus_ISig_5 300;
BA_REL_ "GenSigFirstTimeoutTime" BU_SG_REL_ IC SG_ 390 DrvrRetarderBrakeBlending_rqst_I 3000;
BA_REL_ "GenSigTimeoutTime" BU_SG_REL_ IC SG_ 390 DrvrRetarderBrakeBlending_rqst_I 300;
BA_REL_ "GenSigFirstTimeoutTime" BU_SG_REL_ CCM SG_ 389 PHTimerRqstAck_Minutes 3000;
BA_REL_ "GenSigTimeoutTime" BU_SG_REL_ CCM SG_ 389 PHTimerRqstAck_Minutes 300;
BA_REL_ "GenSigFirstTimeoutTime" BU_SG_REL_ IC SG_ 389 RearAxleDiffLockActvnDrvrReq_ISi 3000;
BA_REL_ "GenSigTimeoutTime" BU_SG_REL_ IC SG_ 389 RearAxleDiffLockActvnDrvrReq_ISi 300;
BA_REL_ "GenSigFirstTimeoutTime" BU_SG_REL_ IC SG_ 389 FrRrItrWhlDiffLckActvnDrvrReq_IS 3000;
BA_REL_ "GenSigTimeoutTime" BU_SG_REL_ IC SG_ 389 FrRrItrWhlDiffLckActvnDrvrReq_IS 300;
BA_REL_ "GenSigFirstTimeoutTime" BU_SG_REL_ IC SG_ 389 DriverLocation_CRC_ISig_5 3000;
BA_REL_ "GenSigTimeoutTime" BU_SG_REL_ IC SG_ 389 DriverLocation_CRC_ISig_5 300;
BA_REL_ "GenSigFirstTimeoutTime" BU_SG_REL_ IC SG_ 389 RegenInhibDueHeight_ISig_5 3000;
BA_REL_ "GenSigTimeoutTime" BU_SG_REL_ IC SG_ 389 RegenInhibDueHeight_ISig_5 300;
BA_REL_ "GenSigFirstTimeoutTime" BU_SG_REL_ IC SG_ 389 DriverLocation_Status_ISig_5 3000;
BA_REL_ "GenSigTimeoutTime" BU_SG_REL_ IC SG_ 389 DriverLocation_Status_ISig_5 300;
BA_REL_ "GenSigFirstTimeoutTime" BU_SG_REL_ CCM SG_ 389 PHTimerRqstAck_Hours 3000;
BA_REL_ "GenSigTimeoutTime" BU_SG_REL_ CCM SG_ 389 PHTimerRqstAck_Hours 300;
BA_REL_ "GenSigFirstTimeoutTime" BU_SG_REL_ IC SG_ 389 PoorAirPressureInfo_ISig_5 3000;
BA_REL_ "GenSigTimeoutTime" BU_SG_REL_ IC SG_ 389 PoorAirPressureInfo_ISig_5 300;
BA_REL_ "GenSigFirstTimeoutTime" BU_SG_REL_ IC SG_ 389 DriverLocation_SqC_ISig_5 3000;
BA_REL_ "GenSigTimeoutTime" BU_SG_REL_ IC SG_ 389 DriverLocation_SqC_ISig_5 300;
BA_REL_ "GenSigFirstTimeoutTime" BU_SG_REL_ IC SG_ 389 XRSLControllerMode_ISig_5 3000;
BA_REL_ "GenSigTimeoutTime" BU_SG_REL_ IC SG_ 389 XRSLControllerMode_ISig_5 300;
BA_REL_ "GenSigFirstTimeoutTime" BU_SG_REL_ CCM SG_ 389 PHTimerRqstAck_DayOfWeekRq 3000;
BA_REL_ "GenSigTimeoutTime" BU_SG_REL_ CCM SG_ 389 PHTimerRqstAck_DayOfWeekRq 300;
BA_REL_ "GenSigFirstTimeoutTime" BU_SG_REL_ IC SG_ 389 VIN_rqst_ISig_5 3000;
BA_REL_ "GenSigTimeoutTime" BU_SG_REL_ IC SG_ 389 VIN_rqst_ISig_5 300;
BA_REL_ "GenSigFirstTimeoutTime" BU_SG_REL_ CCM SG_ 389 PHTimerRqstAck_CurrentOp 3000;
BA_REL_ "GenSigTimeoutTime" BU_SG_REL_ CCM SG_ 389 PHTimerRqstAck_CurrentOp 300;
BA_REL_ "GenSigFirstTimeoutTime" BU_SG_REL_ IC SG_ 389 DriverLocation_ConfidenceLvl_ISi 3000;
BA_REL_ "GenSigTimeoutTime" BU_SG_REL_ IC SG_ 389 DriverLocation_ConfidenceLvl_ISi 300;
BA_REL_ "GenSigFirstTimeoutTime" BU_SG_REL_ IC SG_ 389 PS_EngineBrakeOverSpeedWarning_I 3000;
BA_REL_ "GenSigTimeoutTime" BU_SG_REL_ IC SG_ 389 PS_EngineBrakeOverSpeedWarning_I 300;
BA_REL_ "GenSigFirstTimeoutTime" BU_SG_REL_ IC SG_ 389 TrcnCtrlSlipperyRoadWarning_ISig 3000;
BA_REL_ "GenSigTimeoutTime" BU_SG_REL_ IC SG_ 389 TrcnCtrlSlipperyRoadWarning_ISig 300;
BA_REL_ "GenSigFirstTimeoutTime" BU_SG_REL_ IC SG_ 389 TransmissionAirPressureLow_ISig_ 3000;
BA_REL_ "GenSigTimeoutTime" BU_SG_REL_ IC SG_ 389 TransmissionAirPressureLow_ISig_ 300;
BA_REL_ "GenSigFirstTimeoutTime" BU_SG_REL_ IC SG_ 158 SecuredNeutralPosition_ISig_5 3000;
BA_REL_ "GenSigTimeoutTime" BU_SG_REL_ IC SG_ 158 SecuredNeutralPosition_ISig_5 120;
BA_REL_ "GenSigFirstTimeoutTime" BU_SG_REL_ IC SG_ 158 MirrorSelectLeftWideBtn_stat 3000;
BA_REL_ "GenSigTimeoutTime" BU_SG_REL_ IC SG_ 158 MirrorSelectLeftWideBtn_stat 120;
BA_REL_ "GenSigFirstTimeoutTime" BU_SG_REL_ IC SG_ 158 BunkH1AudioOnOff_ButtonStatus 3000;
BA_REL_ "GenSigTimeoutTime" BU_SG_REL_ IC SG_ 158 BunkH1AudioOnOff_ButtonStatus 120;
BA_REL_ "GenSigFirstTimeoutTime" BU_SG_REL_ IC SG_ 158 OverSteerGuidanceStatus_ISig_5 3000;
BA_REL_ "GenSigTimeoutTime" BU_SG_REL_ IC SG_ 158 OverSteerGuidanceStatus_ISig_5 120;
BA_REL_ "GenSigFirstTimeoutTime" BU_SG_REL_ IC SG_ 158 MirrorSelectLeftMainBtn_stat 3000;
BA_REL_ "GenSigTimeoutTime" BU_SG_REL_ IC SG_ 158 MirrorSelectLeftMainBtn_stat 120;
BA_REL_ "GenSigFirstTimeoutTime" BU_SG_REL_ IC SG_ 158 LECM_CabClim_Auto_BtnStat 3000;
BA_REL_ "GenSigTimeoutTime" BU_SG_REL_ IC SG_ 158 LECM_CabClim_Auto_BtnStat 120;
BA_REL_ "GenSigFirstTimeoutTime" BU_SG_REL_ IC SG_ 158 LECM_Display_Navi_OK_BtnStat 3000;
BA_REL_ "GenSigTimeoutTime" BU_SG_REL_ IC SG_ 158 LECM_Display_Navi_OK_BtnStat 120;
BA_REL_ "GenSigFirstTimeoutTime" BU_SG_REL_ IC SG_ 158 LECM_CabClim_AC_BtnStat 3000;
BA_REL_ "GenSigTimeoutTime" BU_SG_REL_ IC SG_ 158 LECM_CabClim_AC_BtnStat 120;
BA_REL_ "GenSigFirstTimeoutTime" BU_SG_REL_ IC SG_ 158 LECMCabClimSetTempSelectGuiReq 3000;
BA_REL_ "GenSigTimeoutTime" BU_SG_REL_ IC SG_ 158 LECMCabClimSetTempSelectGuiReq 120;
BA_REL_ "GenSigFirstTimeoutTime" BU_SG_REL_ IC SG_ 158 MirrorSelectRightMainBtn_stat 3000;
BA_REL_ "GenSigTimeoutTime" BU_SG_REL_ IC SG_ 158 MirrorSelectRightMainBtn_stat 120;
BA_REL_ "GenSigFirstTimeoutTime" BU_SG_REL_ SCIM SG_ 158 DaytimeRunningLight_Indication 3000;
BA_REL_ "GenSigTimeoutTime" BU_SG_REL_ SCIM SG_ 158 DaytimeRunningLight_Indication 120;
BA_REL_ "GenSigFirstTimeoutTime" BU_SG_REL_ SCIM SG_ 158 DrivingLight_Indication 3000;
BA_REL_ "GenSigTimeoutTime" BU_SG_REL_ SCIM SG_ 158 DrivingLight_Indication 120;
BA_REL_ "GenSigFirstTimeoutTime" BU_SG_REL_ SCIM SG_ 158 FrontFog_Indication 3000;
BA_REL_ "GenSigTimeoutTime" BU_SG_REL_ SCIM SG_ 158 FrontFog_Indication 120;
BA_REL_ "GenSigFirstTimeoutTime" BU_SG_REL_ IC SG_ 158 KeyfobPreTripButtonStatus 3000;
BA_REL_ "GenSigTimeoutTime" BU_SG_REL_ IC SG_ 158 KeyfobPreTripButtonStatus 120;
BA_REL_ "GenSigFirstTimeoutTime" BU_SG_REL_ IC SG_ 158 MirrorSelectRightWideBtn_stat 3000;
BA_REL_ "GenSigTimeoutTime" BU_SG_REL_ IC SG_ 158 MirrorSelectRightWideBtn_stat 120;
BA_REL_ "GenSigFirstTimeoutTime" BU_SG_REL_ SCIM SG_ 158 ParkingLight_Indication 3000;
BA_REL_ "GenSigTimeoutTime" BU_SG_REL_ SCIM SG_ 158 ParkingLight_Indication 120;
BA_REL_ "GenSigFirstTimeoutTime" BU_SG_REL_ SCIM SG_ 158 DrivingLightPlus_Indication 3000;
BA_REL_ "GenSigTimeoutTime" BU_SG_REL_ SCIM SG_ 158 DrivingLightPlus_Indication 120;
BA_REL_ "GenSigFirstTimeoutTime" BU_SG_REL_ IC SG_ 158 BlackPanelMode_ButtonStatus 3000;
BA_REL_ "GenSigTimeoutTime" BU_SG_REL_ IC SG_ 158 BlackPanelMode_ButtonStatus 120;
BA_REL_ "GenSigFirstTimeoutTime" BU_SG_REL_ CCM SG_ 158 ParkBrakeActuationStatus_ISig_5 3000;
BA_REL_ "GenSigTimeoutTime" BU_SG_REL_ CCM SG_ 158 ParkBrakeActuationStatus_ISig_5 120;
BA_REL_ "GenSigFirstTimeoutTime" BU_SG_REL_ IC SG_ 158 LECM_CabClim_FrPwr_BtnStat 3000;
BA_REL_ "GenSigTimeoutTime" BU_SG_REL_ IC SG_ 158 LECM_CabClim_FrPwr_BtnStat 120;
BA_REL_ "GenSigFirstTimeoutTime" BU_SG_REL_ IC SG_ 158 LECM_CabClim_Pwr_BtnStat 3000;
BA_REL_ "GenSigTimeoutTime" BU_SG_REL_ IC SG_ 158 LECM_CabClim_Pwr_BtnStat 120;
BA_REL_ "GenSigFirstTimeoutTime" BU_SG_REL_ IC SG_ 158 BlackPanelMode_ButtonStatus3 3000;
BA_REL_ "GenSigTimeoutTime" BU_SG_REL_ IC SG_ 158 BlackPanelMode_ButtonStatus3 120;
BA_REL_ "GenSigFirstTimeoutTime" BU_SG_REL_ IC SG_ 158 LECM_CabClim_Sync_GuiReq 3000;
BA_REL_ "GenSigTimeoutTime" BU_SG_REL_ IC SG_ 158 LECM_CabClim_Sync_GuiReq 120;
BA_REL_ "GenSigFirstTimeoutTime" BU_SG_REL_ IC SG_ 158 LiftAxle1AutoLiftSelected_ISig_5 3000;
BA_REL_ "GenSigTimeoutTime" BU_SG_REL_ IC SG_ 158 LiftAxle1AutoLiftSelected_ISig_5 120;
BA_REL_ "GenSigFirstTimeoutTime" BU_SG_REL_ IC SG_ 158 LECM_Ent_OnOff_BtnStat 3000;
BA_REL_ "GenSigTimeoutTime" BU_SG_REL_ IC SG_ 158 LECM_Ent_OnOff_BtnStat 120;
BA_REL_ "GenSigFirstTimeoutTime" BU_SG_REL_ IC SG_ 156 LiftAxle2LowerACK_ISig_5 3000;
BA_REL_ "GenSigTimeoutTime" BU_SG_REL_ IC SG_ 156 LiftAxle2LowerACK_ISig_5 120;
BA_REL_ "GenSigFirstTimeoutTime" BU_SG_REL_ IC SG_ 156 LiftAxle2PositionStatus_ISig_5 3000;
BA_REL_ "GenSigTimeoutTime" BU_SG_REL_ IC SG_ 156 LiftAxle2PositionStatus_ISig_5 120;
BA_REL_ "GenSigFirstTimeoutTime" BU_SG_REL_ SCIM SG_ 156 LiftAxle2PositionStatus_ISig_5 3000;
BA_REL_ "GenSigTimeoutTime" BU_SG_REL_ SCIM SG_ 156 LiftAxle2PositionStatus_ISig_5 120;
BA_REL_ "GenSigFirstTimeoutTime" BU_SG_REL_ IC SG_ 156 LiftAxle2LiftFuncSelected_ISig_5 3000;
BA_REL_ "GenSigTimeoutTime" BU_SG_REL_ IC SG_ 156 LiftAxle2LiftFuncSelected_ISig_5 120;
BA_REL_ "GenSigFirstTimeoutTime" BU_SG_REL_ CCM SG_ 156 PassengerDoorAjar_stat 3000;
BA_REL_ "GenSigTimeoutTime" BU_SG_REL_ CCM SG_ 156 PassengerDoorAjar_stat 120;
BA_REL_ "GenSigFirstTimeoutTime" BU_SG_REL_ IC SG_ 156 LevelControlInformation_ISig_5 3000;
BA_REL_ "GenSigTimeoutTime" BU_SG_REL_ IC SG_ 156 LevelControlInformation_ISig_5 120;
BA_REL_ "GenSigFirstTimeoutTime" BU_SG_REL_ SCIM SG_ 156 LevelControlInformation_ISig_5 3000;
BA_REL_ "GenSigTimeoutTime" BU_SG_REL_ SCIM SG_ 156 LevelControlInformation_ISig_5 120;
BA_REL_ "GenSigFirstTimeoutTime" BU_SG_REL_ IC SG_ 156 LiftAxle1LowerACK_ISig_5 3000;
BA_REL_ "GenSigTimeoutTime" BU_SG_REL_ IC SG_ 156 LiftAxle1LowerACK_ISig_5 120;
BA_REL_ "GenSigFirstTimeoutTime" BU_SG_REL_ IC SG_ 156 WiperModeStatus_ISig_5 3000;
BA_REL_ "GenSigTimeoutTime" BU_SG_REL_ IC SG_ 156 WiperModeStatus_ISig_5 120;
BA_REL_ "GenSigFirstTimeoutTime" BU_SG_REL_ CCM SG_ 156 WiperModeStatus_ISig_5 3000;
BA_REL_ "GenSigTimeoutTime" BU_SG_REL_ CCM SG_ 156 WiperModeStatus_ISig_5 120;
BA_REL_ "GenSigFirstTimeoutTime" BU_SG_REL_ CCM SG_ 156 Washing_HMI_rqst 3000;
BA_REL_ "GenSigTimeoutTime" BU_SG_REL_ CCM SG_ 156 Washing_HMI_rqst 120;
BA_REL_ "GenSigFirstTimeoutTime" BU_SG_REL_ IC SG_ 156 LiftAxle2AutoLiftSelected_ISig_5 3000;
BA_REL_ "GenSigTimeoutTime" BU_SG_REL_ IC SG_ 156 LiftAxle2AutoLiftSelected_ISig_5 120;
BA_REL_ "GenSigFirstTimeoutTime" BU_SG_REL_ CCM SG_ 156 ReverseGearEngaged_ISig_5 3000;
BA_REL_ "GenSigTimeoutTime" BU_SG_REL_ CCM SG_ 156 ReverseGearEngaged_ISig_5 120;
BA_REL_ "GenSigFirstTimeoutTime" BU_SG_REL_ SCIM SG_ 156 LiftAxle1PositionStatus_ISig_5 3000;
BA_REL_ "GenSigTimeoutTime" BU_SG_REL_ SCIM SG_ 156 LiftAxle1PositionStatus_ISig_5 120;
BA_REL_ "GenSigFirstTimeoutTime" BU_SG_REL_ IC SG_ 156 LiftAxle1PositionStatus_ISig_5 3000;
BA_REL_ "GenSigTimeoutTime" BU_SG_REL_ IC SG_ 156 LiftAxle1PositionStatus_ISig_5 120;
BA_REL_ "GenSigFirstTimeoutTime" BU_SG_REL_ IC SG_ 156 ACC_Status_ISig_5 3000;
BA_REL_ "GenSigTimeoutTime" BU_SG_REL_ IC SG_ 156 ACC_Status_ISig_5 120;
BA_REL_ "GenSigFirstTimeoutTime" BU_SG_REL_ IC SG_ 156 LECM_CabClim_MaxDef_GuiReq 3000;
BA_REL_ "GenSigTimeoutTime" BU_SG_REL_ IC SG_ 156 LECM_CabClim_MaxDef_GuiReq 120;
BA_REL_ "GenSigFirstTimeoutTime" BU_SG_REL_ IC SG_ 156 RegenerationSwitchStatus 3000;
BA_REL_ "GenSigTimeoutTime" BU_SG_REL_ IC SG_ 156 RegenerationSwitchStatus 120;
BA_REL_ "GenSigFirstTimeoutTime" BU_SG_REL_ CCM SG_ 156 DSWindowPosition 3000;
BA_REL_ "GenSigTimeoutTime" BU_SG_REL_ CCM SG_ 156 DSWindowPosition 120;
BA_REL_ "GenSigFirstTimeoutTime" BU_SG_REL_ IC SG_ 156 GearSplit_Status_ISig_5 3000;
BA_REL_ "GenSigTimeoutTime" BU_SG_REL_ IC SG_ 156 GearSplit_Status_ISig_5 120;
BA_REL_ "GenSigFirstTimeoutTime" BU_SG_REL_ IC SG_ 156 KeyPosition_ISig_5 3000;
BA_REL_ "GenSigTimeoutTime" BU_SG_REL_ IC SG_ 156 KeyPosition_ISig_5 120;
BA_REL_ "GenSigFirstTimeoutTime" BU_SG_REL_ IC SG_ 156 LiftAxle1LiftFuncSelected_ISig_5 3000;
BA_REL_ "GenSigTimeoutTime" BU_SG_REL_ IC SG_ 156 LiftAxle1LiftFuncSelected_ISig_5 120;
BA_REL_ "GenSigFirstTimeoutTime" BU_SG_REL_ SCIM SG_ 156 LiftAxle2UpRequestACK_ISig_5 3000;
BA_REL_ "GenSigTimeoutTime" BU_SG_REL_ SCIM SG_ 156 LiftAxle2UpRequestACK_ISig_5 120;
BA_REL_ "GenSigFirstTimeoutTime" BU_SG_REL_ IC SG_ 156 LiftAxle2UpRequestACK_ISig_5 3000;
BA_REL_ "GenSigTimeoutTime" BU_SG_REL_ IC SG_ 156 LiftAxle2UpRequestACK_ISig_5 120;
BA_REL_ "GenSigFirstTimeoutTime" BU_SG_REL_ IC SG_ 156 PreTrip_ButtonStat3 3000;
BA_REL_ "GenSigTimeoutTime" BU_SG_REL_ IC SG_ 156 PreTrip_ButtonStat3 120;
BA_REL_ "GenSigFirstTimeoutTime" BU_SG_REL_ SCIM SG_ 156 LiftAxle1UpRequestACK_ISig_5 3000;
BA_REL_ "GenSigTimeoutTime" BU_SG_REL_ SCIM SG_ 156 LiftAxle1UpRequestACK_ISig_5 120;
BA_REL_ "GenSigFirstTimeoutTime" BU_SG_REL_ IC SG_ 156 LiftAxle1UpRequestACK_ISig_5 3000;
BA_REL_ "GenSigTimeoutTime" BU_SG_REL_ IC SG_ 156 LiftAxle1UpRequestACK_ISig_5 120;
BA_REL_ "GenSigFirstTimeoutTime" BU_SG_REL_ IC SG_ 154 EngineSpeed_ISig_5 3000;
BA_REL_ "GenSigTimeoutTime" BU_SG_REL_ IC SG_ 154 EngineSpeed_ISig_5 120;
BA_REL_ "GenSigFirstTimeoutTime" BU_SG_REL_ CCM SG_ 154 EngineSpeed_ISig_5 3000;
BA_REL_ "GenSigTimeoutTime" BU_SG_REL_ CCM SG_ 154 EngineSpeed_ISig_5 120;
BA_REL_ "GenSigFirstTimeoutTime" BU_SG_REL_ SCIM SG_ 154 AutonomyAuthorizationDevInd_ISig 3000;
BA_REL_ "GenSigTimeoutTime" BU_SG_REL_ SCIM SG_ 154 AutonomyAuthorizationDevInd_ISig 120;
BA_REL_ "GenSigFirstTimeoutTime" BU_SG_REL_ IC SG_ 154 SteeringWheelAngle_ISig_5 3000;
BA_REL_ "GenSigTimeoutTime" BU_SG_REL_ IC SG_ 154 SteeringWheelAngle_ISig_5 120;
BA_REL_ "GenSigFirstTimeoutTime" BU_SG_REL_ IC SG_ 154 GearLeverPosition_ISig_5 3000;
BA_REL_ "GenSigTimeoutTime" BU_SG_REL_ IC SG_ 154 GearLeverPosition_ISig_5 120;
BA_REL_ "GenSigFirstTimeoutTime" BU_SG_REL_ IC SG_ 154 LateralAcceleration_ISig_5 3000;
BA_REL_ "GenSigTimeoutTime" BU_SG_REL_ IC SG_ 154 LateralAcceleration_ISig_5 120;
BA_REL_ "GenSigFirstTimeoutTime" BU_SG_REL_ IC SG_ 138 AcceleratorPedalLowIdleSwitch_IS 3000;
BA_REL_ "GenSigTimeoutTime" BU_SG_REL_ IC SG_ 138 AcceleratorPedalLowIdleSwitch_IS 100;
BA_REL_ "GenSigFirstTimeoutTime" BU_SG_REL_ SCIM SG_ 138 VehicleMode_ISig_5 3000;
BA_REL_ "GenSigTimeoutTime" BU_SG_REL_ SCIM SG_ 138 VehicleMode_ISig_5 100;
BA_REL_ "GenSigFirstTimeoutTime" BU_SG_REL_ IC SG_ 138 VehicleMode_ISig_5 3000;
BA_REL_ "GenSigTimeoutTime" BU_SG_REL_ IC SG_ 138 VehicleMode_ISig_5 100;
BA_REL_ "GenSigFirstTimeoutTime" BU_SG_REL_ CCM SG_ 138 VehicleMode_ISig_5 3000;
BA_REL_ "GenSigTimeoutTime" BU_SG_REL_ CCM SG_ 138 VehicleMode_ISig_5 100;
BA_REL_ "GenSigFirstTimeoutTime" BU_SG_REL_ IC SG_ 138 AcceleratorPedalPosition1_ISig_5 3000;
BA_REL_ "GenSigTimeoutTime" BU_SG_REL_ IC SG_ 138 AcceleratorPedalPosition1_ISig_5 100;
BA_REL_ "GenSigFirstTimeoutTime" BU_SG_REL_ IC SG_ 138 AcceleratorPedalQuality_ISig_5 3000;
BA_REL_ "GenSigTimeoutTime" BU_SG_REL_ IC SG_ 138 AcceleratorPedalQuality_ISig_5 100;
BA_REL_ "GenSigFirstTimeoutTime" BU_SG_REL_ IC SG_ 895 DriverCrank_rqst 3000;
BA_REL_ "GenSigTimeoutTime" BU_SG_REL_ IC SG_ 895 DriverCrank_rqst 300;
BA_REL_ "GenSigFirstTimeoutTime" BU_SG_REL_ IC SG_ 895 EngineStartControlStatus 3000;
BA_REL_ "GenSigTimeoutTime" BU_SG_REL_ IC SG_ 895 EngineStartControlStatus 300;
BA_REL_ "GenSigFirstTimeoutTime" BU_SG_REL_ IC SG_ 895 ExtStaticTrailerBrake_Stat 3000;
BA_REL_ "GenSigTimeoutTime" BU_SG_REL_ IC SG_ 895 ExtStaticTrailerBrake_Stat 300;
BA_REL_ "GenSigFirstTimeoutTime" BU_SG_REL_ IC SG_ 895 WheelBasedVehicleSpd_Value_ISig_ 3000;
BA_REL_ "GenSigTimeoutTime" BU_SG_REL_ IC SG_ 895 WheelBasedVehicleSpd_Value_ISig_ 300;
BA_REL_ "GenSigFirstTimeoutTime" BU_SG_REL_ IC SG_ 895 WheelBasedVehicleSpd_CRC_ISig_5 3000;
BA_REL_ "GenSigTimeoutTime" BU_SG_REL_ IC SG_ 895 WheelBasedVehicleSpd_CRC_ISig_5 300;
BA_REL_ "GenSigFirstTimeoutTime" BU_SG_REL_ IC SG_ 895 CabTiltLockStatus 3000;
BA_REL_ "GenSigTimeoutTime" BU_SG_REL_ IC SG_ 895 CabTiltLockStatus 300;
BA_REL_ "GenSigFirstTimeoutTime" BU_SG_REL_ IC SG_ 895 WheelBasedVehicleSpd_SqC_ISig_5 3000;
BA_REL_ "GenSigTimeoutTime" BU_SG_REL_ IC SG_ 895 WheelBasedVehicleSpd_SqC_ISig_5 300;
BA_REL_ "GenSigFirstTimeoutTime" BU_SG_REL_ SCIM SG_ 895 CabTiltEnableStatus 3000;
BA_REL_ "GenSigTimeoutTime" BU_SG_REL_ SCIM SG_ 895 CabTiltEnableStatus 300;
BA_REL_ "GenSigFirstTimeoutTime" BU_SG_REL_ VCM SG_ 1104 CabTilt_rqst 3000;
BA_REL_ "GenSigTimeoutTime" BU_SG_REL_ VCM SG_ 1104 CabTilt_rqst 600;
BA_REL_ "GenSigFirstTimeoutTime" BU_SG_REL_ VCM SG_ 1104 PassengersSeatBelt_ISig_5 3000;
BA_REL_ "GenSigTimeoutTime" BU_SG_REL_ VCM SG_ 1104 PassengersSeatBelt_ISig_5 600;
BA_REL_ "GenSigFirstTimeoutTime" BU_SG_REL_ IC SG_ 1104 PassengersSeatBelt_ISig_5 3000;
BA_REL_ "GenSigTimeoutTime" BU_SG_REL_ IC SG_ 1104 PassengersSeatBelt_ISig_5 600;
BA_REL_ "GenSigFirstTimeoutTime" BU_SG_REL_ VCM SG_ 434 RideHeightFunctionRequest_ISig_5 3000;
BA_REL_ "GenSigTimeoutTime" BU_SG_REL_ VCM SG_ 434 RideHeightFunctionRequest_ISig_5 120;
BA_REL_ "GenSigFirstTimeoutTime" BU_SG_REL_ VCM SG_ 434 AdjustFrontBeamInclination 3000;
BA_REL_ "GenSigTimeoutTime" BU_SG_REL_ VCM SG_ 434 AdjustFrontBeamInclination 120;
BA_REL_ "GenSigFirstTimeoutTime" BU_SG_REL_ VCM SG_ 434 ExtraMainbeam_SwitchStatus 3000;
BA_REL_ "GenSigTimeoutTime" BU_SG_REL_ VCM SG_ 434 ExtraMainbeam_SwitchStatus 120;
BA_REL_ "GenSigFirstTimeoutTime" BU_SG_REL_ VCM SG_ 434 StopLevelChangeRequest_ISig_5 3000;
BA_REL_ "GenSigTimeoutTime" BU_SG_REL_ VCM SG_ 434 StopLevelChangeRequest_ISig_5 120;
BA_REL_ "GenSigFirstTimeoutTime" BU_SG_REL_ VCM SG_ 432 StatTrailerBrakeSwitchStatus 3000;
BA_REL_ "GenSigTimeoutTime" BU_SG_REL_ VCM SG_ 432 StatTrailerBrakeSwitchStatus 300;
BA_REL_ "GenSigFirstTimeoutTime" BU_SG_REL_ VCM SG_ 432 DRLOverride_SwitchStatus 3000;
BA_REL_ "GenSigTimeoutTime" BU_SG_REL_ VCM SG_ 432 DRLOverride_SwitchStatus 300;
BA_REL_ "GenSigFirstTimeoutTime" BU_SG_REL_ VCM SG_ 432 DriverSeatBeltSwitch_ISig_5 3000;
BA_REL_ "GenSigTimeoutTime" BU_SG_REL_ VCM SG_ 432 DriverSeatBeltSwitch_ISig_5 300;
BA_REL_ "GenSigFirstTimeoutTime" BU_SG_REL_ IC SG_ 432 DriverSeatBeltSwitch_ISig_5 3000;
BA_REL_ "GenSigTimeoutTime" BU_SG_REL_ IC SG_ 432 DriverSeatBeltSwitch_ISig_5 300;
BA_REL_ "GenSigFirstTimeoutTime" BU_SG_REL_ VCM SG_ 432 DumpSwitchChangeReq_ISig_5 3000;
BA_REL_ "GenSigTimeoutTime" BU_SG_REL_ VCM SG_ 432 DumpSwitchChangeReq_ISig_5 300;
BA_REL_ "GenSigFirstTimeoutTime" BU_SG_REL_ VCM SG_ 432 StaticCornerLightMode 3000;
BA_REL_ "GenSigTimeoutTime" BU_SG_REL_ VCM SG_ 432 StaticCornerLightMode 300;
BA_REL_ "GenSigFirstTimeoutTime" BU_SG_REL_ VCM SG_ 432 FrontLidAjar_Stat 3000;
BA_REL_ "GenSigTimeoutTime" BU_SG_REL_ VCM SG_ 432 FrontLidAjar_Stat 300;
BA_REL_ "GenSigFirstTimeoutTime" BU_SG_REL_ VCM SG_ 432 LoadDistributionRequested_ISig_5 3000;
BA_REL_ "GenSigTimeoutTime" BU_SG_REL_ VCM SG_ 432 LoadDistributionRequested_ISig_5 300;
BA_REL_ "GenSigFirstTimeoutTime" BU_SG_REL_ VCM SG_ 432 LevelingThumbwheel_stat 3000;
BA_REL_ "GenSigTimeoutTime" BU_SG_REL_ VCM SG_ 432 LevelingThumbwheel_stat 300;
VAL_ 689 ParkHeaterTimerReleased_stat 3 "DisableEnable_NotAvailable" 2 "DisableEnable_Error" 1 "DisableEnable_Enable" 0 "DisableEnable_Disable" ;
VAL_ 689 Trail2TPMLostCom 3 "NoYes_NotAvailable" 2 "NoYes_Error" 1 "NoYes_Yes" 0 "NoYes_No" ;
VAL_ 689 BrakeInterlockStatus_ISig_5 3 "OffOn_NotAvailable" 2 "OffOn_Error" 1 "OffOn_On" 0 "OffOn_Off" ;
VAL_ 689 AutoWheelBrakesDownshiftSugges_I 3 "DownshiftSuggest_NotAvailable" 2 "DownshiftSuggest_Error" 1 "DownshiftSuggest_SuggestDownshift" 0 "DownshiftSuggest_NoSuggestion" ;
VAL_ 689 RearAxle2DiffLock_stat_ISig_5 3 "OffOn_NotAvailable" 2 "OffOn_Error" 1 "OffOn_On" 0 "OffOn_Off" ;
VAL_ 689 CentralRearDiffLock_stat_ISig_5 3 "DisengageEngage_NotAvailable" 2 "DisengageEngage_Error" 1 "DisengageEngage_Engage" 0 "DisengageEngage_Disengage" ;
VAL_ 689 TransmissionBrakeMode_ISig_5 3 "InactiveActive_NotAvailable" 2 "InactiveActive_Error" 1 "InactiveActive_Active" 0 "InactiveActive_Inactive" ;
VAL_ 689 PS_HeadLightAdjustment 3 "InactiveActiveSpare_NotAvailable" 2 "InactiveActiveSpare_Spare" 1 "InactiveActiveSpare_Active" 0 "InactiveActiveSpare_Inactive" ;
VAL_ 689 ReducedLoadMode_stat_ISig_5 3 "ReducedLoadMode_stat_NotAvailable" 2 "ReducedLoadMode_stat_Error" 1 "ReducedLoadMode_stat_ReducedLoadMode" 0 "ReducedLoadMode_stat_NormalMode" ;
VAL_ 689 FrontWheelDifflockRequest_ISig_5 3 "DisengageEngage_NotAvailable" 2 "DisengageEngage_Error" 1 "DisengageEngage_Engage" 0 "DisengageEngage_Disengage" ;
VAL_ 689 ABSEBSAmberWarningSignal_ISig_5 3 "OffOn_NotAvailable" 2 "OffOn_Error" 1 "OffOn_On" 0 "OffOn_Off" ;
VAL_ 689 DifferentialLockStateFrAxle1_ISi 3 "DisengageEngage_NotAvailable" 2 "DisengageEngage_Error" 1 "DisengageEngage_Engage" 0 "DisengageEngage_Disengage" ;
VAL_ 689 Trail1TPMLostCom 3 "NoYes_NotAvailable" 2 "NoYes_Error" 1 "NoYes_Yes" 0 "NoYes_No" ;
VAL_ 689 TrailerInflationPossible_stat_IS 3 "TrailerInflationPossible_stat_NotAvailable" 2 "TrailerInflationPossible_stat_Error" 1 "TrailerInflationPossible_stat_PossiblePressureOK" 0 "TrailerInflationPossible_stat_NotPossibleLowerPressure" ;
VAL_ 689 DrivelineRetarderStat_ISig_5 3 "DrivelineRetarderStat_NotAvailable" 2 "DrivelineRetarderStat_Error" 1 "DrivelineRetarderStat_RetarderCapacityDerated" 0 "DrivelineRetarderStat_RetarderCapacityNotDerated" ;
VAL_ 689 PS_FogLightRear 3 "InactiveActiveSpare_NotAvailable" 2 "InactiveActiveSpare_Spare" 1 "InactiveActiveSpare_Active" 0 "InactiveActiveSpare_Inactive" ;
VAL_ 689 PS_MainBeam 3 "PSOffOn_NotAvailable" 2 "PSOffOn_Spare" 1 "PSOffOn_On" 0 "PSOffOn_Off" ;
VAL_ 689 DeCompActive_ISig_5 3 "NotActiveActive_NotAvailable" 2 "NotActiveActive_Error" 1 "NotActiveActive_Active" 0 "NotActiveActive_NotActive" ;
VAL_ 689 ECSManStandbyStatus_ISig_5 3 "InactiveActive_NotAvailable" 2 "InactiveActive_Error" 1 "InactiveActive_Active" 0 "InactiveActive_Inactive" ;
VAL_ 689 AutoPBRelease_stat_ISig_5 3 "AutoPBRelease_stat_NotAvailable" 2 "AutoPBRelease_stat_Error" 1 "AutoPBRelease_stat_FunctionInhibited" 0 "AutoPBRelease_stat_FunctionAvailable" ;
VAL_ 689 Trail4TPMLostCom 3 "NoYes_NotAvailable" 2 "NoYes_Error" 1 "NoYes_Yes" 0 "NoYes_No" ;
VAL_ 689 EBSRedWarningSignal_ISig_5 3 "OffOn_NotAvailable" 2 "OffOn_Error" 1 "OffOn_On" 0 "OffOn_Off" ;
VAL_ 689 DifferentialLockStateCentral_ISi 3 "DisengageEngage_NotAvailable" 2 "DisengageEngage_Error" 1 "DisengageEngage_Engage" 0 "DisengageEngage_Disengage" ;
VAL_ 689 RearAxle3DiffLock_stat_ISig_5 3 "OffOn_NotAvailable" 2 "OffOn_Error" 1 "OffOn_On" 0 "OffOn_Off" ;
VAL_ 689 AntiLockBrakingActive_ISig_5 3 "AntiLockBrakingActive_NotAvailable" 2 "AntiLockBrakingActive_Reserved" 1 "AntiLockBrakingActive_ABSActive" 0 "AntiLockBrakingActive_ABSPassiveButInstalled" ;
VAL_ 689 RearAxle1DiffLock_stat_ISig_5 3 "OffOn_NotAvailable" 2 "OffOn_Error" 1 "OffOn_On" 0 "OffOn_Off" ;
VAL_ 689 Trail5TPMLostCom 3 "NoYes_NotAvailable" 2 "NoYes_Error" 1 "NoYes_Yes" 0 "NoYes_No" ;
VAL_ 689 PS_PositionLight 3 "OffOnSpare_NotAvailable" 2 "OffOnSpare_Spare" 1 "OffOnSpare_On" 0 "OffOnSpare_Off" ;
VAL_ 689 BatteryCapacity_Ack_ISig_5 3 "NokOk_NotAvailable" 2 "NokOk_Error" 1 "NokOk_OK" 0 "NokOk_NOK" ;
VAL_ 689 Trail3TPMLostCom 3 "NoYes_NotAvailable" 2 "NoYes_Error" 1 "NoYes_Yes" 0 "NoYes_No" ;
VAL_ 689 ParkBrakeWorkshopMode_ISig_5 3 "ParkBrakeWorkshopMode_NotAvailable" 2 "ParkBrakeWorkshopMode_Error" 1 "ParkBrakeWorkshopMode_WorkshopMode" 0 "ParkBrakeWorkshopMode_NormalMode" ;
VAL_ 689 LowTempClutchInfo_ISig_5 3 "Warning_NotAvailable" 2 "Warning_Error" 1 "Warning_Warning" 0 "Warning_NoWarning" ;
VAL_ 688 TrailerWithoutABS_ISig_5 3 "TrailerWithoutABS_NotAvailableOrNotInstalled" 2 "TrailerWithoutABS_ErrorIndicator" 1 "TrailerWithoutABS_YesTrailerWithoutABS" 0 "TrailerWithoutABS_NoNoTrailerPresentOraTrailerWithABS" ;
VAL_ 688 APMSafetyWarning_RedRqst_ISig_5 3 "NotRequested_NotAvailable" 2 "NotRequested_Error" 1 "NotRequested_Requested" 0 "NotRequested_NotRequested" ;
VAL_ 688 EcoRollEnabledStatus_ISig_5 3 "DisableEnable_NotAvailable" 2 "DisableEnable_Error" 1 "DisableEnable_Enable" 0 "DisableEnable_Disable" ;
VAL_ 688 PBStatus_Actuation_ISig_5 7 "PBActuationStatus_NotAvailable" 6 "PBActuationStatus_Error" 5 "PBActuationStatus_Spare3" 4 "PBActuationStatus_Spare2" 3 "PBActuationStatus_Spare1" 2 "PBActuationStatus_Parked" 1 "PBActuationStatus_Intermediate" 0 "PBActuationStatus_Released" ;
VAL_ 688 GearShiftingRec_Steps_ISig_5 7 "GearShiftingSteps_NotAvailable" 6 "GearShiftingSteps_Error" 5 "GearShiftingSteps_6step" 4 "GearShiftingSteps_5step" 3 "GearShiftingSteps_4step" 2 "GearShiftingSteps_3step" 1 "GearShiftingSteps_2step" 0 "GearShiftingSteps_1step" ;
VAL_ 688 PBStatus_IntegrityLvl_ISig_5 3 "PBIntegrityLvl_HighIntegrity" 2 "PBIntegrityLvl_Spare" 1 "PBIntegrityLvl_LowIntegrity" 0 "PBIntegrityLvl_Downgraded" ;
VAL_ 688 GearShiftingRec_Direction_ISig_5 7 "GearShiftingDirection_NotAvailable" 6 "GearShiftingDirection_Error" 5 "GearShiftingDirection_Spare3" 4 "GearShiftingDirection_Spare2" 3 "GearShiftingDirection_Spare1" 2 "GearShiftingDirection_Down" 1 "GearShiftingDirection_Up" 0 "GearShiftingDirection_NoShiftRecommendation" ;
VAL_ 688 RearPropulsionStat_Rear2Axle_ISi 15 "AxlePropulsionStatus_NotAvailable" 14 "AxlePropulsionStatus_Error" 13 "AxlePropulsionStatus_Spare6" 12 "AxlePropulsionStatus_Spare5" 11 "AxlePropulsionStatus_Spare4" 10 "AxlePropulsionStatus_Spare3" 9 "AxlePropulsionStatus_Spare2" 8 "AxlePropulsionStatus_Spare1" 7 "AxlePropulsionStatus_LoweredInterAxleStatusUnknown" 6 "AxlePropulsionStatus_LiftedInterAxleStatusUnknown" 5 "AxlePropulsionStatus_PositionUnknownDriven" 4 "AxlePropulsionStatus_PositionUnknownNonDriven" 3 "AxlePropulsionStatus_LoweredDifferentialLocked" 2 "AxlePropulsionStatus_LoweredDriven" 1 "AxlePropulsionStatus_LoweredNonDriven" 0 "AxlePropulsionStatus_LiftedNonDriven" ;
VAL_ 688 RearPropulsionStat_Rear1Axle_ISi 15 "AxlePropulsionStatus_NotAvailable" 14 "AxlePropulsionStatus_Error" 13 "AxlePropulsionStatus_Spare6" 12 "AxlePropulsionStatus_Spare5" 11 "AxlePropulsionStatus_Spare4" 10 "AxlePropulsionStatus_Spare3" 9 "AxlePropulsionStatus_Spare2" 8 "AxlePropulsionStatus_Spare1" 7 "AxlePropulsionStatus_LoweredInterAxleStatusUnknown" 6 "AxlePropulsionStatus_LiftedInterAxleStatusUnknown" 5 "AxlePropulsionStatus_PositionUnknownDriven" 4 "AxlePropulsionStatus_PositionUnknownNonDriven" 3 "AxlePropulsionStatus_LoweredDifferentialLocked" 2 "AxlePropulsionStatus_LoweredDriven" 1 "AxlePropulsionStatus_LoweredNonDriven" 0 "AxlePropulsionStatus_LiftedNonDriven" ;
VAL_ 688 RearPropulsionStat_Rear3Axle_ISi 15 "AxlePropulsionStatus_NotAvailable" 14 "AxlePropulsionStatus_Error" 13 "AxlePropulsionStatus_Spare6" 12 "AxlePropulsionStatus_Spare5" 11 "AxlePropulsionStatus_Spare4" 10 "AxlePropulsionStatus_Spare3" 9 "AxlePropulsionStatus_Spare2" 8 "AxlePropulsionStatus_Spare1" 7 "AxlePropulsionStatus_LoweredInterAxleStatusUnknown" 6 "AxlePropulsionStatus_LiftedInterAxleStatusUnknown" 5 "AxlePropulsionStatus_PositionUnknownDriven" 4 "AxlePropulsionStatus_PositionUnknownNonDriven" 3 "AxlePropulsionStatus_LoweredDifferentialLocked" 2 "AxlePropulsionStatus_LoweredDriven" 1 "AxlePropulsionStatus_LoweredNonDriven" 0 "AxlePropulsionStatus_LiftedNonDriven" ;
VAL_ 688 APMSafetyWarning_YellowRqst_ISig 3 "NoRequestRequest_NotAvailable" 2 "NoRequestRequest_Error" 1 "NoRequestRequest_Request" 0 "NoRequestRequest_NoRequest" ;
VAL_ 394 FPBRMMIStat_FPBRStatusInd_ISig_5 3 "FPBRStatusInd_NotAvailable" 2 "FPBRStatusInd_Changing" 1 "FPBRStatusInd_On" 0 "FPBRStatusInd_Off" ;
VAL_ 394 FPBRMMIStat_FPBRChangeAck_ISig_5 3 "Ack2Bit_NotAvailable" 2 "Ack2Bit_Error" 1 "Ack2Bit_ChangeAcknowledged" 0 "Ack2Bit_NoAction" ;
VAL_ 394 RssInhibStartEngine_rqst 3 "OffOn_NotAvailable" 2 "OffOn_Error" 1 "OffOn_On" 0 "OffOn_Off" ;
VAL_ 394 MainBeam_rqst 7 "MainBeam_rqst_NotAvailable" 6 "MainBeam_rqst_Error" 5 "MainBeam_rqst_SpareValue3" 4 "MainBeam_rqst_SpareValue2" 3 "MainBeam_rqst_SpareValue1" 2 "MainBeam_rqst_FlashToPassRequest" 1 "MainBeam_rqst_MainBeamRequest" 0 "MainBeam_rqst_DippedBeamRequest" ;
VAL_ 394 DumpSwitchChangeAck_ISig_5 3 "DumpSwitchChangeAck_NotAvailable" 2 "DumpSwitchChangeAck_Error" 1 "DumpSwitchChangeAck_ChangeAcknowledged" 0 "DumpSwitchChangeAck_NoAction" ;
VAL_ 393 EngineActiveStatus_ISig_5 15 "EngineActiveStatus_NotAvailable" 14 "EngineActiveStatus_Error" 13 "EngineActiveStatus_Spare_10" 12 "EngineActiveStatus_Spare_09" 11 "EngineActiveStatus_Spare_08" 10 "EngineActiveStatus_Spare_07" 9 "EngineActiveStatus_Spare_06" 8 "EngineActiveStatus_Spare_05" 7 "EngineActiveStatus_Spare_04" 6 "EngineActiveStatus_Spare_03" 5 "EngineActiveStatus_Spare_02" 4 "EngineActiveStatus_Spare_01" 3 "EngineActiveStatus_EngineStandby" 2 "EngineActiveStatus_ElectricPropulsionSystemRunning" 1 "EngineActiveStatus_InternalCombustionEngineRunning" 0 "EngineActiveStatus_DrivelineNotActive" ;
VAL_ 393 BackLightDimming_Status3 31 "Thumbwheel_stat_NotAvaliable" 30 "Thumbwheel_stat_Error" 29 "Thumbwheel_stat_Spare_12" 28 "Thumbwheel_stat_Spare_11" 27 "Thumbwheel_stat_Spare_10" 26 "Thumbwheel_stat_Spare_09" 25 "Thumbwheel_stat_Spare_08" 24 "Thumbwheel_stat_Spare_07" 23 "Thumbwheel_stat_Spare_06" 22 "Thumbwheel_stat_Spare_05" 21 "Thumbwheel_stat_Spare_04" 20 "Thumbwheel_stat_Spare_03" 19 "Thumbwheel_stat_Spare_02" 18 "Thumbwheel_stat_Spare_01" 17 "Thumbwheel_stat_Spare" 16 "Thumbwheel_stat_ThumbWheelPos16" 15 "Thumbwheel_stat_ThumbWheelPos15" 14 "Thumbwheel_stat_ThumbWheelPos14" 13 "Thumbwheel_stat_ThumbWheelPos13" 12 "Thumbwheel_stat_ThumbWheelPos12" 11 "Thumbwheel_stat_ThumbWheelPos11" 10 "Thumbwheel_stat_ThumbWheelPos10" 9 "Thumbwheel_stat_ThumbWheelPos9" 8 "Thumbwheel_stat_ThumbWheelPos8" 7 "Thumbwheel_stat_ThumbWheelPos7" 6 "Thumbwheel_stat_ThumbWheelPos6" 5 "Thumbwheel_stat_ThumbWheelPos5" 4 "Thumbwheel_stat_ThumbWheelPos4" 3 "Thumbwheel_stat_ThumbWheelPos3" 2 "Thumbwheel_stat_ThumbWheelPos2" 1 "Thumbwheel_stat_ThumbWheelPos1" 0 "Thumbwheel_stat_ThumbWheelPos0" ;
VAL_ 393 BrakePedalTestState_ISig_5 15 "BrakePedalTestState_NotAvailable" 14 "BrakePedalTestState_Error" 13 "BrakePedalTestState_Spare_06" 12 "BrakePedalTestState_Spare_05" 11 "BrakePedalTestState_Spare_04" 10 "BrakePedalTestState_Spare_03" 9 "BrakePedalTestState_Spare_02" 8 "BrakePedalTestState_Spare_01" 7 "BrakePedalTestState_Spare" 6 "BrakePedalTestState_TestInterrIncorrOpByDrAtLeastOneActFault" 5 "BrakePedalTestState_TestWasCorrectlyOpByDrAtLeastOneActFault" 4 "BrakePedalTestState_TestWasCorrectlyOperatedByDrFaultDeleted" 3 "BrakePedalTestState_BrakePedalReleaseIsNeeded" 2 "BrakePedalTestState_FullBrakePedalActuationIsNeeded" 1 "BrakePedalTestState_TestIsNeededKeepBrakePedalReleased" 0 "BrakePedalTestState_BrakePedalTestIsNotNeeded" ;
VAL_ 393 ParkBrakeApplicationMode2_ISig_5 15 "ParkBrakeApplicationMode2_NotAvailable" 14 "ParkBrakeApplicationMode2_Error" 13 "ParkBrakeApplicationMode2_Reserved5" 12 "ParkBrakeApplicationMode2_Reserved4" 11 "ParkBrakeApplicationMode2_Reserved3" 10 "ParkBrakeApplicationMode2_Reserved2" 9 "ParkBrakeApplicationMode2_RedundantExternalDemand" 8 "ParkBrakeApplicationMode2_AutomaticcallyDoorOpen" 7 "ParkBrakeApplicationMode2_ParkBrakeBlending" 6 "ParkBrakeApplicationMode2_AutomaticallyHillHolder" 5 "ParkBrakeApplicationMode2_AutomaticInBackup" 4 "ParkBrakeApplicationMode2_MainExternalDemand" 3 "ParkBrakeApplicationMode2_AutomaticallyKeyOff" 2 "ParkBrakeApplicationMode2_ManuallyAtStandstill" 1 "ParkBrakeApplicationMode2_ManuallyInDriving" 0 "ParkBrakeApplicationMode2_Idle" ;
VAL_ 393 RampLevelStatus_ISig_5 15 "RampLevelStatus_NotAvaiable" 14 "RampLevelStatus_ErrorIndicator" 13 "RampLevelStatus_NotDefined_05" 12 "RampLevelStatus_NotDefined_04" 11 "RampLevelStatus_NotDefined_03" 10 "RampLevelStatus_NotDefined_02" 9 "RampLevelStatus_NotDefined_01" 8 "RampLevelStatus_NotDefined" 7 "RampLevelStatus_RampLevelM7" 6 "RampLevelStatus_RampLevelM6" 5 "RampLevelStatus_RampLevelM5" 4 "RampLevelStatus_RampLevelM4" 3 "RampLevelStatus_RampLevelM3" 2 "RampLevelStatus_RampLevelM2" 1 "RampLevelStatus_RampLevelM1" 0 "RampLevelStatus_Inactive" ;
VAL_ 393 ParkBrakeReleaseMode2_ISig_5 15 "ParkBrakeReleaseMode2_NotAvailable" 14 "ParkBrakeReleaseMode2_Error" 13 "ParkBrakeReleaseMode2_Reserved7" 12 "ParkBrakeReleaseMode2_Reserved6" 11 "ParkBrakeReleaseMode2_Reserved5" 10 "ParkBrakeReleaseMode2_Reserved4" 9 "ParkBrakeReleaseMode2_Reserved3" 8 "ParkBrakeReleaseMode2_VoluntarilyAtLowVehicleMode" 7 "ParkBrakeReleaseMode2_RedundantExternalDemand" 6 "ParkBrakeReleaseMode2_AutomaticallyinHillHolder" 5 "ParkBrakeReleaseMode2_AutomaticInBackup" 4 "ParkBrakeReleaseMode2_MainExternalDemand" 3 "ParkBrakeReleaseMode2_AutomaticallyAccelPedal" 2 "ParkBrakeReleaseMode2_ManuallyAtStandstill" 1 "ParkBrakeReleaseMode2_ManuallyInDriving" 0 "ParkBrakeReleaseMode2_Idle" ;
VAL_ 393 BackLightDimming_Status 31 "Thumbwheel_stat_NotAvaliable" 30 "Thumbwheel_stat_Error" 29 "Thumbwheel_stat_Spare_12" 28 "Thumbwheel_stat_Spare_11" 27 "Thumbwheel_stat_Spare_10" 26 "Thumbwheel_stat_Spare_09" 25 "Thumbwheel_stat_Spare_08" 24 "Thumbwheel_stat_Spare_07" 23 "Thumbwheel_stat_Spare_06" 22 "Thumbwheel_stat_Spare_05" 21 "Thumbwheel_stat_Spare_04" 20 "Thumbwheel_stat_Spare_03" 19 "Thumbwheel_stat_Spare_02" 18 "Thumbwheel_stat_Spare_01" 17 "Thumbwheel_stat_Spare" 16 "Thumbwheel_stat_ThumbWheelPos16" 15 "Thumbwheel_stat_ThumbWheelPos15" 14 "Thumbwheel_stat_ThumbWheelPos14" 13 "Thumbwheel_stat_ThumbWheelPos13" 12 "Thumbwheel_stat_ThumbWheelPos12" 11 "Thumbwheel_stat_ThumbWheelPos11" 10 "Thumbwheel_stat_ThumbWheelPos10" 9 "Thumbwheel_stat_ThumbWheelPos9" 8 "Thumbwheel_stat_ThumbWheelPos8" 7 "Thumbwheel_stat_ThumbWheelPos7" 6 "Thumbwheel_stat_ThumbWheelPos6" 5 "Thumbwheel_stat_ThumbWheelPos5" 4 "Thumbwheel_stat_ThumbWheelPos4" 3 "Thumbwheel_stat_ThumbWheelPos3" 2 "Thumbwheel_stat_ThumbWheelPos2" 1 "Thumbwheel_stat_ThumbWheelPos1" 0 "Thumbwheel_stat_ThumbWheelPos0" ;
VAL_ 393 HeightControlMode_ISig_5 15 "HeightControlMode_NotAvailable" 14 "HeightControlMode_ErrorIndicator" 13 "HeightControlMode_DumpFunction" 12 "HeightControlMode_FactorySupportMode" 11 "HeightControlMode_Calibration" 10 "HeightControlMode_Prohibit" 9 "HeightControlMode_FunctionTest" 8 "HeightControlMode_Stop" 7 "HeightControlMode_LimpHome" 6 "HeightControlMode_FerryFunction" 5 "HeightControlMode_KneelingHeight" 4 "HeightControlMode_DriveHeight" 3 "HeightControlMode_DockingRampHeight" 2 "HeightControlMode_HeightAdjustment" 1 "HeightControlMode_StartUpHeight" 0 "HeightControlMode_TakeNoAction" ;
VAL_ 393 FifthWheelLockingInformation_ISi 15 "FifthWheelLockingInformation_NotAvailable" 14 "FifthWheelLockingInformation_Error" 13 "FifthWheelLockingInformation_Spare_07" 12 "FifthWheelLockingInformation_Spare_06" 11 "FifthWheelLockingInformation_Spare_05" 10 "FifthWheelLockingInformation_Spare_04" 9 "FifthWheelLockingInformation_Spare_03" 8 "FifthWheelLockingInformation_Spare_02" 7 "FifthWheelLockingInformation_Spare_01" 6 "FifthWheelLockingInformation_Spare" 5 "FifthWheelLockingInformation_5thWheelSystemError" 4 "FifthWheelLockingInformation_TrailerNotCorrectlyCoupled" 3 "FifthWheelLockingInformation_HandleLockedTrailerRightConnected" 2 "FifthWheelLockingInformation_KingPinEndPosTrailerPlateInContact" 1 "FifthWheelLockingInformation_TrailerPlateInContactW_semitrailer" 0 "FifthWheelLockingInformation_TractorAlone" ;
VAL_ 392 FirstAxleLowerPrioSelected_ISig_ 7 "FirstAxleLowerPrio_NotAvailable" 6 "FirstAxleLowerPrio_Error" 5 "FirstAxleLowerPrio_Reserved_03" 4 "FirstAxleLowerPrio_Reserved_02" 3 "FirstAxleLowerPrio_Reserved_01" 2 "FirstAxleLowerPrio_Reserved" 1 "FirstAxleLowerPrio_LowerPusher" 0 "FirstAxleLowerPrio_LowerTag" ;
VAL_ 392 ESCState_ISig_5 7 "ESCState_NotAvailable" 6 "ESCState_Error" 5 "ESCState_Spare03" 4 "ESCState_Spare02" 3 "ESCState_Spare01" 2 "ESCState_Reduced" 1 "ESCState_On" 0 "ESCState_Off" ;
VAL_ 392 KneelingInformation_ISig_5 15 "KneelingInformation_NotAvailable" 14 "KneelingInformation_ErrorIndicator" 13 "KneelingInformation_NotDefined_08" 12 "KneelingInformation_NotDefined_07" 11 "KneelingInformation_NotDefined_06" 10 "KneelingInformation_NotDefined_05" 9 "KneelingInformation_NotDefined_04" 8 "KneelingInformation_NotDefined_03" 7 "KneelingInformation_NotDefined_02" 6 "KneelingInformation_NotDefined_01" 5 "KneelingInformation_NotDefined" 4 "KneelingInformation_KneelingAborted" 3 "KneelingInformation_LiftingActiveVehicleIsLiftedDueToRcvrReq" 2 "KneelingInformation_KneelLevelReachedVehicleIsAtFixeKneelLvl" 1 "KneelingInformation_LoweringActiveTheVehIsLoweredDueToKneelReq" 0 "KneelingInformation_NotActiveTheKneelingFunctionIsNotActive" ;
VAL_ 392 TrailerTest_stat_ISig_5 7 "TrailerTest_stat_NotAvailable" 6 "TrailerTest_stat_Error" 5 "TrailerTest_stat_InProgress_TrailerNotConnected" 4 "TrailerTest_stat_NotPossibleLowVoltgeOrLowPressure" 3 "TrailerTest_stat_TrailerTestIncentive" 2 "TrailerTest_stat_NotPossibleServiceBrakeApplied" 1 "TrailerTest_stat_InProgress" 0 "TrailerTest_stat_IdleNoTrailerTest" ;
VAL_ 392 ThreePosDifflockSwitch_stat 7 "A3PosSwitchStatus_NotAvailable" 6 "A3PosSwitchStatus_Error" 5 "A3PosSwitchStatus_Spare_02" 4 "A3PosSwitchStatus_Spare_01" 3 "A3PosSwitchStatus_Spare" 2 "A3PosSwitchStatus_Upper" 1 "A3PosSwitchStatus_Lower" 0 "A3PosSwitchStatus_Middle" ;
VAL_ 392 HillHolderMode_ISig_5 7 "HillHolderMode_NotAvailable" 6 "HillHolderMode_Reserved" 5 "HillHolderMode_Spare2" 4 "HillHolderMode_Spare1" 3 "HillHolderMode_OnHold_PressureApplied" 2 "HillHolderMode_Active_WillChangeToInactiveSoon" 1 "HillHolderMode_Active" 0 "HillHolderMode_Inactive" ;
VAL_ 392 RampHeightOutsideTargetRange_ISi 7 "HeightOutsideTargetRange_NotAvailable" 6 "HeightOutsideTargetRange_Error" 5 "HeightOutsideTargetRange_NotDefined_02" 4 "HeightOutsideTargetRange_NotDefined_01" 3 "HeightOutsideTargetRange_NotDefined" 2 "HeightOutsideTargetRange_ToHigh" 1 "HeightOutsideTargetRange_ToLow" 0 "HeightOutsideTargetRange_Inactive" ;
VAL_ 392 ShortStopHeater_status_ISig_5 7 "ShortStopHeaterStatus_NotAvailable" 6 "ShortStopHeaterStatus_Error" 5 "ShortStopHeaterStatus_Spare3" 4 "ShortStopHeaterStatus_Spare2" 3 "ShortStopHeaterStatus_Spare1" 2 "ShortStopHeaterStatus_ActivatedAndPumpNotEngaged" 1 "ShortStopHeaterStatus_ActivatedAndPumpEngaged" 0 "ShortStopHeaterStatus_NotActivated" ;
VAL_ 392 LuggageAjar_stat 7 "DoorAjar_stat_NotAvailable" 6 "DoorAjar_stat_Error" 2 "DoorAjar_stat_DoorOpen" 1 "DoorAjar_stat_DoorClosed" 0 "DoorAjar_stat_Idle" ;
VAL_ 392 LoadDistributionRequestedACK_ISi 7 "LoadDistributionRequestedACK_NotAvailable" 6 "LoadDistributionRequestedACK_Error" 5 "LoadDistributionRequestedACK_SystemDeniedVersatile" 4 "LoadDistributionRequestedACK_Reserved2" 3 "LoadDistributionRequestedACK_DeniedDueToDisengagedDifflock" 2 "LoadDistributionRequestedACK_LoadShiftDeniedFALIMOverload" 1 "LoadDistributionRequestedACK_ChangeAcknowledged" 0 "LoadDistributionRequestedACK_NoAction" ;
VAL_ 392 StretchBrake_Stat_ISig_5 7 "StretchBrake_Stat_NotAvailable" 6 "StretchBrake_Stat_Error" 5 "StretchBrake_Stat_Spare_02" 4 "StretchBrake_Stat_Spare_01" 3 "StretchBrake_Stat_Spare" 2 "StretchBrake_Stat_Active" 1 "StretchBrake_Stat_Enabled" 0 "StretchBrake_Stat_Disabled" ;
VAL_ 392 MirrorHeatingMode 7 "MirrorHeat_NotAvailable" 6 "MirrorHeat_ErrorIndicator" 5 "MirrorHeat_SpareValue_02" 4 "MirrorHeat_SpareValue_01" 3 "MirrorHeat_SpareValue" 2 "MirrorHeat_ONExtendedMode" 1 "MirrorHeat_ONNormalMode" 0 "MirrorHeat_OFF" ;
VAL_ 392 ESCStatus_ISig_5 7 "ESCStatus_NotAvailable" 6 "ESCStatus_Error" 5 "ESCStatus_PartlyMalfunctioning" 4 "ESCStatus_FullyMalfunctioning" 3 "ESCStatus_ESCOn" 2 "ESCStatus_Spare3" 1 "ESCStatus_ESCReduced" 0 "ESCStatus_ESCOff" ;
VAL_ 392 DriverRetarderRequest_ISig_5 7 "DriverRetarderRequest_NotAvailable" 6 "DriverRetarderRequest_Error" 5 "DriverRetarderRequest_Level5" 4 "DriverRetarderRequest_Level4" 3 "DriverRetarderRequest_Level3" 2 "DriverRetarderRequest_Level2" 1 "DriverRetarderRequest_Level1" 0 "DriverRetarderRequest_NoRequest" ;
VAL_ 392 PBReleaseAcceptance_stat_ISig_5 7 "PBReleaseAcceptance_stat_NotAvailable" 6 "PBReleaseAcceptance_stat_Error" 5 "PBReleaseAcceptance_stat_Spare_03" 4 "PBReleaseAcceptance_stat_AccelPedalOrHCURequested" 3 "PBReleaseAcceptance_stat_ReleaseRequestAccepted" 2 "PBReleaseAcceptance_stat_BrakeOrAccelPedalRequested" 1 "PBReleaseAcceptance_stat_BrakePedalRequested" 0 "PBReleaseAcceptance_stat_NoRequestDetectedOrRequestAborted" ;
VAL_ 392 PSWindowPosition 7 "WindowPosition_NotAvailable" 6 "WindowPosition_Error" 5 "WindowPosition_Spare" 4 "WindowPosition_UnknownPosition" 3 "WindowPosition_Open_70_100Percent" 2 "WindowPosition_Open_30_70Percent" 1 "WindowPosition_Open_0_30Percent" 0 "WindowPosition_Closed" ;
VAL_ 392 RideHeightOutsideTargetRange_ISi 7 "HeightOutsideTargetRange_NotAvailable" 6 "HeightOutsideTargetRange_Error" 5 "HeightOutsideTargetRange_NotDefined_02" 4 "HeightOutsideTargetRange_NotDefined_01" 3 "HeightOutsideTargetRange_NotDefined" 2 "HeightOutsideTargetRange_ToHigh" 1 "HeightOutsideTargetRange_ToLow" 0 "HeightOutsideTargetRange_Inactive" ;
VAL_ 392 DriveLevelPosUserInteraction_ISi 7 "DriveLevelPosUserInteraction_NotAvailable" 6 "DriveLevelPosUserInteraction_Error" 5 "DriveLevelPosUserInteraction_Spare3" 4 "DriveLevelPosUserInteraction_Spare2" 3 "DriveLevelPosUserInteraction_Spare1" 2 "DriveLevelPosUserInteraction_WarningDriveLevelPosNotSelected" 1 "DriveLevelPosUserInteraction_DriveLevelPositionNotSelected" 0 "DriveLevelPosUserInteraction_DriveLevelPositionSelected" ;
VAL_ 392 HillStartAidStatus_ISig_5 7 "HillStartAidStatus_NotAvailable" 6 "HillStartAidStatus_Error" 5 "HillStartAidStatus_NotDefined2" 4 "HillStartAidStatus_ActiveWithWarningHigh" 3 "HillStartAidStatus_ActiveWithWarningLow" 2 "HillStartAidStatus_ActiveButWillChangeToInactiveInAShortTime" 1 "HillStartAidStatus_Active" 0 "HillStartAidStatus_Inactive" ;
VAL_ 391 AcceleratorPedalTestStatus 7 "AcceleratorPedalTestStatus_NotAvailable" 6 "AcceleratorPedalTestStatus_Error" 5 "AcceleratorPedalTestStatus_TestFailed" 4 "AcceleratorPedalTestStatus_TestFinished" 3 "AcceleratorPedalTestStatus_Step3" 2 "AcceleratorPedalTestStatus_Step2" 1 "AcceleratorPedalTestStatus_Step1" 0 "AcceleratorPedalTestStatus_Inactive" ;
VAL_ 391 ESCDriverReq_ISig_5 7 "ESCDriverReq_NotAvailable" 6 "ESCDriverReq_Error" 5 "ESCDriverReq_Spare02" 4 "ESCDriverReq_Spare01" 3 "ESCDriverReq_ESCOn" 2 "ESCDriverReq_ESCReduced" 1 "ESCDriverReq_ESCOff" 0 "ESCDriverReq_NoRequest" ;
VAL_ 391 UnevenLoadWarning_ISig_5 3 "Warning_NotAvailable" 2 "Warning_Error" 1 "Warning_Warning" 0 "Warning_NoWarning" ;
VAL_ 391 RrInterAxlDiffLockActvnFuncReq_I 3 "DisengagedEngaged_NotAvailable" 2 "DisengagedEngaged_Error" 1 "DisengagedEngaged_Engaged" 0 "DisengagedEngaged_Disengaged" ;
VAL_ 391 DoorsAjar_stat_ISig_5 7 "DoorsAjar_stat_NotAvailable" 6 "DoorsAjar_stat_Error" 5 "DoorsAjar_stat_Spare" 4 "DoorsAjar_stat_BothDoorsAreOpen" 3 "DoorsAjar_stat_PassengerDoorIsOpen" 2 "DoorsAjar_stat_DriverDoorIsOpen" 1 "DoorsAjar_stat_BothDoorsAreClosed" 0 "DoorsAjar_stat_Idle" ;
VAL_ 391 ABSManAutoInhibitionStat_ISig_5 7 "ABSManAutoInhibitionStat_NotAvailable" 6 "ABSManAutoInhibitionStat_Error" 5 "ABSManAutoInhibitionStat_Spare02" 4 "ABSManAutoInhibitionStat_Spare01" 3 "ABSManAutoInhibitionStat_Spare" 2 "ABSManAutoInhibitionStat_ABSAutomaticInhibition" 1 "ABSManAutoInhibitionStat_ABSManualInhibition" 0 "ABSManAutoInhibitionStat_ABSNoInhibition" ;
VAL_ 391 RrInterAxlDiffLockActvnDrvrReq_I 3 "DisengageEngage_NotAvailable" 2 "DisengageEngage_Error" 1 "DisengageEngage_Engage" 0 "DisengageEngage_Disengage" ;
VAL_ 391 EngineOilTempHigh_ISig_5 7 "TempHigh3bit_NotAvailable" 6 "TempHigh3bit_Error" 5 "TempHigh3bit_HighLevel5" 4 "TempHigh3bit_HighLevel4" 3 "TempHigh3bit_HighLevel3" 2 "TempHigh3bit_HighLevel2" 1 "TempHigh3bit_HighLevel1" 0 "TempHigh3bit_OK" ;
VAL_ 391 StartupProhibitStatus_ISig_5 3 "InactiveActive_NotAvailable" 2 "InactiveActive_Error" 1 "InactiveActive_Active" 0 "InactiveActive_Inactive" ;
VAL_ 391 AuxBrakesDwngrdModeInd_rqst 7 "AuxBrakesDwngrdModeInd_rqst_NotAvailable" 6 "AuxBrakesDwngrdModeInd_rqst_Error" 5 "AuxBrakesDwngrdModeInd_rqst_Spare_3" 4 "AuxBrakesDwngrdModeInd_rqst_Spare_2" 3 "AuxBrakesDwngrdModeInd_rqst_Spare_1" 2 "AuxBrakesDwngrdModeInd_rqst_AuxiliaryBrakesShutdown" 1 "AuxBrakesDwngrdModeInd_rqst_ABSDowngradedMode" 0 "AuxBrakesDwngrdModeInd_rqst_NoRequest" ;
VAL_ 391 ElectricalLoadReduction_rqst_ISi 7 "ElectricalLoadReduction_rqst_NotAvailable" 6 "ElectricalLoadReduction_rqst_Error" 5 "ElectricalLoadReduction_rqst_SpareValue_02" 4 "ElectricalLoadReduction_rqst_SpareValue_01" 3 "ElectricalLoadReduction_rqst_SpareValue" 2 "ElectricalLoadReduction_rqst_Level2Request" 1 "ElectricalLoadReduction_rqst_Level1Request" 0 "ElectricalLoadReduction_rqst_NoRequest" ;
VAL_ 391 LoadDistributionChangeACK_ISig_5 7 "LoadDistributionChangeACK_NotAvailable" 6 "LoadDistributionChangeACK_Error" 5 "LoadDistributionChangeACK_SystemDeniedVersatile" 4 "LoadDistributionChangeACK_Reserved_2" 3 "LoadDistributionChangeACK_DeniedDueToDisengagedDifflock" 2 "LoadDistributionChangeACK_LoadShiftDeniedFALIMOverload" 1 "LoadDistributionChangeACK_ChangeAcknowledged" 0 "LoadDistributionChangeACK_NoAction" ;
VAL_ 391 FerryFunctionStatus_ISig_5 7 "FerryFunctionStatus_NotAvailable" 6 "FerryFunctionStatus_Error" 5 "FerryFunctionStatus_Spare_03" 4 "FerryFunctionStatus_Spare_02" 3 "FerryFunctionStatus_Spare_01" 2 "FerryFunctionStatus_FerryFunctionActiveLeveNotlReached" 1 "FerryFunctionStatus_FerryFunctionActiveLevelReached" 0 "FerryFunctionStatus_FerryFunctionNotActive" ;
VAL_ 391 ClutchOverloadStatus_ISig_5 3 "ClutchOverloadStatus_NotAvailable" 2 "ClutchOverloadStatus_Error" 1 "ClutchOverloadStatus_Overloaded" 0 "ClutchOverloadStatus_NotOverloaded" ;
VAL_ 391 RollerBenchModeStatus_ISig_5 3 "InactiveActive_NotAvailable" 2 "InactiveActive_Error" 1 "InactiveActive_Active" 0 "InactiveActive_Inactive" ;
VAL_ 391 LoadDistributionALDChangeACK_ISi 7 "LoadDistributionALDChangeACK_NotAvailable" 6 "LoadDistributionALDChangeACK_Error" 5 "LoadDistributionALDChangeACK_SystemDeniedVersatile" 4 "LoadDistributionALDChangeACK_Spare_01" 3 "LoadDistributionALDChangeACK_Spare" 2 "LoadDistributionALDChangeACK_LoadShiftDeniedOverspeed" 1 "LoadDistributionALDChangeACK_ChangeAcknowledged" 0 "LoadDistributionALDChangeACK_NoAction" ;
VAL_ 391 EngineSpeedControlStatus 7 "EngineSpeedControlStatus_NotAvailable" 6 "EngineSpeedControlStatus_Error" 5 "EngineSpeedControlStatus_Spare_01" 4 "EngineSpeedControlStatus_AutoPtoMin_AutoNeutral" 3 "EngineSpeedControlStatus_CrossCountryEngineSpeedControlActive" 2 "EngineSpeedControlStatus_ActiveExternalSource" 1 "EngineSpeedControlStatus_ActiveManual" 0 "EngineSpeedControlStatus_Inactive" ;
VAL_ 391 DTCActive_ISig_5 3 "DTCActive_DTCStatusInfoNotAvailableOrNotSupported" 2 "DTCActive_ErrorIndicator" 1 "DTCActive_DTCActive" 0 "DTCActive_DTCStatusInfoAvailableButNotActive" ;
VAL_ 390 PS_SevereEngAndBrkOverspdWarn_IS 3 "InactiveActiveSpare_NotAvailable" 2 "InactiveActiveSpare_Spare" 1 "InactiveActiveSpare_Active" 0 "InactiveActiveSpare_Inactive" ;
VAL_ 390 RearFog_Indication 3 "DeviceIndication_SpareValue" 2 "DeviceIndication_Blink" 1 "DeviceIndication_On" 0 "DeviceIndication_Off" ;
VAL_ 390 SasAdaptationInProgress_ISig_5 3 "OffOn_NotAvailable" 2 "OffOn_Error" 1 "OffOn_On" 0 "OffOn_Off" ;
VAL_ 390 SplitBoxDifflockActvnDrvrRqst_IS 3 "DisengageEngage_NotAvailable" 2 "DisengageEngage_Error" 1 "DisengageEngage_Engage" 0 "DisengageEngage_Disengage" ;
VAL_ 390 EcoRollActiveStatus_ISig_5 3 "InactiveActive_NotAvailable" 2 "InactiveActive_Error" 1 "InactiveActive_Active" 0 "InactiveActive_Inactive" ;
VAL_ 390 PloughLampModeStatus_ISig_5 3 "InactiveActive_NotAvailable" 2 "InactiveActive_Error" 1 "InactiveActive_Active" 0 "InactiveActive_Inactive" ;
VAL_ 390 RrRrItrWhlDiffLckActvnDrvrReq_IS 3 "DisengagedEngaged_NotAvailable" 2 "DisengagedEngaged_Error" 1 "DisengagedEngaged_Engaged" 0 "DisengagedEngaged_Disengaged" ;
VAL_ 390 DrvrRetarderBrakeProgram_rqst_IS 3 "OffOn_NotAvailable" 2 "OffOn_Error" 1 "OffOn_On" 0 "OffOn_Off" ;
VAL_ 390 PS_EngOverSpeedSevereWarning_ISi 3 "InactiveActiveSpare_NotAvailable" 2 "InactiveActiveSpare_Spare" 1 "InactiveActiveSpare_Active" 0 "InactiveActiveSpare_Inactive" ;
VAL_ 390 ParkBrakeReleasePossible_stat_IS 3 "ParkBrakeReleasePossible_stat_NotAvailable" 2 "ParkBrakeReleasePossible_stat_Error" 1 "ParkBrakeReleasePossible_stat_Possible_PressureOK" 0 "ParkBrakeReleasePossible_stat_NotPossible_LowerPressure" ;
VAL_ 390 StoreIdleValue_ISig_5 3 "StoreIdleValue_NotAvailable" 2 "StoreIdleValue_Error" 1 "StoreIdleValue_StoreSetValue" 0 "StoreIdleValue_DoNOTStoreValue" ;
VAL_ 390 AutRrAxleDiffLockActvnDrvrReq_IS 3 "DisengageEngage_NotAvailable" 2 "DisengageEngage_Error" 1 "DisengageEngage_Engage" 0 "DisengageEngage_Disengage" ;
VAL_ 390 TransmLowRangeSenseSwitch_ISig_5 3 "OffOn_NotAvailable" 2 "OffOn_Error" 1 "OffOn_On" 0 "OffOn_Off" ;
VAL_ 390 PBStatusDisplay_cmd_ISig_5 3 "DisableEnable_NotAvailable" 2 "DisableEnable_Error" 1 "DisableEnable_Enable" 0 "DisableEnable_Disable" ;
VAL_ 390 AutoRearAxleDiffLockFnc_stat_ISi 3 "InactiveActive_NotAvailable" 2 "InactiveActive_Error" 1 "InactiveActive_Active" 0 "InactiveActive_Inactive" ;
VAL_ 390 PoorBrakePerformanceWarning_ISig 3 "Warning_NotAvailable" 2 "Warning_Error" 1 "Warning_Warning" 0 "Warning_NoWarning" ;
VAL_ 390 FrontParkBrakeOverrideInd_ISig_5 3 "FrontParkBrakeOverrideInd_NotAvailable" 2 "FrontParkBrakeOverrideInd_Error" 1 "FrontParkBrakeOverrideInd_FailedToOverride" 0 "FrontParkBrakeOverrideInd_OK" ;
VAL_ 390 ProhibitControlStatus_ISig_5 3 "InactiveActive_NotAvailable" 2 "InactiveActive_Error" 1 "InactiveActive_Active" 0 "InactiveActive_Inactive" ;
VAL_ 390 PositionLightRequest_status 3 "OffOn_NotAvailable" 2 "OffOn_Error" 1 "OffOn_On" 0 "OffOn_Off" ;
VAL_ 390 DoubleFrontAxleSteeringWarning_I 3 "DoubleFrontAxleSteeringWarning_NotAvailiable" 2 "DoubleFrontAxleSteeringWarning_Error" 1 "DoubleFrontAxleSteeringWarning_DoubleFrAxleSteeringBackupMode" 0 "DoubleFrontAxleSteeringWarning_NoRequest" ;
VAL_ 390 TrailerABSStatus_ISig_5 3 "TrailerABSStatus_NotAvailable" 2 "TrailerABSStatus_ErrorIndicator" 1 "TrailerABSStatus_OK" 0 "TrailerABSStatus_Error" ;
VAL_ 390 LoadCutOffIndication_cmd_ISig_5 3 "LoadCutOffIndication_cmd_NotAvailable" 2 "LoadCutOffIndication_cmd_Error" 1 "LoadCutOffIndication_cmd_LoadCutOffIndication" 0 "LoadCutOffIndication_cmd_NoIndication" ;
VAL_ 390 PtosStatus_ISig_5 3 "PtosStatus_NotAvailable" 2 "PtosStatus_Error" 1 "PtosStatus_OneOrMorePTOEngaged" 0 "PtosStatus_NoPTOEngaged" ;
VAL_ 390 REM_PhoneButtonInd_cmd 3 "DeviceIndication_SpareValue" 2 "DeviceIndication_Blink" 1 "DeviceIndication_On" 0 "DeviceIndication_Off" ;
VAL_ 390 TrailerBrake_Stat_ISig_5 3 "InactiveActive_NotAvailable" 2 "InactiveActive_Error" 1 "InactiveActive_Active" 0 "InactiveActive_Inactive" ;
VAL_ 390 SEM2_PhoneButtonInd_cmd 3 "DeviceIndication_SpareValue" 2 "DeviceIndication_Blink" 1 "DeviceIndication_On" 0 "DeviceIndication_Off" ;
VAL_ 390 GearRangeUnengaged_ISig_5 3 "GearInhibation_NotAvailable" 2 "GearInhibation_Error" 1 "GearInhibation_GearChangeInhibited" 0 "GearInhibation_NoInhibation" ;
VAL_ 390 ABSOffRoadStatus_ISig_5 3 "OffOn_NotAvailable" 2 "OffOn_Error" 1 "OffOn_On" 0 "OffOn_Off" ;
VAL_ 390 DrvrRetarderBrakeBlending_rqst_I 3 "OffOn_NotAvailable" 2 "OffOn_Error" 1 "OffOn_On" 0 "OffOn_Off" ;
VAL_ 389 RearAxleDiffLockActvnDrvrReq_ISi 3 "DisengageEngage_NotAvailable" 2 "DisengageEngage_Error" 1 "DisengageEngage_Engage" 0 "DisengageEngage_Disengage" ;
VAL_ 389 FrRrItrWhlDiffLckActvnDrvrReq_IS 3 "DisengagedEngaged_NotAvailable" 2 "DisengagedEngaged_Error" 1 "DisengagedEngaged_Engaged" 0 "DisengagedEngaged_Disengaged" ;
VAL_ 389 RegenInhibDueHeight_ISig_5 3 "Inhibit_NotAvailable" 2 "Inhibit_Error" 1 "Inhibit_InhibitActive" 0 "Inhibit_NoInhibit" ;
VAL_ 389 DriverLocation_Status_ISig_5 15 "DriverPresenceStatus_NotAvailable" 14 "DriverPresenceStatus_Error" 13 "DriverPresenceStatus_Spare8" 12 "DriverPresenceStatus_Spare7" 11 "DriverPresenceStatus_Spare6" 10 "DriverPresenceStatus_Spare5" 9 "DriverPresenceStatus_Spare4" 8 "DriverPresenceStatus_Spare3" 7 "DriverPresenceStatus_Spare2" 6 "DriverPresenceStatus_Spare1" 5 "DriverPresenceStatus_AutonomousDriver" 4 "DriverPresenceStatus_DriverAtDriverSeat" 3 "DriverPresenceStatus_DriverOutOfCab" 2 "DriverPresenceStatus_RemoteDriver" 1 "DriverPresenceStatus_DriverInCab" 0 "DriverPresenceStatus_NotKnown" ;
VAL_ 389 PoorAirPressureInfo_ISig_5 3 "PoorAirPressureInfo_NotAvailable" 2 "PoorAirPressureInfo_Error" 1 "PoorAirPressureInfo_PoorAirPressure" 0 "PoorAirPressureInfo_NormalPressure" ;
VAL_ 389 XRSLControllerMode_ISig_5 3 "InactiveActive_NotAvailable" 2 "InactiveActive_Error" 1 "InactiveActive_Active" 0 "InactiveActive_Inactive" ;
VAL_ 389 PHTimerRqstAck_DayOfWeekRq 15 "DayOfWeekRq_NotAvailable" 14 "DayOfWeekRq_Error" 13 "DayOfWeekRq_Spare_7" 12 "DayOfWeekRq_Spare_6" 11 "DayOfWeekRq_Spare_5" 10 "DayOfWeekRq_Spare_4" 9 "DayOfWeekRq_Spare_3" 8 "DayOfWeekRq_Spare_2" 7 "DayOfWeekRq_NoDay" 6 "DayOfWeekRq_Sunday" 5 "DayOfWeekRq_Saturday" 4 "DayOfWeekRq_Friday" 3 "DayOfWeekRq_Thursday" 2 "DayOfWeekRq_Wednesday" 1 "DayOfWeekRq_Tuesday" 0 "DayOfWeekRq_Monday" ;
VAL_ 389 PHTimerRqstAck_CurrentOp 3 "CurrentOp_NotAvailable" 2 "CurrentOp_Disabled" 1 "CurrentOp_TemporaryStopped" 0 "CurrentOp_Running" ;
VAL_ 389 DriverLocation_ConfidenceLvl_ISi 3 "LowHigh_NotAvailable" 2 "LowHigh_Error" 1 "LowHigh_High" 0 "LowHigh_Low" ;
VAL_ 389 PS_EngineBrakeOverSpeedWarning_I 3 "InactiveActiveSpare_NotAvailable" 2 "InactiveActiveSpare_Spare" 1 "InactiveActiveSpare_Active" 0 "InactiveActiveSpare_Inactive" ;
VAL_ 389 TrcnCtrlSlipperyRoadWarning_ISig 3 "InactiveActive_NotAvailable" 2 "InactiveActive_Error" 1 "InactiveActive_Active" 0 "InactiveActive_Inactive" ;
VAL_ 389 TransmissionAirPressureLow_ISig_ 3 "TransmissionAirPressureLow_NotAvailable" 2 "TransmissionAirPressureLow_Error" 1 "TransmissionAirPressureLow_AirPressureLow" 0 "TransmissionAirPressureLow_AirPressureOk" ;
VAL_ 158 SecuredNeutralPosition_ISig_5 3 "SecuredNeutralPosition_NotAvailable" 2 "SecuredNeutralPosition_Error" 1 "SecuredNeutralPosition_SecuredNeutralPosition" 0 "SecuredNeutralPosition_NotInSecuredNeutralPosition" ;
VAL_ 158 MirrorSelectLeftWideBtn_stat 3 "PushButtonStatus_NotAvailable" 2 "PushButtonStatus_Error" 1 "PushButtonStatus_Pushed" 0 "PushButtonStatus_Neutral" ;
VAL_ 158 BunkH1AudioOnOff_ButtonStatus 3 "PushButtonStatus_NotAvailable" 2 "PushButtonStatus_Error" 1 "PushButtonStatus_Pushed" 0 "PushButtonStatus_Neutral" ;
VAL_ 158 OverSteerGuidanceStatus_ISig_5 3 "InactiveActive_NotAvailable" 2 "InactiveActive_Error" 1 "InactiveActive_Active" 0 "InactiveActive_Inactive" ;
VAL_ 158 MirrorSelectLeftMainBtn_stat 3 "PushButtonStatus_NotAvailable" 2 "PushButtonStatus_Error" 1 "PushButtonStatus_Pushed" 0 "PushButtonStatus_Neutral" ;
VAL_ 158 LECM_CabClim_Auto_BtnStat 3 "PushButtonStatus_NotAvailable" 2 "PushButtonStatus_Error" 1 "PushButtonStatus_Pushed" 0 "PushButtonStatus_Neutral" ;
VAL_ 158 LECM_Display_Navi_OK_BtnStat 3 "PushButtonStatus_NotAvailable" 2 "PushButtonStatus_Error" 1 "PushButtonStatus_Pushed" 0 "PushButtonStatus_Neutral" ;
VAL_ 158 LECM_CabClim_AC_BtnStat 3 "PushButtonStatus_NotAvailable" 2 "PushButtonStatus_Error" 1 "PushButtonStatus_Pushed" 0 "PushButtonStatus_Neutral" ;
VAL_ 158 LECMCabClimSetTempSelectGuiReq 3 "PushButtonStatus_NotAvailable" 2 "PushButtonStatus_Error" 1 "PushButtonStatus_Pushed" 0 "PushButtonStatus_Neutral" ;
VAL_ 158 MirrorSelectRightMainBtn_stat 3 "PushButtonStatus_NotAvailable" 2 "PushButtonStatus_Error" 1 "PushButtonStatus_Pushed" 0 "PushButtonStatus_Neutral" ;
VAL_ 158 DaytimeRunningLight_Indication 3 "DeviceIndication_SpareValue" 2 "DeviceIndication_Blink" 1 "DeviceIndication_On" 0 "DeviceIndication_Off" ;
VAL_ 158 DrivingLight_Indication 3 "DeviceIndication_SpareValue" 2 "DeviceIndication_Blink" 1 "DeviceIndication_On" 0 "DeviceIndication_Off" ;
VAL_ 158 FrontFog_Indication 3 "DeviceIndication_SpareValue" 2 "DeviceIndication_Blink" 1 "DeviceIndication_On" 0 "DeviceIndication_Off" ;
VAL_ 158 KeyfobPreTripButtonStatus 3 "PushButtonStatus_NotAvailable" 2 "PushButtonStatus_Error" 1 "PushButtonStatus_Pushed" 0 "PushButtonStatus_Neutral" ;
VAL_ 158 MirrorSelectRightWideBtn_stat 3 "PushButtonStatus_NotAvailable" 2 "PushButtonStatus_Error" 1 "PushButtonStatus_Pushed" 0 "PushButtonStatus_Neutral" ;
VAL_ 158 ParkingLight_Indication 3 "DeviceIndication_SpareValue" 2 "DeviceIndication_Blink" 1 "DeviceIndication_On" 0 "DeviceIndication_Off" ;
VAL_ 158 DrivingLightPlus_Indication 3 "DeviceIndication_SpareValue" 2 "DeviceIndication_Blink" 1 "DeviceIndication_On" 0 "DeviceIndication_Off" ;
VAL_ 158 BlackPanelMode_ButtonStatus 3 "PushButtonStatus_NotAvailable" 2 "PushButtonStatus_Error" 1 "PushButtonStatus_Pushed" 0 "PushButtonStatus_Neutral" ;
VAL_ 158 ParkBrakeActuationStatus_ISig_5 7 "ParkBrakeActuationStatus_NotAvailable" 6 "ParkBrakeActuationStatus_Error" 5 "ParkBrakeActuationStatus_SpareValue_01" 4 "ParkBrakeActuationStatus_SpareValue" 3 "ParkBrakeActuationStatus_AntiCompound" 2 "ParkBrakeActuationStatus_Parked" 1 "ParkBrakeActuationStatus_PartiallyParked" 0 "ParkBrakeActuationStatus_Released" ;
VAL_ 158 LECM_CabClim_FrPwr_BtnStat 3 "PushButtonStatus_NotAvailable" 2 "PushButtonStatus_Error" 1 "PushButtonStatus_Pushed" 0 "PushButtonStatus_Neutral" ;
VAL_ 158 LECM_CabClim_Pwr_BtnStat 3 "PushButtonStatus_NotAvailable" 2 "PushButtonStatus_Error" 1 "PushButtonStatus_Pushed" 0 "PushButtonStatus_Neutral" ;
VAL_ 158 BlackPanelMode_ButtonStatus3 3 "PushButtonStatus_NotAvailable" 2 "PushButtonStatus_Error" 1 "PushButtonStatus_Pushed" 0 "PushButtonStatus_Neutral" ;
VAL_ 158 LECM_CabClim_Sync_GuiReq 3 "PushButtonStatus_NotAvailable" 2 "PushButtonStatus_Error" 1 "PushButtonStatus_Pushed" 0 "PushButtonStatus_Neutral" ;
VAL_ 158 LiftAxle1AutoLiftSelected_ISig_5 3 "FalseTrue_NotAvaiable" 2 "FalseTrue_Error" 1 "FalseTrue_True" 0 "FalseTrue_False" ;
VAL_ 158 LECM_Ent_OnOff_BtnStat 3 "PushButtonStatus_NotAvailable" 2 "PushButtonStatus_Error" 1 "PushButtonStatus_Pushed" 0 "PushButtonStatus_Neutral" ;
VAL_ 156 LiftAxle2LowerACK_ISig_5 7 "LiftAxle2LowerACK_NotAvailable" 6 "LiftAxle2LowerACK_Error" 5 "LiftAxle2LowerACK_SystemDeniedVersatile" 4 "LiftAxle2LowerACK_Spare_01" 3 "LiftAxle2LowerACK_Spare" 2 "LiftAxle2LowerACK_LowerDeniedRAS_EC" 1 "LiftAxle2LowerACK_ChangeAcknowledged" 0 "LiftAxle2LowerACK_NoAction" ;
VAL_ 156 LiftAxle2PositionStatus_ISig_5 7 "LiftAxlePositionStatus_NotAvailable" 6 "LiftAxlePositionStatus_Error" 5 "LiftAxlePositionStatus_Reserved_01" 4 "LiftAxlePositionStatus_Reserved" 3 "LiftAxlePositionStatus_Lifting" 2 "LiftAxlePositionStatus_Lowering" 1 "LiftAxlePositionStatus_Lifted" 0 "LiftAxlePositionStatus_Lowered" ;
VAL_ 156 LiftAxle2LiftFuncSelected_ISig_5 7 "LiftAxleLiftAutoFuncSelected_NotAvailable" 6 "LiftAxleLiftAutoFuncSelected_Error" 5 "LiftAxleLiftAutoFuncSelected_Reserved" 4 "LiftAxleLiftAutoFuncSelected_UnlimitedLift" 3 "LiftAxleLiftAutoFuncSelected_LiftOverload" 2 "LiftAxleLiftAutoFuncSelected_LiftPlus30" 1 "LiftAxleLiftAutoFuncSelected_Lift" 0 "LiftAxleLiftAutoFuncSelected_NoLift" ;
VAL_ 156 PassengerDoorAjar_stat 7 "DoorAjar_stat_NotAvailable" 6 "DoorAjar_stat_Error" 2 "DoorAjar_stat_DoorOpen" 1 "DoorAjar_stat_DoorClosed" 0 "DoorAjar_stat_Idle" ;
VAL_ 156 LevelControlInformation_ISig_5 15 "LevelControlInformation_NotAvailable" 14 "LevelControlInformation_Error" 13 "LevelControlInformation_Reserved_06" 12 "LevelControlInformation_Reserved_05" 11 "LevelControlInformation_Reserved_04" 10 "LevelControlInformation_Reserved_03" 9 "LevelControlInformation_Reserved_02" 8 "LevelControlInformation_Reserved_01" 7 "LevelControlInformation_Reserved" 6 "LevelControlInformation_LimpHome" 5 "LevelControlInformation_FerryFunction" 4 "LevelControlInformation_KneelingHeight" 3 "LevelControlInformation_DriveHeight" 2 "LevelControlInformation_DockingHeight" 1 "LevelControlInformation_HeightAdjustment" 0 "LevelControlInformation_Prohibit" ;
VAL_ 156 LiftAxle1LowerACK_ISig_5 7 "LiftAxle1LowerACK_NotAvailable" 6 "LiftAxle1LowerACK_Error" 5 "LiftAxle1LowerACK_SystemDeniedVersatile" 4 "LiftAxle1LowerACK_Spare_01" 3 "LiftAxle1LowerACK_Spare" 2 "LiftAxle1LowerACK_LowerDeniedRAS_EC" 1 "LiftAxle1LowerACK_ChangeAcknowledged" 0 "LiftAxle1LowerACK_NoAction" ;
VAL_ 156 WiperModeStatus_ISig_5 7 "WiperModeStatus_NotAvailable" 6 "WiperModeStatus_ErrorIndicator" 5 "WiperModeStatus_Spare02" 4 "WiperModeStatus_Spare01" 3 "WiperModeStatus_Spare" 2 "WiperModeStatus_HighSpeedWiping" 1 "WiperModeStatus_LowSpeedWiping" 0 "WiperModeStatus_WiperOff" ;
VAL_ 156 Washing_HMI_rqst 3 "InactiveActive_NotAvailable" 2 "InactiveActive_Error" 1 "InactiveActive_Active" 0 "InactiveActive_Inactive" ;
VAL_ 156 LiftAxle2AutoLiftSelected_ISig_5 3 "FalseTrue_NotAvaiable" 2 "FalseTrue_Error" 1 "FalseTrue_True" 0 "FalseTrue_False" ;
VAL_ 156 ReverseGearEngaged_ISig_5 3 "ReverseGearEngaged_NotAvailable" 2 "ReverseGearEngaged_Error" 1 "ReverseGearEngaged_ReverseGearEngaged" 0 "ReverseGearEngaged_ReverseGearNotEngaged" ;
VAL_ 156 LiftAxle1PositionStatus_ISig_5 7 "LiftAxlePositionStatus_NotAvailable" 6 "LiftAxlePositionStatus_Error" 5 "LiftAxlePositionStatus_Reserved_01" 4 "LiftAxlePositionStatus_Reserved" 3 "LiftAxlePositionStatus_Lifting" 2 "LiftAxlePositionStatus_Lowering" 1 "LiftAxlePositionStatus_Lifted" 0 "LiftAxlePositionStatus_Lowered" ;
VAL_ 156 ACC_Status_ISig_5 7 "ACC_Status_NotAvailable" 6 "ACC_Status_Error" 5 "ACC_Status_ACCFailureAndInactive" 4 "ACC_Status_Reserved" 3 "ACC_Status_ActiveWithLimitedBrakeCapacity" 2 "ACC_Status_ActiveECONOMYMODE" 1 "ACC_Status_ActiveSTANDARDMODE" 0 "ACC_Status_Inactive" ;
VAL_ 156 LECM_CabClim_MaxDef_GuiReq 3 "PushButtonStatus_NotAvailable" 2 "PushButtonStatus_Error" 1 "PushButtonStatus_Pushed" 0 "PushButtonStatus_Neutral" ;
VAL_ 156 RegenerationSwitchStatus 7 "A3PosSwitchStatus_NotAvailable" 6 "A3PosSwitchStatus_Error" 5 "A3PosSwitchStatus_Spare_02" 4 "A3PosSwitchStatus_Spare_01" 3 "A3PosSwitchStatus_Spare" 2 "A3PosSwitchStatus_Upper" 1 "A3PosSwitchStatus_Lower" 0 "A3PosSwitchStatus_Middle" ;
VAL_ 156 DSWindowPosition 7 "WindowPosition_NotAvailable" 6 "WindowPosition_Error" 5 "WindowPosition_Spare" 4 "WindowPosition_UnknownPosition" 3 "WindowPosition_Open_70_100Percent" 2 "WindowPosition_Open_30_70Percent" 1 "WindowPosition_Open_0_30Percent" 0 "WindowPosition_Closed" ;
VAL_ 156 GearSplit_Status_ISig_5 3 "GearSplit_Status_NotAvailable" 2 "GearSplit_Status_Error" 1 "GearSplit_Status_HighSplit" 0 "GearSplit_Status_LowSplit" ;
VAL_ 156 KeyPosition_ISig_5 7 "KeyPosition_NotAvailable" 6 "KeyPosition_ErrorIndicator" 5 "KeyPosition_IgnitionKeyInCrankPosition" 4 "KeyPosition_IgnitionKeyInPreheatPosition" 3 "KeyPosition_IgnitionKeyIn15PositionNormalDrivingPosition" 2 "KeyPosition_IgnitionKeyInAccessoryPosition" 1 "KeyPosition_IgnitionKeyInOffPosition" 0 "KeyPosition_KeyOut" ;
VAL_ 156 LiftAxle1LiftFuncSelected_ISig_5 7 "LiftAxleLiftAutoFuncSelected_NotAvailable" 6 "LiftAxleLiftAutoFuncSelected_Error" 5 "LiftAxleLiftAutoFuncSelected_Reserved" 4 "LiftAxleLiftAutoFuncSelected_UnlimitedLift" 3 "LiftAxleLiftAutoFuncSelected_LiftOverload" 2 "LiftAxleLiftAutoFuncSelected_LiftPlus30" 1 "LiftAxleLiftAutoFuncSelected_Lift" 0 "LiftAxleLiftAutoFuncSelected_NoLift" ;
VAL_ 156 LiftAxle2UpRequestACK_ISig_5 7 "LiftAxleUpRequestACK_NotAvailable" 6 "LiftAxleUpRequestACK_Error" 5 "LiftAxleUpRequestACK_SystemDeniedVersatile" 4 "LiftAxleUpRequestACK_LiftDeniedPBrakeActive" 3 "LiftAxleUpRequestACK_LiftDeniedRearOverload" 2 "LiftAxleUpRequestACK_LiftDeniedFrontOverload" 1 "LiftAxleUpRequestACK_ChangeAcknowledged" 0 "LiftAxleUpRequestACK_NoAction" ;
VAL_ 156 PreTrip_ButtonStat3 3 "PushButtonStatus_NotAvailable" 2 "PushButtonStatus_Error" 1 "PushButtonStatus_Pushed" 0 "PushButtonStatus_Neutral" ;
VAL_ 156 LiftAxle1UpRequestACK_ISig_5 7 "LiftAxleUpRequestACK_NotAvailable" 6 "LiftAxleUpRequestACK_Error" 5 "LiftAxleUpRequestACK_SystemDeniedVersatile" 4 "LiftAxleUpRequestACK_LiftDeniedPBrakeActive" 3 "LiftAxleUpRequestACK_LiftDeniedRearOverload" 2 "LiftAxleUpRequestACK_LiftDeniedFrontOverload" 1 "LiftAxleUpRequestACK_ChangeAcknowledged" 0 "LiftAxleUpRequestACK_NoAction" ;
VAL_ 154 AutonomyAuthorizationDevInd_ISig 3 "DeviceIndication_SpareValue" 2 "DeviceIndication_Blink" 1 "DeviceIndication_On" 0 "DeviceIndication_Off" ;
VAL_ 154 GearLeverPosition_ISig_5 15 "GearLeverPosition_NotAvailable" 14 "GearLeverPosition_Error" 13 "GearLeverPosition_SpareValue_06" 12 "GearLeverPosition_SpareValue_05" 11 "GearLeverPosition_SpareValue_04" 10 "GearLeverPosition_SpareValue_03" 9 "GearLeverPosition_SpareValue_02" 8 "GearLeverPosition_SpareValue_01" 7 "GearLeverPosition_SpareValue" 6 "GearLeverPosition_SEG6" 5 "GearLeverPosition_LowGear" 4 "GearLeverPosition_Manual" 3 "GearLeverPosition_Automatic" 2 "GearLeverPosition_Neutral" 1 "GearLeverPosition_Reverse" 0 "GearLeverPosition_GearFoldedAway" ;
VAL_ 138 AcceleratorPedalLowIdleSwitch_IS 3 "AcceleratorPedalLowIdleSwitch_NotAvailable" 2 "AcceleratorPedalLowIdleSwitch_Error" 1 "AcceleratorPedalLowIdleSwitch_INLowIdleCondition" 0 "AcceleratorPedalLowIdleSwitch_NotInLowIdleCondition" ;
VAL_ 138 VehicleMode_ISig_5 15 "VehicleMode_NotAvailable" 14 "VehicleMode_Error" 13 "VehicleMode_Spare_7" 12 "VehicleMode_Spare_6" 11 "VehicleMode_Spare_5" 10 "VehicleMode_Spare_4" 9 "VehicleMode_Spare_3" 8 "VehicleMode_Spare_2" 7 "VehicleMode_Spare_1" 6 "VehicleMode_Running" 5 "VehicleMode_Cranking" 4 "VehicleMode_PreRunning" 3 "VehicleMode_Accessory" 2 "VehicleMode_Living" 1 "VehicleMode_Parked" 0 "VehicleMode_Hibernate" ;
VAL_ 138 AcceleratorPedalQuality_ISig_5 3 "PrimaryAcceleratorPedalQuality_NotAvailable" 2 "PrimaryAcceleratorPedalQuality_ErrorMode" 1 "PrimaryAcceleratorPedalQuality_DowngradedMode" 0 "PrimaryAcceleratorPedalQuality_NormalMode" ;
VAL_ 895 DriverCrank_rqst 3 "Request_NotAvailable" 2 "Request_Error" 1 "Request_RequestActive" 0 "Request_NotRequested" ;
VAL_ 895 ExtStaticTrailerBrake_Stat 3 "InactiveActive_NotAvailable" 2 "InactiveActive_Error" 1 "InactiveActive_Active" 0 "InactiveActive_Inactive" ;
VAL_ 895 CabTiltLockStatus 3 "UnlockedLocked_NotAvailable" 2 "UnlockedLocked_Error" 1 "UnlockedLocked_Locked" 0 "UnlockedLocked_Unlocked" ;
VAL_ 895 CabTiltEnableStatus 3 "DisableEnable_NotAvailable" 2 "DisableEnable_Error" 1 "DisableEnable_Enable" 0 "DisableEnable_Disable" ;
VAL_ 1104 CabTilt_rqst 3 "InactiveActive_NotAvailable" 2 "InactiveActive_Error" 1 "InactiveActive_Active" 0 "InactiveActive_Inactive" ;
VAL_ 1104 PassengersSeatBelt_ISig_5 7 "PassengersSeatBelt_NotAvailable" 6 "PassengersSeatBelt_Error" 5 "PassengersSeatBelt_Spare3" 4 "PassengersSeatBelt_Spare2" 3 "PassengersSeatBelt_Spare1" 2 "PassengersSeatBelt_PassengersNotSeated" 1 "PassengersSeatBelt_PassengersFastened" 0 "PassengersSeatBelt_AtLeastOnePassengerSeatedNotFastened" ;
VAL_ 434 RideHeightFunctionRequest_ISig_5 15 "RideHeightFunction_NotAvailable" 14 "RideHeightFunction_ErrorIndicator" 13 "RideHeightFunction_NotDefined_05" 12 "RideHeightFunction_NotDefined_04" 11 "RideHeightFunction_NotDefined_03" 10 "RideHeightFunction_NotDefined_02" 9 "RideHeightFunction_NotDefined_01" 8 "RideHeightFunction_NotDefined" 7 "RideHeightFunction_AlternativeDrivePosition2" 6 "RideHeightFunction_AlternativeDrivePosition1" 5 "RideHeightFunction_LowDrivePosition" 4 "RideHeightFunction_HighDrivePosition" 3 "RideHeightFunction_SpeedDependentDrivePosition" 2 "RideHeightFunction_AlternativeDrivePosition" 1 "RideHeightFunction_StandardDrivePosition" 0 "RideHeightFunction_Inactive" ;
VAL_ 434 AdjustFrontBeamInclination 7 "A3PosSwitchStatus_NotAvailable" 6 "A3PosSwitchStatus_Error" 5 "A3PosSwitchStatus_Spare_02" 4 "A3PosSwitchStatus_Spare_01" 3 "A3PosSwitchStatus_Spare" 2 "A3PosSwitchStatus_Upper" 1 "A3PosSwitchStatus_Lower" 0 "A3PosSwitchStatus_Middle" ;
VAL_ 434 ExtraMainbeam_SwitchStatus 3 "A2PosSwitchStatus_NotAvailable" 2 "A2PosSwitchStatus_Error" 1 "A2PosSwitchStatus_On" 0 "A2PosSwitchStatus_Off" ;
VAL_ 434 StopLevelChangeRequest_ISig_5 3 "Request_NotAvailable" 2 "Request_Error" 1 "Request_RequestActive" 0 "Request_NotRequested" ;
VAL_ 432 StatTrailerBrakeSwitchStatus 3 "PushButtonStatus_NotAvailable" 2 "PushButtonStatus_Error" 1 "PushButtonStatus_Pushed" 0 "PushButtonStatus_Neutral" ;
VAL_ 432 DRLOverride_SwitchStatus 3 "PushButtonStatus_NotAvailable" 2 "PushButtonStatus_Error" 1 "PushButtonStatus_Pushed" 0 "PushButtonStatus_Neutral" ;
VAL_ 432 DriverSeatBeltSwitch_ISig_5 3 "DriverSeatBeltSwitch_NotAvailable" 2 "DriverSeatBeltSwitch_Error" 1 "DriverSeatBeltSwitch_SeatBeltBuckledFastened" 0 "DriverSeatBeltSwitch_SeatBeltUnbuckledUnfastened" ;
VAL_ 432 DumpSwitchChangeReq_ISig_5 3 "DumpSwitchChangeReq_NotAvailable" 2 "DumpSwitchChangeReq_Error" 1 "DumpSwitchChangeReq_ChangeDumpFunction" 0 "DumpSwitchChangeReq_NoAction" ;
VAL_ 432 StaticCornerLightMode 3 "DisableEnable_NotAvailable" 2 "DisableEnable_Error" 1 "DisableEnable_Enable" 0 "DisableEnable_Disable" ;
VAL_ 432 FrontLidAjar_Stat 3 "ClosedOpen_NotAvailable" 2 "ClosedOpen_Error" 1 "ClosedOpen_Open" 0 "ClosedOpen_Closed" ;
VAL_ 432 LoadDistributionRequested_ISig_5 15 "LoadDistributionRequested_NotAvailable" 14 "LoadDistributionRequested_Error" 13 "LoadDistributionRequested_Reserved5" 12 "LoadDistributionRequested_Reserved4" 11 "LoadDistributionRequested_Reserved3" 10 "LoadDistributionRequested_Reserved2" 9 "LoadDistributionRequested_Reserved1" 8 "LoadDistributionRequested_DelpressLoadDistribution" 7 "LoadDistributionRequested_VariableLoadDistribution" 6 "LoadDistributionRequested_AlternativeLoadDistribution" 5 "LoadDistributionRequested_MaximumTraction2" 4 "LoadDistributionRequested_MaximumTraction1" 3 "LoadDistributionRequested_OptimizedTraction" 2 "LoadDistributionRequested_NormalLoadDistribution" 1 "LoadDistributionRequested_DefaultLoadDistribution" 0 "LoadDistributionRequested_NoAction" ;
VAL_ 432 LevelingThumbwheel_stat 31 "Thumbwheel_stat_NotAvaliable" 30 "Thumbwheel_stat_Error" 29 "Thumbwheel_stat_Spare_12" 28 "Thumbwheel_stat_Spare_11" 27 "Thumbwheel_stat_Spare_10" 26 "Thumbwheel_stat_Spare_09" 25 "Thumbwheel_stat_Spare_08" 24 "Thumbwheel_stat_Spare_07" 23 "Thumbwheel_stat_Spare_06" 22 "Thumbwheel_stat_Spare_05" 21 "Thumbwheel_stat_Spare_04" 20 "Thumbwheel_stat_Spare_03" 19 "Thumbwheel_stat_Spare_02" 18 "Thumbwheel_stat_Spare_01" 17 "Thumbwheel_stat_Spare" 16 "Thumbwheel_stat_ThumbWheelPos16" 15 "Thumbwheel_stat_ThumbWheelPos15" 14 "Thumbwheel_stat_ThumbWheelPos14" 13 "Thumbwheel_stat_ThumbWheelPos13" 12 "Thumbwheel_stat_ThumbWheelPos12" 11 "Thumbwheel_stat_ThumbWheelPos11" 10 "Thumbwheel_stat_ThumbWheelPos10" 9 "Thumbwheel_stat_ThumbWheelPos9" 8 "Thumbwheel_stat_ThumbWheelPos8" 7 "Thumbwheel_stat_ThumbWheelPos7" 6 "Thumbwheel_stat_ThumbWheelPos6" 5 "Thumbwheel_stat_ThumbWheelPos5" 4 "Thumbwheel_stat_ThumbWheelPos4" 3 "Thumbwheel_stat_ThumbWheelPos3" 2 "Thumbwheel_stat_ThumbWheelPos2" 1 "Thumbwheel_stat_ThumbWheelPos1" 0 "Thumbwheel_stat_ThumbWheelPos0" ;
SIG_GROUP_ 688 APMSafetyWarning_sg_ISig_5 1 : APMSafetyWarning_CRC_ISig_5 APMSafetyWarning_RedRqst_ISig_5 APMSafetyWarning_SqC_ISig_5 APMSafetyWarning_YellowRqst_ISig;
SIG_GROUP_ 688 GearShiftingRec_sg_ISig_5 1 : GearShiftingRec_Steps_ISig_5 GearShiftingRec_Direction_ISig_5;
SIG_GROUP_ 688 PBStatus_sg_ISig_5 1 : PBStatus_CRC_ISig_5 PBStatus_Actuation_ISig_5 PBStatus_IntegrityLvl_ISig_5 PBStatus_SqC_ISig_5;
SIG_GROUP_ 688 RearPropulsionStat_sg_ISig_5 1 : RearPropulsionStat_Rear2Axle_ISi RearPropulsionStat_Rear1Axle_ISi RearPropulsionStat_Rear3Axle_ISi;
SIG_GROUP_ 394 FPBRMMIStat_sg_ISig_5 1 : FPBRMMIStat_FPBRStatusInd_ISig_5 FPBRMMIStat_FPBRChangeAck_ISig_5;
SIG_GROUP_ 389 DriverLocation_sg_ISig_5 1 : DriverLocation_CRC_ISig_5 DriverLocation_Status_ISig_5 DriverLocation_SqC_ISig_5 DriverLocation_ConfidenceLvl_ISi;
SIG_GROUP_ 389 PHTimerRqstAck_sg 1 : PHTimerRqstAck_Minutes PHTimerRqstAck_Hours PHTimerRqstAck_DayOfWeekRq PHTimerRqstAck_CurrentOp;
SIG_GROUP_ 895 WheelBasedVehicleSpd_sg_ISig_5 1 : WheelBasedVehicleSpd_Value_ISig_ WheelBasedVehicleSpd_CRC_ISig_5 WheelBasedVehicleSpd_SqC_ISig_5;
